VERSION ""

NS_ :

BS_:

BU_: VCU EAC EDS EPS BMS DCDC EVCC OBC

BO_ 374 BMS_HVMeas1_0x176: 8 BMS
 SG_ Checksum_0x176 : 7|8@0+ (1,0) [0|255] ""  VCU,EDS,EVCC
 SG_ Rolling_Counter_0x176 : 11|4@0+ (1,0) [0|15] ""  VCU,EDS,EVCC
 SG_ BMS_HVLinkVol_MEAS : 39|16@0+ (0.1,0) [0|800] "V"  VCU,EVCC
 SG_ BMS_HVPackVol_MEAS : 23|16@0+ (0.1,0) [0|800] "V"  VCU,EDS,EVCC

BO_ 375 BMS_HVMeas2_0x177: 8 BMS
 SG_ Checksum_0x177 : 7|8@0+ (1,0) [0|255] ""  VCU,EVCC
 SG_ Rolling_Counter_0x177 : 11|4@0+ (1,0) [0|15] ""  VCU,EVCC
 SG_ BMS_HVBusVol_MEAS : 23|16@0+ (0.1,0) [0|800] "V"  VCU,EVCC
 SG_ BMS_HVFuseVol_MEAS : 39|16@0+ (0.1,0) [0|800] "V"  VCU,EVCC

BO_ 372 BMS_CurMeas_0x174: 8 BMS
 SG_ Checksum_0x174 : 7|8@0+ (1,0) [0|255] ""  VCU,EVCC
 SG_ Rolling_Counter_0x174 : 11|4@0+ (1,0) [0|15] ""  VCU,EVCC
 SG_ BMS_PackCur_MEAS : 23|16@0+ (0.1,-3276.8) [-3276.8|3276.7] "A"  VCU,EVCC
 SG_ BMS_AllowDischgCurr : 39|16@0+ (0.1,0) [0|1500] "A"  VCU,EVCC
 SG_ BMS_AllowDischgCurrPeak : 55|16@0+ (0.1,0) [0|1500] "A"  VCU,EVCC

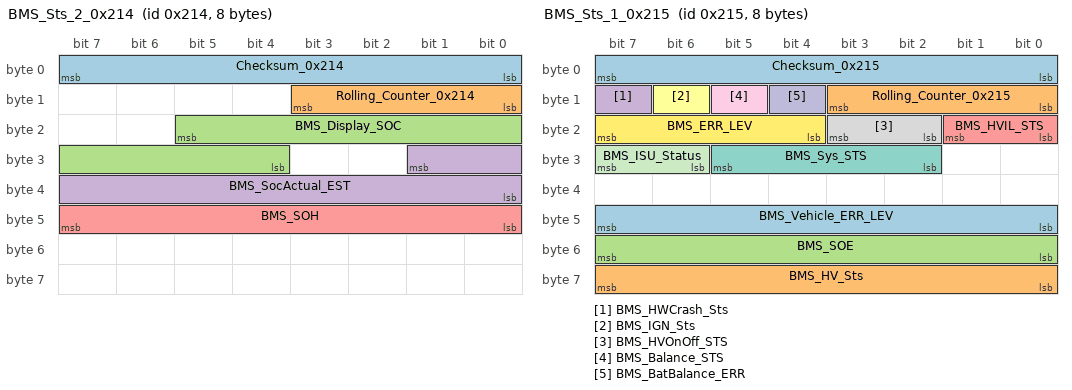
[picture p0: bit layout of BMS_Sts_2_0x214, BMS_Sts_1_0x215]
BO_ 532 BMS_Sts_2_0x214: 8 BMS
 SG_ Checksum_0x214 : 7|8@0+ (1,0) [0|255] ""  VCU,EVCC
 SG_ Rolling_Counter_0x214 : 11|4@0+ (1,0) [0|15] ""  VCU,EVCC
 SG_ BMS_Display_SOC : 21|10@0+ (0.1,0) [0|100] "%"  VCU,EVCC
 SG_ BMS_SocActual_EST : 25|10@0+ (0.1,0) [0|100] "percent"  VCU,EDS,EVCC
 SG_ BMS_SOH : 47|8@0+ (0.5,0) [0|100] "%"  VCU,EDS,EVCC

BO_ 533 BMS_Sts_1_0x215: 8 BMS
 SG_ Checksum_0x215 : 7|8@0+ (1,0) [0|255] ""  VCU,EDS,DCDC,EVCC
 SG_ Rolling_Counter_0x215 : 11|4@0+ (1,0) [0|15] ""  VCU,EDS,DCDC,EVCC
 SG_ BMS_SOE : 55|8@0+ (0.5,0) [0|100] "%"  VCU,EVCC
 SG_ BMS_HWCrash_Sts : 15|1@0+ (1,0) [0|1] ""  VCU,DCDC,EVCC
 SG_ BMS_HVIL_STS : 17|2@0+ (1,0) [0|3] ""  VCU,EDS,DCDC,EVCC
 SG_ BMS_IGN_Sts : 14|1@0+ (1,0) [0|1] ""  VCU,EDS,EVCC
 SG_ BMS_Sys_STS : 29|4@0+ (1,0) [0|15] ""  VCU,EDS,EVCC
 SG_ BMS_HVOnOff_STS : 19|2@0+ (1,0) [0|3] ""  VCU,EDS,DCDC,EVCC
 SG_ BMS_Balance_STS : 13|1@0+ (1,0) [0|1] ""  VCU,EDS,EVCC
 SG_ BMS_BatBalance_ERR : 12|1@0+ (1,0) [0|1] ""  VCU,EDS,EVCC
 SG_ BMS_ISU_Status : 31|2@0+ (1,0) [0|3] ""  VCU,EDS,EVCC
 SG_ BMS_ERR_LEV : 23|4@0+ (1,0) [0|15] ""  VCU,EDS,EVCC
 SG_ BMS_Vehicle_ERR_LEV : 47|8@0+ (1,0) [0|15] ""  VCU,EDS,EVCC
 SG_ BMS_HV_Sts : 63|8@0+ (1,0) [0|255] ""  VCU,EVCC

BO_ 549 BMS_FaultMgr_0x225: 8 BMS
 SG_ Checksum_0x225 : 7|8@0+ (1,0) [0|255] ""  VCU,EVCC
 SG_ Rolling_Counter_0x225 : 11|4@0+ (1,0) [0|15] ""  VCU,EVCC
 SG_ CDM_bAcvCanComStblMon : 12|1@0+ (1,0) [0|1] ""  VCU,EVCC
 SG_ FRMo_bErrHvbatStReqExtMon : 13|1@0+ (1,0) [0|1] ""  VCU,EVCC
 SG_ FRMo_bErrChrgnAllwdExtMon : 14|1@0+ (1,0) [0|1] ""  VCU,EVCC
 SG_ FRMo_bErrVehCrashStExtMon : 15|1@0+ (1,0) [0|1] ""  VCU,EVCC
 SG_ CDM_bErrComctnLossCanMon : 16|1@0+ (1,0) [0|1] ""  VCU,EVCC
 SG_ CTCMon_bErrCtctrSopcMon : 17|1@0+ (1,0) [0|1] ""  VCU,EVCC
 SG_ CTCMon_bInvldCtctrHisdIFbMon : 18|1@0+ (1,0) [0|1] ""  VCU,EVCC
 SG_ CTCMon_bInvldCtctrLosdUFbMon : 19|1@0+ (1,0) [0|1] ""  VCU,EVCC
 SG_ CTM_bErrCellTDifMaxMon : 20|1@0+ (1,0) [0|1] ""  VCU,EVCC
 SG_ CTM_bErrCellTMaxMon : 21|1@0+ (1,0) [0|1] ""  VCU,EVCC
 SG_ CTM_bErrCellTMinMon : 22|1@0+ (1,0) [0|1] ""  VCU,EVCC
 SG_ CTM_bErrThrwyPredMon : 23|1@0+ (1,0) [0|1] ""  VCU,EVCC
 SG_ CUM_bErrCellUDifMaxMon : 24|1@0+ (1,0) [0|1] ""  VCU,EVCC
 SG_ CUM_bErrCellUMaxMon : 25|1@0+ (1,0) [0|1] ""  VCU,EVCC
 SG_ CUM_bErrCellUMinMon : 26|1@0+ (1,0) [0|1] ""  VCU,EVCC
 SG_ CUM_bErrCellUProtnMaxNvMon : 27|1@0+ (1,0) [0|1] ""  VCU,EVCC
 SG_ CUM_bErrCellUProtnMinNvMon : 28|1@0+ (1,0) [0|1] ""  VCU,EVCC
 SG_ CUM_bErrPackUImplyMon : 29|1@0+ (1,0) [0|1] ""  VCU,EVCC
 SG_ EHPMon_bRdyHvilMon : 30|1@0+ (1,0) [0|1] ""  VCU,EVCC
 SG_ EHPMon_bErrWlddNegNvMon : 31|1@0+ (1,0) [0|1] ""  VCU,EVCC
 SG_ EHPMon_bErrWlddPosNvMon : 32|1@0+ (1,0) [0|1] ""  VCU,EVCC
 SG_ EHPMon_bErrWlddPrechNvMon : 33|1@0+ (1,0) [0|1] ""  VCU,EVCC
 SG_ EHPMon_bErrHvilMon : 34|1@0+ (1,0) [0|1] ""  VCU,EVCC
 SG_ EHPMon_bErrHvilShoMon : 35|1@0+ (1,0) [0|1] ""  VCU,EVCC
 SG_ EHPMon_bErrPackIslnRNvMon : 36|1@0+ (1,0) [0|1] ""  VCU,EVCC
 SG_ EHPMon_bErrVehCrashNvMon : 37|1@0+ (1,0) [0|1] ""  VCU,EVCC
 SG_ EHPMon_bErrVehIslnRNvMon : 38|1@0+ (1,0) [0|1] ""  VCU,EVCC
 SG_ FRMo_bErrMemStorgNvMon : 39|1@0+ (1,0) [0|1] ""  VCU,EVCC
 SG_ L1IM_bErrClmp30MaxMonInp : 40|1@0+ (1,0) [0|1] ""  VCU,EVCC
 SG_ L1IM_bErrClmp30MinMonInp : 41|1@0+ (1,0) [0|1] ""  VCU,EVCC
 SG_ L1IM_bErrCtctrDtrtMonInp : 42|1@0+ (1,0) [0|1] ""  VCU,EVCC
 SG_ L1IM_bErrUActImplyMonInp : 43|1@0+ (1,0) [0|1] ""  VCU,EVCC
 SG_ MCCM_bAcvMdulCtlrStsMon : 44|1@0+ (1,0) [0|1] ""  VCU,EVCC
 SG_ MCCM_bErrLntecSngFltMon : 45|1@0+ (1,0) [0|1] ""  VCU,EVCC
 SG_ MCCM_bErrLntecLtntFltMon : 46|1@0+ (1,0) [0|1] ""  VCU,EVCC
 SG_ MCCM_bErrMdulCellSnsrCfgMon : 47|1@0+ (1,0) [0|1] ""  VCU,EVCC
 SG_ MCCM_bErrMdulCtlrComMon : 48|1@0+ (1,0) [0|1] ""  VCU,EVCC
 SG_ MCCM_bErrSnsrTEltlMon : 49|1@0+ (1,0) [0|1] ""  VCU,EVCC
 SG_ MCCM_bWarnSnsrTEltlMon : 50|1@0+ (1,0) [0|1] ""  VCU,EVCC
 SG_ PCM_bRdySnsrIMon : 51|1@0+ (1,0) [0|1] ""  VCU,EVCC
 SG_ PCM_bErrPackEFlowMaxLimMon : 52|1@0+ (1,0) [0|1] ""  VCU,EVCC
 SG_ PCM_bErrPackIChDchaMaxLimMon : 53|1@0+ (1,0) [0|1] ""  VCU,EVCC
 SG_ PCM_bErrSnsrIImplyMon : 54|1@0+ (1,0) [0|1] ""  VCU,EVCC
 SG_ FRMo_bErrSnsrI1ExtMon : 55|1@0+ (1,0) [0|1] ""  VCU,EVCC
 SG_ PCM_bInvldSnsrI1Mon : 56|1@0+ (1,0) [0|1] ""  VCU,EVCC
 SG_ PCM_bInvldSnsrI2Mon : 57|1@0+ (1,0) [0|1] ""  VCU,EVCC
 SG_ FRMo_bErrSopcLvl3Mon : 58|1@0+ (1,0) [0|1] ""  VCU,EVCC
 SG_ BMS_FRMo_Reserved_1 : 59|1@0+ (1,0) [0|1] ""  VCU,EVCC
 SG_ BMS_FRMo_Reserved_2 : 60|1@0+ (1,0) [0|1] ""  VCU,EVCC
 SG_ BMS_FRMo_Reserved_3 : 61|1@0+ (1,0) [0|1] ""  VCU,EVCC
 SG_ BMS_FRMo_Reserved_4 : 62|1@0+ (1,0) [0|1] ""  VCU,EVCC
 SG_ BMS_FRMo_Reserved_5 : 63|1@0+ (1,0) [0|1] ""  VCU,EVCC

BO_ 293 BMS_Power_0x125: 8 BMS
 SG_ Checksum_0x125 : 7|8@0+ (1,0) [0|255] ""  VCU,EVCC
 SG_ Rolling_Counter_0x125 : 11|4@0+ (1,0) [0|15] ""  VCU,EVCC
 SG_ BMS_Actual_ChgPower : 38|15@0+ (0.01,0) [0|100] "Kw"  VCU,EVCC
 SG_ BMS_Actual_DisChgPower : 54|15@0+ (0.01,0) [0|100] "Kw"  VCU,EVCC

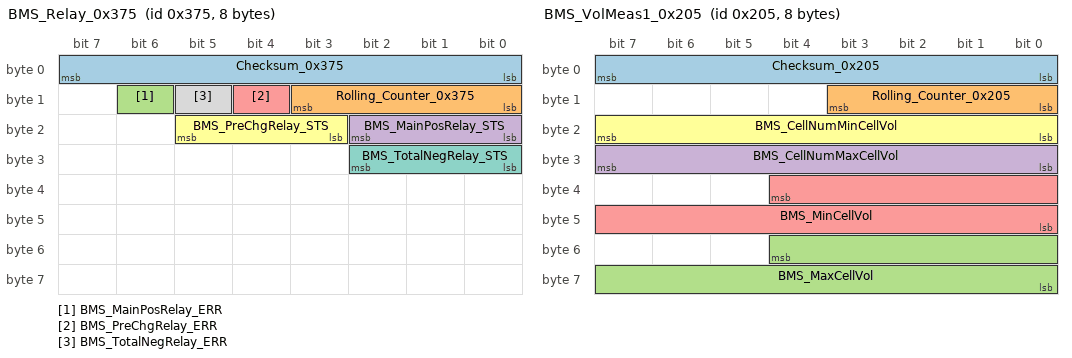
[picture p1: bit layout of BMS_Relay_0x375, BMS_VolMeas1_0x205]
BO_ 885 BMS_Relay_0x375: 8 BMS
 SG_ Checksum_0x375 : 7|8@0+ (1,0) [0|255] ""  VCU,EDS,EVCC
 SG_ Rolling_Counter_0x375 : 11|4@0+ (1,0) [0|15] ""  VCU,EDS,EVCC
 SG_ BMS_MainPosRelay_ERR : 14|1@0+ (1,0) [0|1] ""  VCU,EDS,EVCC
 SG_ BMS_MainPosRelay_STS : 18|3@0+ (1,0) [0|7] ""  VCU,EDS,EVCC
 SG_ BMS_PreChgRelay_ERR : 12|1@0+ (1,0) [0|1] ""  VCU,EVCC
 SG_ BMS_PreChgRelay_STS : 21|3@0+ (1,0) [0|7] ""  VCU,EVCC
 SG_ BMS_TotalNegRelay_STS : 26|3@0+ (1,0) [0|7] ""  VCU,EVCC
 SG_ BMS_TotalNegRelay_ERR : 13|1@0+ (1,0) [0|1] ""  VCU,EVCC

BO_ 517 BMS_VolMeas1_0x205: 8 BMS
 SG_ Checksum_0x205 : 7|8@0+ (1,0) [0|255] ""  VCU
 SG_ Rolling_Counter_0x205 : 11|4@0+ (1,0) [0|15] ""  VCU
 SG_ BMS_MaxCellVol : 52|13@0+ (0.001,0) [0|6] "V"  VCU
 SG_ BMS_CellNumMaxCellVol : 31|8@0+ (1,0) [0|255] ""  VCU
 SG_ BMS_MinCellVol : 36|13@0+ (0.001,0) [0|6] "V"  VCU
 SG_ BMS_CellNumMinCellVol : 23|8@0+ (1,0) [0|255] ""  VCU

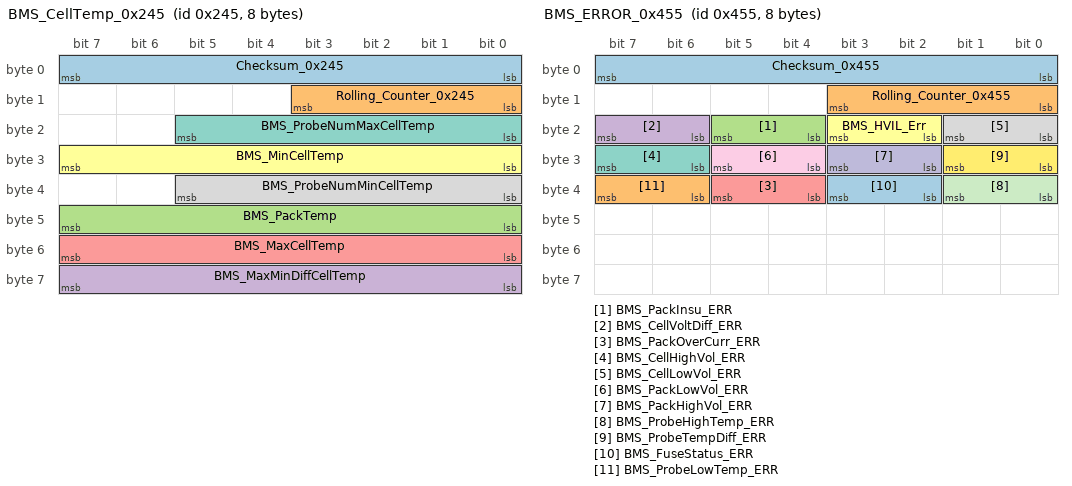
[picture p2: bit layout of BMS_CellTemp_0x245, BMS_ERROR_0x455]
BO_ 581 BMS_CellTemp_0x245: 8 BMS
 SG_ Checksum_0x245 : 7|8@0+ (1,0) [0|255] ""  VCU
 SG_ Rolling_Counter_0x245 : 11|4@0+ (1,0) [0|15] ""  VCU
 SG_ BMS_PackTemp : 47|8@0+ (1,-40) [-40|215] "degree" Vector__XXX
 SG_ BMS_MaxMinDiffCellTemp : 63|8@0+ (1,-40) [-40|215] "degree" Vector__XXX
 SG_ BMS_MaxCellTemp : 55|8@0+ (1,-40) [-40|215] "degree" Vector__XXX
 SG_ BMS_MinCellTemp : 31|8@0+ (1,-40) [-40|215] "degree" Vector__XXX
 SG_ BMS_ProbeNumMaxCellTemp : 21|6@0+ (1,0) [0|63] ""  VCU
 SG_ BMS_ProbeNumMinCellTemp : 37|6@0+ (1,0) [0|63] ""  VCU

BO_ 773 BMS_Insulation_0x305: 8 BMS
 SG_ Checksum_0x305 : 7|8@0+ (1,0) [0|255] ""  VCU,EVCC
 SG_ Rolling_Counter_0x305 : 11|4@0+ (1,0) [0|15] ""  VCU,EVCC
 SG_ BMS_VCU_Insulation_Mon_Sts : 15|1@0+ (1,0) [0|1] ""  VCU,EVCC
 SG_ BMS_PackInsuRes : 23|16@0+ (1,0) [0|60000] "kOhm"  VCU,EVCC

BO_ 1171 BMS_WarnMsg_0x493: 8 BMS
 SG_ BMS_Warning_Flag_Reserved_08 : 16|1@0+ (1,0) [0|1] ""  VCU,EVCC
 SG_ BMS_Warning_Flag_Reserved_07 : 17|1@0+ (1,0) [0|1] ""  VCU,EVCC
 SG_ BMS_Warning_Flag_Reserved_11 : 47|8@0+ (1,0) [0|255] ""  VCU,EVCC
 SG_ BMS_Warning_Flag_Reserved_10 : 39|8@0+ (1,0) [0|255] ""  VCU,EVCC
 SG_ BMS_Warning_Flag_Reserved_09 : 31|8@0+ (1,0) [0|255] ""  VCU,EVCC
 SG_ BMS_Warning_Flag_Reserved_13 : 63|8@0+ (1,0) [0|255] ""  VCU,EVCC
 SG_ BMS_Warning_Flag_Reserved_12 : 55|8@0+ (1,0) [0|255] ""  VCU,EVCC
 SG_ BMS_Warning_Flag_Reserved_06 : 18|1@0+ (1,0) [0|1] ""  VCU,EVCC
 SG_ BMS_Warning_Flag_Reserved_05 : 19|1@0+ (1,0) [0|1] ""  VCU,EVCC
 SG_ BMS_Warning_Flag_Reserved_04 : 20|1@0+ (1,0) [0|1] ""  VCU,EVCC
 SG_ BMS_MalfunctionSts : 21|1@0+ (1,0) [0|1] ""  VCU,EVCC
 SG_ BMS_LowBattery : 23|2@0+ (1,0) [0|3] ""  VCU,EVCC
 SG_ BMS_BatteryReplacement : 15|1@0+ (1,0) [0|1] ""  VCU,EVCC
 SG_ BMS_PackTempSts : 13|2@0+ (1,0) [0|3] ""  VCU,EVCC
 SG_ BMS_ThermalRunaway : 14|1@0+ (1,0) [0|1] ""  VCU,EVCC
 SG_ Rolling_Counter_0x493 : 11|4@0+ (1,0) [0|15] ""  VCU,EVCC
 SG_ Checksum_0x493 : 7|8@0+ (1,0) [0|255] ""  VCU,EVCC

BO_ 1109 BMS_ERROR_0x455: 8 BMS
 SG_ Checksum_0x455 : 7|8@0+ (1,0) [0|255] ""  VCU,EVCC
 SG_ Rolling_Counter_0x455 : 11|4@0+ (1,0) [0|15] ""  VCU,EVCC
 SG_ BMS_PackInsu_ERR : 21|2@0+ (1,0) [0|3] ""  VCU,EVCC
 SG_ BMS_CellVoltDiff_ERR : 23|2@0+ (1,0) [0|3] ""  VCU,EVCC
 SG_ BMS_PackOverCurr_ERR : 37|2@0+ (1,0) [0|3] ""  VCU,EVCC
 SG_ BMS_HVIL_Err : 19|2@0+ (1,0) [0|3] ""  VCU,EVCC
 SG_ BMS_CellHighVol_ERR : 31|2@0+ (1,0) [0|3] ""  VCU,EVCC
 SG_ BMS_CellLowVol_ERR : 17|2@0+ (1,0) [0|3] ""  VCU,EVCC
 SG_ BMS_PackLowVol_ERR : 29|2@0+ (1,0) [0|3] ""  VCU,EVCC
 SG_ BMS_PackHighVol_ERR : 27|2@0+ (1,0) [0|3] ""  VCU,EVCC
 SG_ BMS_ProbeHighTemp_ERR : 33|2@0+ (1,0) [0|3] ""  VCU,EVCC
 SG_ BMS_ProbeTempDiff_ERR : 25|2@0+ (1,0) [0|3] ""  VCU,EVCC
 SG_ BMS_FuseStatus_ERR : 35|2@0+ (1,0) [0|1] ""  VCU,EVCC
 SG_ BMS_ProbeLowTemp_ERR : 39|2@0+ (1,0) [0|3] ""  VCU,EVCC

BO_ 1504 Test1_BMS_CellVoltage_0x5E0: 8 BMS
 SG_ BMS_Voltage_FrameNumber : 7|8@0+ (1,0) [0|255] "" Vector__XXX
 SG_ BMS_Voltage_Value1 : 15|16@0+ (1,0) [0|5000] "" Vector__XXX
 SG_ BMS_Voltage_Value2 : 31|16@0+ (1,0) [0|5000] "" Vector__XXX
 SG_ BMS_Voltage_Value3 : 47|16@0+ (1,0) [0|5000] "" Vector__XXX
 SG_ softwore_version : 63|8@0+ (1,0) [0|255] "" Vector__XXX

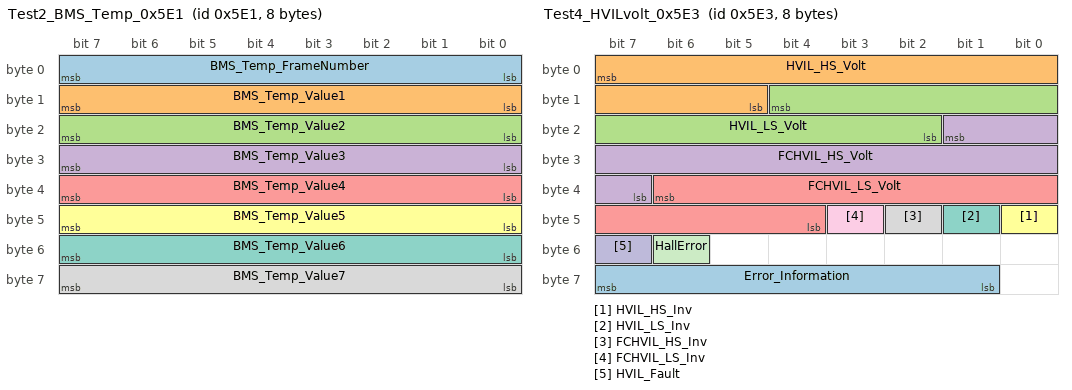
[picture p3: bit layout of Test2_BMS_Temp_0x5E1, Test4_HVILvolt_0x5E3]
BO_ 1505 Test2_BMS_Temp_0x5E1: 8 BMS
 SG_ BMS_Temp_FrameNumber : 7|8@0+ (1,0) [1|255] "" Vector__XXX
 SG_ BMS_Temp_Value1 : 15|8@0+ (1,-40) [-40|215] "" Vector__XXX
 SG_ BMS_Temp_Value2 : 23|8@0+ (1,-40) [-40|215] "" Vector__XXX
 SG_ BMS_Temp_Value3 : 31|8@0+ (1,-40) [-40|215] "" Vector__XXX
 SG_ BMS_Temp_Value4 : 39|8@0+ (1,-40) [-40|215] "" Vector__XXX
 SG_ BMS_Temp_Value5 : 47|8@0+ (1,-40) [-40|215] "" Vector__XXX
 SG_ BMS_Temp_Value6 : 55|8@0+ (1,-40) [-40|215] "" Vector__XXX
 SG_ BMS_Temp_Value7 : 63|8@0+ (1,-40) [-40|215] "" Vector__XXX

BO_ 1506 Test3_BMS_DTC_0x5E2: 8 BMS
 SG_ BMS_Test_Runaway : 7|16@0+ (1,0) [0|255] "" Vector__XXX
 SG_ BMS_Test_shunt_Temp : 23|16@0+ (1,-40) [-40|65535] "" Vector__XXX
 SG_ BMS_Test_V4_Volt : 39|16@0+ (1,0) [0|65535] "V" Vector__XXX
 SG_ BMS_Test_L2ErrNum : 55|16@0+ (1,0) [0|65535] "" Vector__XXX

BO_ 1507 Test4_HVILvolt_0x5E3: 8 BMS
 SG_ Error_Information : 63|7@0+ (1,0) [0|127] "" Vector__XXX
 SG_ HVIL_HS_Volt : 7|11@0+ (0.01,0) [0|20] "V" Vector__XXX
 SG_ HVIL_LS_Volt : 12|11@0+ (0.01,0) [0|20] "V" Vector__XXX
 SG_ FCHVIL_HS_Volt : 17|11@0+ (0.01,0) [0|20] "V" Vector__XXX
 SG_ FCHVIL_LS_Volt : 38|11@0+ (0.01,0) [0|20] "V" Vector__XXX
 SG_ HVIL_HS_Inv : 40|1@0+ (1,0) [0|0] "" Vector__XXX
 SG_ HVIL_LS_Inv : 41|1@0+ (1,0) [0|0] "" Vector__XXX
 SG_ FCHVIL_HS_Inv : 42|1@0+ (1,0) [0|0] "" Vector__XXX
 SG_ FCHVIL_LS_Inv : 43|1@0+ (1,0) [0|0] "" Vector__XXX
 SG_ HVIL_Fault : 55|1@0+ (1,0) [0|0] "" Vector__XXX
 SG_ HallError : 54|1@0+ (1,0) [0|0] "" Vector__XXX

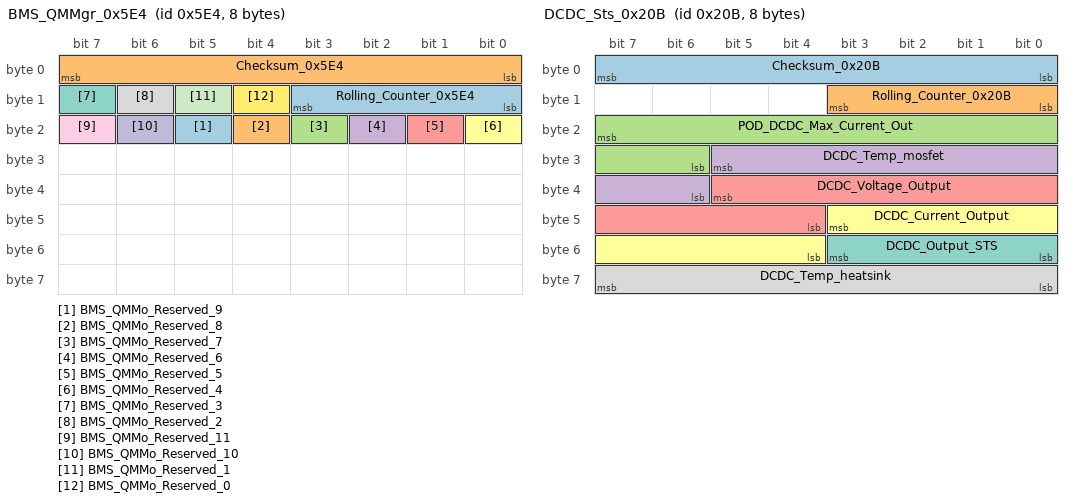
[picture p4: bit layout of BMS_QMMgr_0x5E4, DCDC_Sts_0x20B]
BO_ 1508 BMS_QMMgr_0x5E4: 8 BMS
 SG_ BMS_QMMo_Reserved_9 : 21|1@0+ (1,0) [0|1] "" Vector__XXX
 SG_ BMS_QMMo_Reserved_8 : 20|1@0+ (1,0) [0|1] "" Vector__XXX
 SG_ BMS_QMMo_Reserved_7 : 19|1@0+ (1,0) [0|1] "" Vector__XXX
 SG_ BMS_QMMo_Reserved_6 : 18|1@0+ (1,0) [0|1] "" Vector__XXX
 SG_ BMS_QMMo_Reserved_5 : 17|1@0+ (1,0) [0|1] "" Vector__XXX
 SG_ BMS_QMMo_Reserved_4 : 16|1@0+ (1,0) [0|1] "" Vector__XXX
 SG_ BMS_QMMo_Reserved_3 : 15|1@0+ (1,0) [0|1] "" Vector__XXX
 SG_ BMS_QMMo_Reserved_2 : 14|1@0+ (1,0) [0|1] "" Vector__XXX
 SG_ BMS_QMMo_Reserved_11 : 23|1@0+ (1,0) [0|1] "" Vector__XXX
 SG_ BMS_QMMo_Reserved_10 : 22|1@0+ (1,0) [0|1] "" Vector__XXX
 SG_ BMS_QMMo_Reserved_1 : 13|1@0+ (1,0) [0|1] "" Vector__XXX
 SG_ BMS_QMMo_Reserved_0 : 12|1@0+ (1,0) [0|1] "" Vector__XXX
 SG_ Rolling_Counter_0x5E4 : 11|4@0+ (1,0) [0|15] "" Vector__XXX
 SG_ Checksum_0x5E4 : 7|8@0+ (1,0) [0|255] "" Vector__XXX

BO_ 523 DCDC_Sts_0x20B: 8 DCDC
 SG_ Checksum_0x20B : 7|8@0+ (1,0) [0|255] ""  VCU,BMS,EVCC
 SG_ Rolling_Counter_0x20B : 11|4@0+ (1,0) [0|15] ""  VCU,BMS,EVCC
 SG_ POD_DCDC_Max_Current_Out : 23|10@0+ (1,0) [0|1000] "A"  VCU,BMS,EVCC
 SG_ DCDC_Temp_mosfet : 29|8@0+ (1,-40) [-40|215] ""  EVCC
 SG_ DCDC_Voltage_Output : 37|10@0+ (0.1,0) [0|40] "V"  VCU,BMS,EVCC
 SG_ DCDC_Current_Output : 43|8@0+ (1,0) [0|255] "A"  VCU,BMS,EVCC
 SG_ DCDC_Output_STS : 51|4@0+ (1,0) [0|15] ""  VCU,BMS,EVCC
 SG_ DCDC_Temp_heatsink : 63|8@0+ (1,-40) [-40|215] ""  EVCC

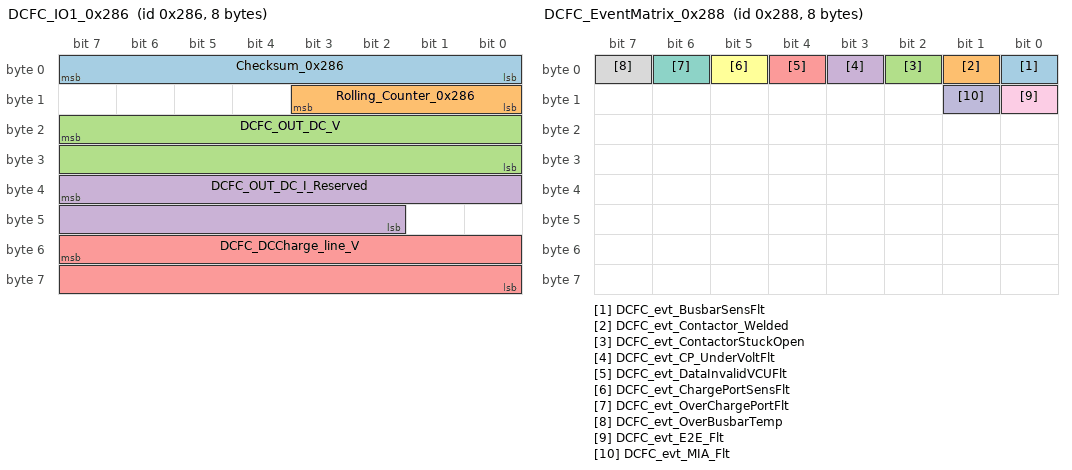
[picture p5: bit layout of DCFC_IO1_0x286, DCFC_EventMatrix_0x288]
BO_ 646 DCFC_IO1_0x286: 8 DCDC
 SG_ Checksum_0x286 : 7|8@0+ (1,0) [0|255] ""  VCU,BMS,EVCC,OBC
 SG_ Rolling_Counter_0x286 : 11|4@0+ (1,0) [0|15] ""  VCU,BMS,EVCC,OBC
 SG_ DCFC_OUT_DC_V : 23|16@0+ (0.1,0) [0|6553.5] "V"  VCU,BMS,EVCC,OBC
 SG_ DCFC_OUT_DC_I_Reserved : 39|14@0+ (0.1,0) [0|1000] "A"  VCU,BMS,EVCC,OBC
 SG_ DCFC_DCCharge_line_V : 55|16@0+ (0.1,0) [0|6553.5] "V"  VCU,BMS,EVCC,OBC

BO_ 647 DCDC_EventMatrix_0x287: 8 DCDC
 SG_ DCDC_evt_BUS_OFF : 0|1@0+ (1,0) [0|1] ""  VCU
 SG_ DCDC_evt_MIA : 1|1@0+ (1,0) [0|1] ""  VCU
 SG_ DCDC_evt_E2E : 2|1@0+ (1,0) [0|1] ""  VCU
 SG_ DCDC_evt_Calibration_Flt : 3|1@0+ (1,0) [0|1] ""  VCU
 SG_ DCDC_evt_flash_Failure : 4|1@0+ (1,0) [0|1] ""  VCU
 SG_ DCDC_evt_FaultLatchCircuit : 5|1@0+ (1,0) [0|1] ""  VCU
 SG_ DCDC_evt_HV_VoltSensFlt : 6|1@0+ (1,0) [0|1] ""  VCU
 SG_ DCDC_evt_HV_OverVoltFlt : 7|1@0+ (1,0) [0|1] ""  VCU
 SG_ DCDC_evt_HV_UnderVoltFlt : 8|1@0+ (1,0) [0|1] ""  VCU
 SG_ DCDC_evt_LV_VoltSensFlt : 9|1@0+ (1,0) [0|1] ""  VCU
 SG_ DCDC_evt_LVBatt_OverVoltFlt : 10|1@0+ (1,0) [0|1] ""  VCU
 SG_ DCDC_evt_LVBatt_UnderVoltFlt : 11|1@0+ (1,0) [0|1] ""  VCU
 SG_ DCDC_evt_LVBatt_SensorFlt : 12|1@0+ (1,0) [0|1] ""  VCU
 SG_ DCDC_evt_LV_RedundancyFlt : 13|1@0+ (1,0) [0|1] ""  VCU
 SG_ DCDC_evt_LV_CurrSensFlt : 14|1@0+ (1,0) [0|1] ""  VCU
 SG_ DCDC_evt_LV_OverCurr : 15|1@0+ (1,0) [0|1] ""  VCU
 SG_ DCDC_evt_ReverseCurrFlt : 16|1@0+ (1,0) [0|1] ""  VCU
 SG_ DCDC_evt_Heater_TempSensorFlt : 17|1@0+ (1,0) [0|1] ""  VCU
 SG_ DCDC_evt_Mosfet_TempSensorFlt : 18|1@0+ (1,0) [0|1] ""  VCU
 SG_ DCDC_evt_Mosfet_OverTemp : 19|1@0+ (1,0) [0|1] ""  VCU
 SG_ DCDC_evt_HeatSink_TempSensorFlt : 20|1@0+ (1,0) [0|1] ""  VCU
 SG_ DCDC_evt_HeatSink_OverTemp : 21|1@0+ (1,0) [0|1] ""  VCU
 SG_ DCDC_evt_Heater_OverTempFlt : 22|1@0+ (1,0) [0|1] ""  VCU
 SG_ DCDC_evt_Heater_ShortIGBTFlt : 23|1@0+ (1,0) [0|1] ""  VCU
 SG_ DCDC_evt_LV_ShortOutputFlt : 24|1@0+ (1,0) [0|1] ""  VCU
 SG_ DCDC_evt_sw_BMS_CrashFlt : 25|1@0+ (1,0) [0|1] ""  VCU
 SG_ DCDC_evt_BMS_HVILFlt : 26|1@0+ (1,0) [0|1] ""  VCU

BO_ 648 DCFC_EventMatrix_0x288: 8 DCDC
 SG_ DCFC_evt_BusbarSensFlt : 0|1@0+ (1,0) [0|1] ""  VCU,EVCC
 SG_ DCFC_evt_Contactor_Welded : 1|1@0+ (1,0) [0|1] ""  VCU,EVCC
 SG_ DCFC_evt_ContactorStuckOpen : 2|1@0+ (1,0) [0|1] ""  VCU,EVCC
 SG_ DCFC_evt_CP_UnderVoltFlt : 3|1@0+ (1,0) [0|1] ""  VCU,EVCC
 SG_ DCFC_evt_DataInvalidVCUFlt : 4|1@0+ (1,0) [0|1] ""  VCU,EVCC
 SG_ DCFC_evt_ChargePortSensFlt : 5|1@0+ (1,0) [0|1] ""  VCU,EVCC
 SG_ DCFC_evt_OverChargePortFlt : 6|1@0+ (1,0) [0|1] ""  VCU,EVCC
 SG_ DCFC_evt_OverBusbarTemp : 7|1@0+ (1,0) [0|1] ""  VCU,EVCC
 SG_ DCFC_evt_E2E_Flt : 8|1@0+ (1,0) [0|1] ""  VCU,EVCC
 SG_ DCFC_evt_MIA_Flt : 9|1@0+ (1,0) [0|1] ""  VCU,EVCC

BO_ 1030 Error_Level_DCDC_0x406: 8 DCDC
 SG_ Checksum_0x406 : 7|8@0+ (1,0) [0|255] ""  VCU,EVCC
 SG_ Rolling_Counter_0x406 : 11|4@0+ (1,0) [0|15] ""  VCU,EVCC
 SG_ DCDC_FaultLevel : 19|4@0+ (1,0) [0|15] ""  VCU,EVCC
 SG_ DCFC_FaultLevel : 23|4@0+ (1,0) [0|15] ""  VCU,EVCC

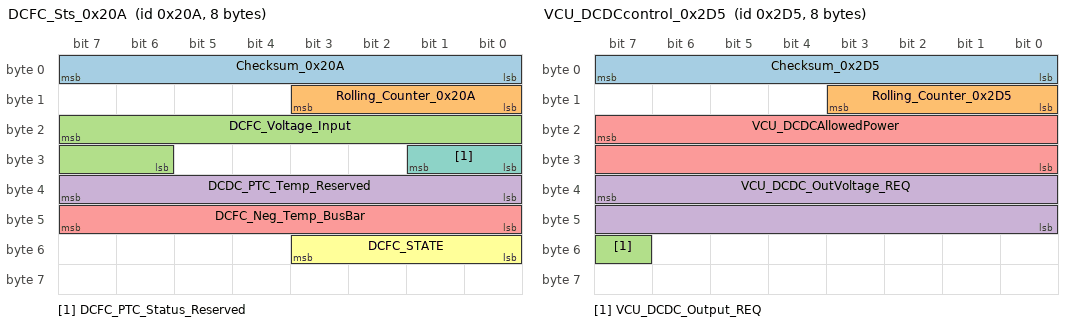
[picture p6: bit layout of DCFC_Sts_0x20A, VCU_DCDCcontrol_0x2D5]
BO_ 522 DCFC_Sts_0x20A: 8 DCDC
 SG_ Checksum_0x20A : 7|8@0+ (1,0) [0|255] ""  VCU,EVCC
 SG_ Rolling_Counter_0x20A : 11|4@0+ (1,0) [0|15] ""  VCU,EVCC
 SG_ DCFC_Voltage_Input : 23|10@0+ (1,0) [0|1000] "V"  VCU,EVCC
 SG_ DCDC_PTC_Temp_Reserved : 39|8@0+ (1,-40) [-40|215] "" Vector__XXX
 SG_ DCFC_Neg_Temp_BusBar : 47|8@0+ (1,-40) [-40|215] "" Vector__XXX
 SG_ DCFC_STATE : 51|4@0+ (1,0) [0|15] ""  VCU,EVCC
 SG_ DCFC_PTC_Status_Reserved : 25|2@0+ (1,0) [0|3] ""  VCU,EVCC

BO_ 992 EVCC_HMI_charging_0x3E0: 8 EVCC
 SG_ Checksum_0x3E0 : 7|8@0+ (1,0) [0|255] ""  VCU,BMS
 SG_ Rolling_Counter_0x3E0 : 11|4@0+ (1,0) [0|15] ""  VCU,BMS
 SG_ EVCC_IPC_Ack_ChgSche_stt : 27|2@0+ (1,0) [0|3] ""  VCU,BMS
 SG_ EVCC_IPC_Ack_TargetSOC : 39|8@0+ (1,0) [0|100] "%"  VCU,BMS

BO_ 725 VCU_DCDCcontrol_0x2D5: 8 VCU
 SG_ Checksum_0x2D5 : 7|8@0+ (1,0) [0|255] ""  DCDC
 SG_ Rolling_Counter_0x2D5 : 11|4@0+ (1,0) [0|15] ""  DCDC
 SG_ VCU_DCDC_Output_REQ : 55|1@0+ (1,0) [0|1] ""  DCDC
 SG_ VCU_DCDC_OutVoltage_REQ : 39|16@0+ (0.1,0) [0|16] "V"  DCDC
 SG_ VCU_DCDCAllowedPower : 23|16@0+ (0.1,0) [0|2000] "W"  DCDC

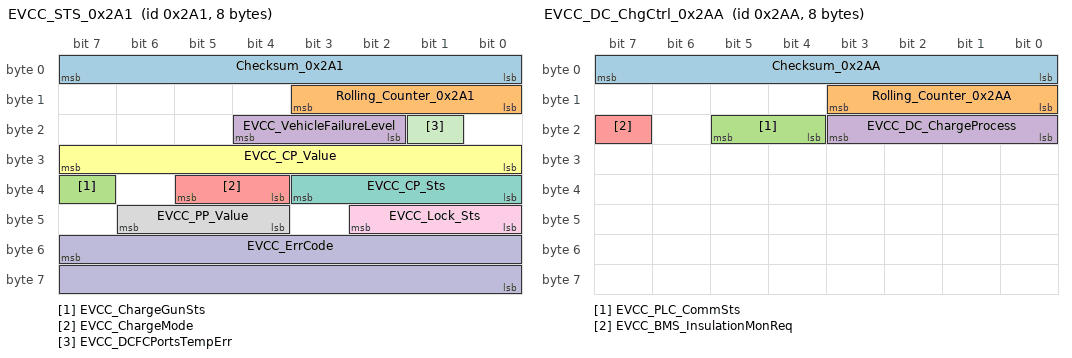
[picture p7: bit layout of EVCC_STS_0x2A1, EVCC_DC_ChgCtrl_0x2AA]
BO_ 673 EVCC_STS_0x2A1: 8 EVCC
 SG_ Checksum_0x2A1 : 7|8@0+ (1,0) [0|255] ""  VCU,BMS
 SG_ Rolling_Counter_0x2A1 : 11|4@0+ (1,0) [0|15] ""  VCU,BMS
 SG_ EVCC_ChargeGunSts : 39|1@0+ (1,0) [0|1] ""  VCU,BMS,OBC
 SG_ EVCC_VehicleFailureLevel : 20|3@0+ (1,0) [0|7] ""  VCU
 SG_ EVCC_ChargeMode : 37|2@0+ (1,0) [0|3] ""  VCU,BMS,OBC
 SG_ EVCC_CP_Value : 31|8@0+ (1,0) [0|100] "%"  VCU,BMS
 SG_ EVCC_CP_Sts : 35|4@0+ (1,0) [0|15] ""  VCU,BMS
 SG_ EVCC_PP_Value : 46|3@0+ (1,0) [0|7] ""  VCU,BMS
 SG_ EVCC_Lock_Sts : 42|3@0+ (1,0) [0|7] ""  VCU,BMS
 SG_ EVCC_ErrCode : 55|16@0+ (1,0) [0|65535] ""  VCU,BMS
 SG_ EVCC_DCFCPortsTempErr : 17|1@0+ (1,0) [0|1] ""  VCU

BO_ 682 EVCC_DC_ChgCtrl_0x2AA: 8 EVCC
 SG_ Checksum_0x2AA : 7|8@0+ (1,0) [0|255] ""  VCU,BMS
 SG_ Rolling_Counter_0x2AA : 11|4@0+ (1,0) [0|15] ""  VCU,BMS
 SG_ EVCC_PLC_CommSts : 21|2@0+ (1,0) [0|3] ""  VCU,BMS
 SG_ EVCC_DC_ChargeProcess : 19|4@0+ (1,0) [0|15] ""  VCU,BMS
 SG_ EVCC_BMS_InsulationMonReq : 23|1@0+ (1,0) [0|1] ""  VCU,BMS

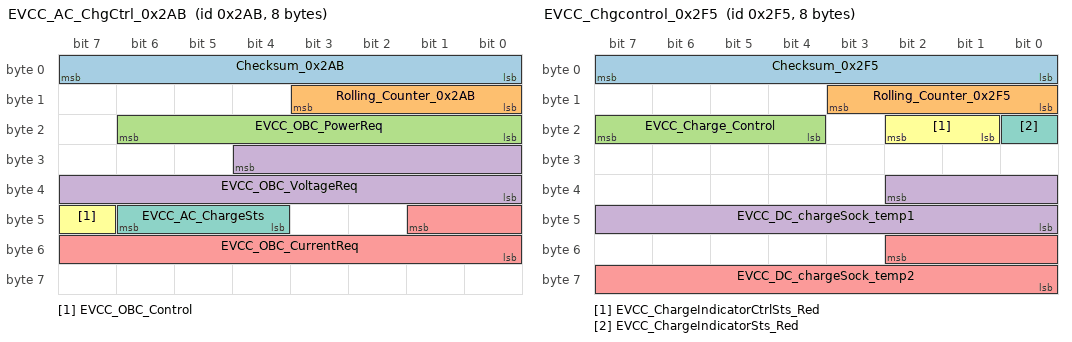
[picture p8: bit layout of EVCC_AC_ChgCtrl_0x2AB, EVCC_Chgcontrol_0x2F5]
BO_ 683 EVCC_AC_ChgCtrl_0x2AB: 8 EVCC
 SG_ Checksum_0x2AB : 7|8@0+ (1,0) [0|255] ""  VCU,BMS,OBC
 SG_ Rolling_Counter_0x2AB : 11|4@0+ (1,0) [0|15] ""  VCU,BMS,OBC
 SG_ EVCC_OBC_PowerReq : 22|7@0+ (0.1,0) [0|10] "kW"  VCU,BMS,OBC
 SG_ EVCC_OBC_VoltageReq : 28|13@0+ (0.1,0) [0|500] "V"  VCU,BMS,OBC
 SG_ EVCC_OBC_CurrentReq : 41|10@0+ (0.1,0) [0|100] "A"  VCU,BMS,OBC
 SG_ EVCC_OBC_Control : 47|1@0+ (1,0) [0|1] ""  VCU,BMS,OBC
 SG_ EVCC_AC_ChargeSts : 46|3@0+ (1,0) [0|7] ""  VCU,BMS,OBC

BO_ 537 EVCC_PT_Control_0x219: 8 EVCC
 SG_ Checksum_0x219 : 7|8@0+ (1,0) [0|255] ""  VCU,BMS
 SG_ Rolling_Counter_0x219 : 11|4@0+ (1,0) [0|15] ""  VCU,BMS
 SG_ EVCC_ChargeAllow : 54|1@0+ (1,0) [0|1] ""  VCU,BMS
 SG_ EVCC_ChrSOCLitFb : 49|10@0+ (0.1,0) [0|1000] "%"  VCU,BMS

BO_ 757 EVCC_Chgcontrol_0x2F5: 8 EVCC
 SG_ Checksum_0x2F5 : 7|8@0+ (1,0) [0|255] ""  VCU,BMS,DCDC
 SG_ Rolling_Counter_0x2F5 : 11|4@0+ (1,0) [0|15] ""  VCU,BMS,DCDC
 SG_ EVCC_Charge_Control : 23|4@0+ (1,0) [0|3] ""  VCU,BMS,DCDC
 SG_ EVCC_DC_chargeSock_temp1 : 34|11@0+ (1,0) [0|2047] "degree"  VCU,BMS,DCDC
 SG_ EVCC_DC_chargeSock_temp2 : 50|11@0+ (1,0) [0|2047] "degree"  VCU,BMS,DCDC
 SG_ EVCC_ChargeIndicatorCtrlSts_Red : 18|2@0+ (1,0) [0|3] ""  VCU
 SG_ EVCC_ChargeIndicatorSts_Red : 16|1@0+ (1,0) [0|1] ""  VCU

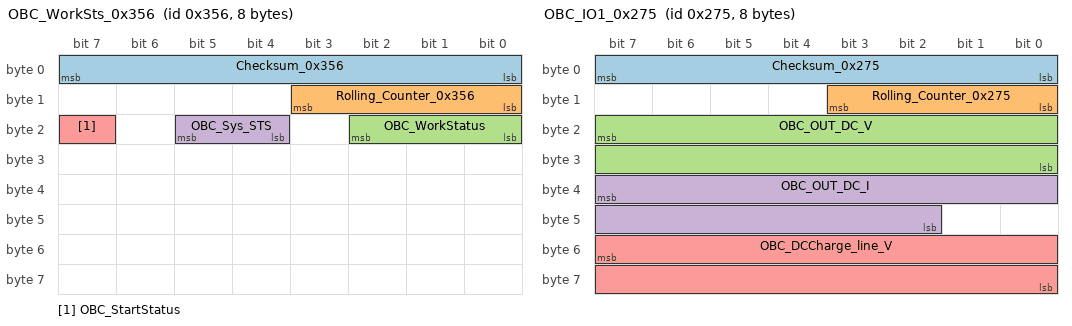
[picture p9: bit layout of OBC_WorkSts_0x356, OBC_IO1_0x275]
BO_ 854 OBC_WorkSts_0x356: 8 OBC
 SG_ Checksum_0x356 : 7|8@0+ (1,0) [0|255] ""  VCU,BMS,EVCC
 SG_ Rolling_Counter_0x356 : 11|4@0+ (1,0) [0|15] ""  VCU,BMS,EVCC
 SG_ OBC_WorkStatus : 18|3@0+ (1,0) [0|7] ""  VCU,BMS,EVCC
 SG_ OBC_Sys_STS : 21|2@0+ (1,0) [0|3] ""  VCU,BMS,EVCC
 SG_ OBC_StartStatus : 23|1@0+ (1,0) [0|1] ""  VCU,BMS,EVCC

BO_ 870 OBC_SystemSts_0x366: 8 OBC
 SG_ Checksum_0x366 : 7|8@0+ (1,0) [0|255] ""  VCU,BMS,EVCC
 SG_ Rolling_Counter_0x366 : 11|4@0+ (1,0) [0|15] ""  VCU,BMS,EVCC
 SG_ OBC_Charge_air_temp : 55|8@0+ (1,-40) [-40|215] "degree"  VCU,BMS,EVCC
 SG_ OBC_Temp : 63|8@0+ (1,-40) [-40|215] "degree"  VCU,BMS,EVCC

BO_ 629 OBC_IO1_0x275: 8 OBC
 SG_ Checksum_0x275 : 7|8@0+ (1,0) [0|255] ""  VCU,BMS,EVCC
 SG_ Rolling_Counter_0x275 : 11|4@0+ (1,0) [0|15] ""  VCU,BMS,EVCC
 SG_ OBC_OUT_DC_V : 23|16@0+ (0.1,0) [0|6553.5] "V"  VCU,BMS,EVCC
 SG_ OBC_OUT_DC_I : 39|14@0+ (0.1,0) [0|1000] "A"  VCU,BMS,EVCC
 SG_ OBC_DCCharge_line_V : 55|16@0+ (0.1,0) [0|6553.5] "V"  VCU,BMS,EVCC

BO_ 630 OBC_IO2_0x276: 8 OBC
 SG_ Checksum_0x276 : 7|8@0+ (1,0) [0|255] ""  VCU,BMS,EVCC
 SG_ Rolling_Counter_0x276 : 11|4@0+ (1,0) [0|15] ""  VCU,BMS,EVCC
 SG_ OBC_Input_U : 39|16@0+ (0.1,0) [0|6553.5] "V"  VCU,BMS,EVCC
 SG_ OBC_IN_Main_V : 23|16@0+ (0.1,0) [0|6553.5] "V"  VCU,BMS,EVCC
 SG_ OBC_IN_Main_I : 55|10@0+ (0.1,0) [0|100] "A"  VCU,BMS,EVCC

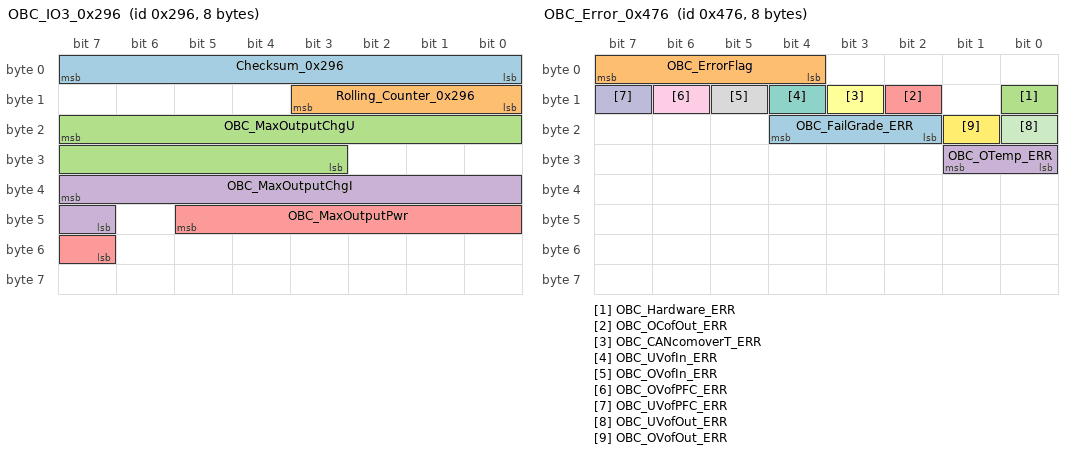
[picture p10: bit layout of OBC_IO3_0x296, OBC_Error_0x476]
BO_ 662 OBC_IO3_0x296: 8 OBC
 SG_ Checksum_0x296 : 7|8@0+ (1,0) [0|255] ""  VCU,BMS,EVCC
 SG_ Rolling_Counter_0x296 : 11|4@0+ (1,0) [0|15] ""  VCU,BMS,EVCC
 SG_ OBC_MaxOutputChgU : 23|13@0+ (0.1,0) [0|500] "V"  VCU,BMS,EVCC
 SG_ OBC_MaxOutputChgI : 39|9@0+ (0.1,0) [0|40] "A"  VCU,BMS,EVCC
 SG_ OBC_MaxOutputPwr : 45|7@0+ (0.1,0) [0|10] "kW"  VCU,BMS,EVCC

BO_ 1142 OBC_Error_0x476: 8 OBC
 SG_ OBC_FailGrade_ERR : 20|3@0+ (1,0) [0|5] ""  VCU,BMS,EVCC
 SG_ OBC_ErrorFlag : 7|4@0+ (1,0) [0|16] ""  VCU,BMS,EVCC
 SG_ OBC_Hardware_ERR : 8|1@0+ (1,0) [0|1] ""  VCU,BMS,EVCC
 SG_ OBC_OTemp_ERR : 25|2@0+ (1,0) [0|3] ""  VCU,BMS,EVCC
 SG_ OBC_OCofOut_ERR : 10|1@0+ (1,0) [0|1] ""  VCU,BMS,EVCC
 SG_ OBC_CANcomoverT_ERR : 11|1@0+ (1,0) [0|1] ""  VCU,BMS,EVCC
 SG_ OBC_UVofIn_ERR : 12|1@0+ (1,0) [0|1] ""  VCU,BMS,EVCC
 SG_ OBC_OVofIn_ERR : 13|1@0+ (1,0) [0|1] ""  VCU,BMS,EVCC
 SG_ OBC_OVofPFC_ERR : 14|1@0+ (1,0) [0|1] ""  VCU,BMS,EVCC
 SG_ OBC_UVofPFC_ERR : 15|1@0+ (1,0) [0|1] ""  VCU,BMS,EVCC
 SG_ OBC_UVofOut_ERR : 16|1@0+ (1,0) [0|1] ""  VCU,BMS,EVCC
 SG_ OBC_OVofOut_ERR : 17|1@0+ (1,0) [0|1] ""  VCU,BMS,EVCC

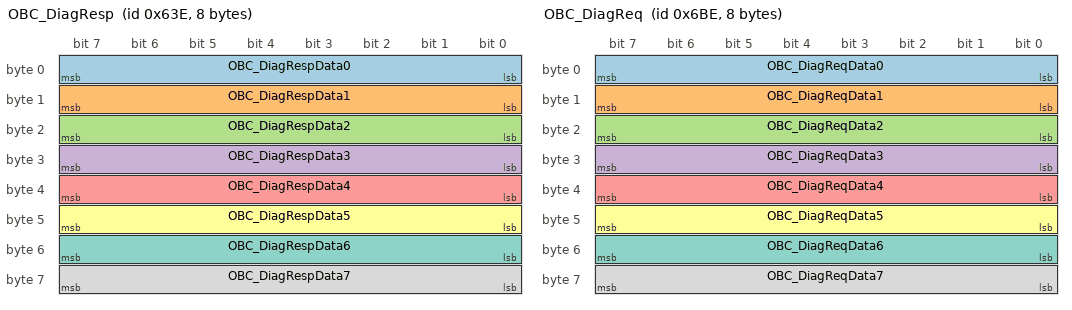
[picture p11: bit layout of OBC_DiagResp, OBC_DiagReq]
BO_ 1598 OBC_DiagResp: 8 OBC
 SG_ OBC_DiagRespData0 : 7|8@0+ (1,0) [0|255] ""  VCU
 SG_ OBC_DiagRespData1 : 15|8@0+ (1,0) [0|255] ""  VCU
 SG_ OBC_DiagRespData2 : 23|8@0+ (1,0) [0|255] ""  VCU
 SG_ OBC_DiagRespData3 : 31|8@0+ (1,0) [0|255] ""  VCU
 SG_ OBC_DiagRespData4 : 39|8@0+ (1,0) [0|255] ""  VCU
 SG_ OBC_DiagRespData5 : 47|8@0+ (1,0) [0|255] ""  VCU
 SG_ OBC_DiagRespData6 : 55|8@0+ (1,0) [0|255] ""  VCU
 SG_ OBC_DiagRespData7 : 63|8@0+ (1,0) [0|255] ""  VCU

BO_ 1726 OBC_DiagReq: 8 VCU
 SG_ OBC_DiagReqData0 : 7|8@0+ (1,0) [0|255] ""  OBC
 SG_ OBC_DiagReqData1 : 15|8@0+ (1,0) [0|255] ""  OBC
 SG_ OBC_DiagReqData2 : 23|8@0+ (1,0) [0|255] ""  OBC
 SG_ OBC_DiagReqData3 : 31|8@0+ (1,0) [0|255] ""  OBC
 SG_ OBC_DiagReqData4 : 39|8@0+ (1,0) [0|255] ""  OBC
 SG_ OBC_DiagReqData5 : 47|8@0+ (1,0) [0|255] ""  OBC
 SG_ OBC_DiagReqData6 : 55|8@0+ (1,0) [0|255] ""  OBC
 SG_ OBC_DiagReqData7 : 63|8@0+ (1,0) [0|255] ""  OBC

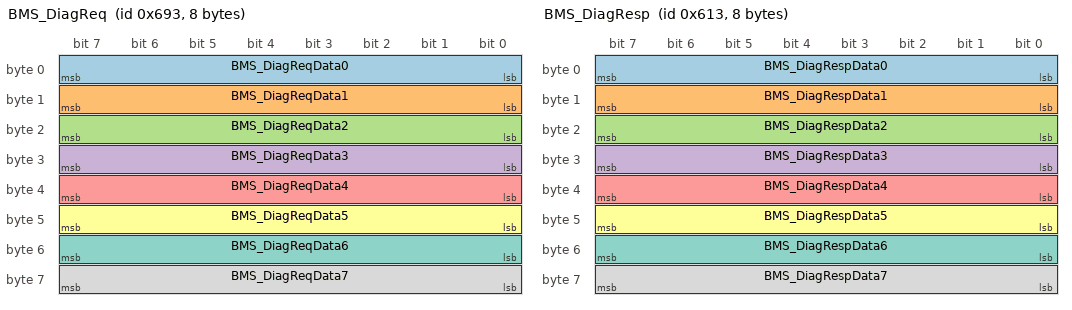
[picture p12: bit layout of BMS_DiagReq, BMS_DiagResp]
BO_ 1683 BMS_DiagReq: 8 VCU
 SG_ BMS_DiagReqData0 : 7|8@0+ (1,0) [0|255] ""  BMS
 SG_ BMS_DiagReqData1 : 15|8@0+ (1,0) [0|255] ""  BMS
 SG_ BMS_DiagReqData2 : 23|8@0+ (1,0) [0|255] ""  BMS
 SG_ BMS_DiagReqData3 : 31|8@0+ (1,0) [0|255] ""  BMS
 SG_ BMS_DiagReqData4 : 39|8@0+ (1,0) [0|255] ""  BMS
 SG_ BMS_DiagReqData5 : 47|8@0+ (1,0) [0|255] ""  BMS
 SG_ BMS_DiagReqData6 : 55|8@0+ (1,0) [0|255] ""  BMS
 SG_ BMS_DiagReqData7 : 63|8@0+ (1,0) [0|255] ""  BMS

BO_ 1555 BMS_DiagResp: 8 BMS
 SG_ BMS_DiagRespData0 : 7|8@0+ (1,0) [0|255] ""  VCU
 SG_ BMS_DiagRespData1 : 15|8@0+ (1,0) [0|255] ""  VCU
 SG_ BMS_DiagRespData2 : 23|8@0+ (1,0) [0|255] ""  VCU
 SG_ BMS_DiagRespData3 : 31|8@0+ (1,0) [0|255] ""  VCU
 SG_ BMS_DiagRespData4 : 39|8@0+ (1,0) [0|255] ""  VCU
 SG_ BMS_DiagRespData5 : 47|8@0+ (1,0) [0|255] ""  VCU
 SG_ BMS_DiagRespData6 : 55|8@0+ (1,0) [0|255] ""  VCU
 SG_ BMS_DiagRespData7 : 63|8@0+ (1,0) [0|255] ""  VCU

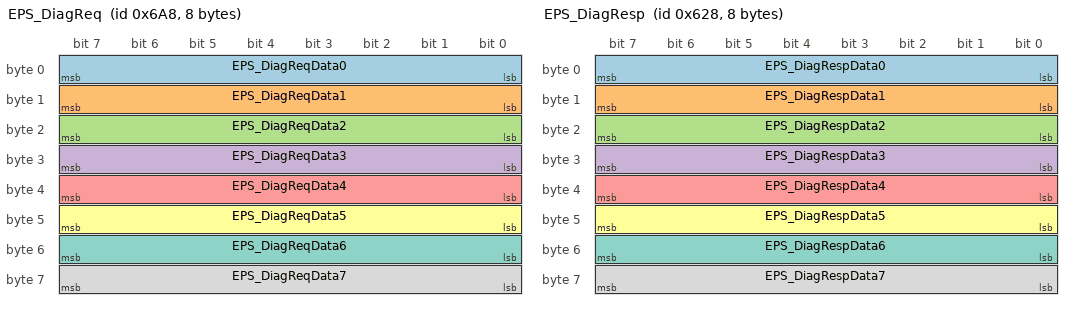
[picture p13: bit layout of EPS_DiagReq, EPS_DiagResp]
BO_ 1704 EPS_DiagReq: 8 VCU
 SG_ EPS_DiagReqData0 : 7|8@0+ (1,0) [0|255] ""  EPS
 SG_ EPS_DiagReqData1 : 15|8@0+ (1,0) [0|255] ""  EPS
 SG_ EPS_DiagReqData2 : 23|8@0+ (1,0) [0|255] ""  EPS
 SG_ EPS_DiagReqData3 : 31|8@0+ (1,0) [0|255] ""  EPS
 SG_ EPS_DiagReqData4 : 39|8@0+ (1,0) [0|255] ""  EPS
 SG_ EPS_DiagReqData5 : 47|8@0+ (1,0) [0|255] ""  EPS
 SG_ EPS_DiagReqData6 : 55|8@0+ (1,0) [0|255] ""  EPS
 SG_ EPS_DiagReqData7 : 63|8@0+ (1,0) [0|255] ""  EPS

BO_ 1576 EPS_DiagResp: 8 EPS
 SG_ EPS_DiagRespData0 : 7|8@0+ (1,0) [0|255] ""  VCU
 SG_ EPS_DiagRespData1 : 15|8@0+ (1,0) [0|255] ""  VCU
 SG_ EPS_DiagRespData2 : 23|8@0+ (1,0) [0|255] ""  VCU
 SG_ EPS_DiagRespData3 : 31|8@0+ (1,0) [0|255] ""  VCU
 SG_ EPS_DiagRespData4 : 39|8@0+ (1,0) [0|255] ""  VCU
 SG_ EPS_DiagRespData5 : 47|8@0+ (1,0) [0|255] ""  VCU
 SG_ EPS_DiagRespData6 : 55|8@0+ (1,0) [0|255] ""  VCU
 SG_ EPS_DiagRespData7 : 63|8@0+ (1,0) [0|255] ""  VCU

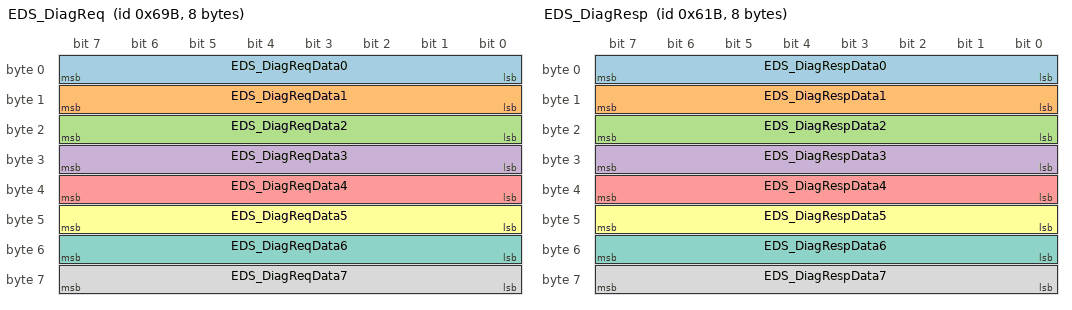
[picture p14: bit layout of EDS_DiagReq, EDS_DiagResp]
BO_ 1691 EDS_DiagReq: 8 VCU
 SG_ EDS_DiagReqData0 : 7|8@0+ (1,0) [0|255] ""  EDS
 SG_ EDS_DiagReqData1 : 15|8@0+ (1,0) [0|255] ""  EDS
 SG_ EDS_DiagReqData2 : 23|8@0+ (1,0) [0|255] ""  EDS
 SG_ EDS_DiagReqData3 : 31|8@0+ (1,0) [0|255] ""  EDS
 SG_ EDS_DiagReqData4 : 39|8@0+ (1,0) [0|255] ""  EDS
 SG_ EDS_DiagReqData5 : 47|8@0+ (1,0) [0|255] ""  EDS
 SG_ EDS_DiagReqData6 : 55|8@0+ (1,0) [0|255] ""  EDS
 SG_ EDS_DiagReqData7 : 63|8@0+ (1,0) [0|255] ""  EDS

BO_ 1563 EDS_DiagResp: 8 EDS
 SG_ EDS_DiagRespData0 : 7|8@0+ (1,0) [0|255] ""  VCU
 SG_ EDS_DiagRespData1 : 15|8@0+ (1,0) [0|255] ""  VCU
 SG_ EDS_DiagRespData2 : 23|8@0+ (1,0) [0|255] ""  VCU
 SG_ EDS_DiagRespData3 : 31|8@0+ (1,0) [0|255] ""  VCU
 SG_ EDS_DiagRespData4 : 39|8@0+ (1,0) [0|255] ""  VCU
 SG_ EDS_DiagRespData5 : 47|8@0+ (1,0) [0|255] ""  VCU
 SG_ EDS_DiagRespData6 : 55|8@0+ (1,0) [0|255] ""  VCU
 SG_ EDS_DiagRespData7 : 63|8@0+ (1,0) [0|255] ""  VCU

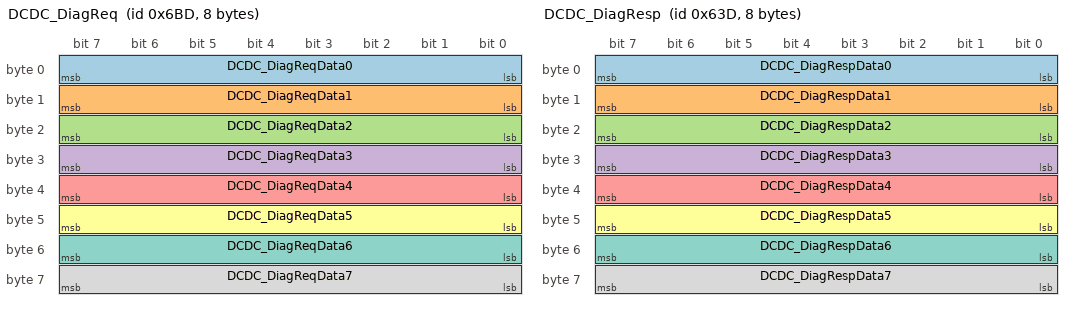
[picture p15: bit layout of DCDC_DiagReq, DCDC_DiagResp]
BO_ 1725 DCDC_DiagReq: 8 VCU
 SG_ DCDC_DiagReqData0 : 7|8@0+ (1,0) [0|255] ""  DCDC
 SG_ DCDC_DiagReqData1 : 15|8@0+ (1,0) [0|255] ""  DCDC
 SG_ DCDC_DiagReqData2 : 23|8@0+ (1,0) [0|255] ""  DCDC
 SG_ DCDC_DiagReqData3 : 31|8@0+ (1,0) [0|255] ""  DCDC
 SG_ DCDC_DiagReqData4 : 39|8@0+ (1,0) [0|255] ""  DCDC
 SG_ DCDC_DiagReqData5 : 47|8@0+ (1,0) [0|255] ""  DCDC
 SG_ DCDC_DiagReqData6 : 55|8@0+ (1,0) [0|255] ""  DCDC
 SG_ DCDC_DiagReqData7 : 63|8@0+ (1,0) [0|255] ""  DCDC

BO_ 1597 DCDC_DiagResp: 8 DCDC
 SG_ DCDC_DiagRespData0 : 7|8@0+ (1,0) [0|255] ""  VCU
 SG_ DCDC_DiagRespData1 : 15|8@0+ (1,0) [0|255] ""  VCU
 SG_ DCDC_DiagRespData2 : 23|8@0+ (1,0) [0|255] ""  VCU
 SG_ DCDC_DiagRespData3 : 31|8@0+ (1,0) [0|255] ""  VCU
 SG_ DCDC_DiagRespData4 : 39|8@0+ (1,0) [0|255] ""  VCU
 SG_ DCDC_DiagRespData5 : 47|8@0+ (1,0) [0|255] ""  VCU
 SG_ DCDC_DiagRespData6 : 55|8@0+ (1,0) [0|255] ""  VCU
 SG_ DCDC_DiagRespData7 : 63|8@0+ (1,0) [0|255] ""  VCU

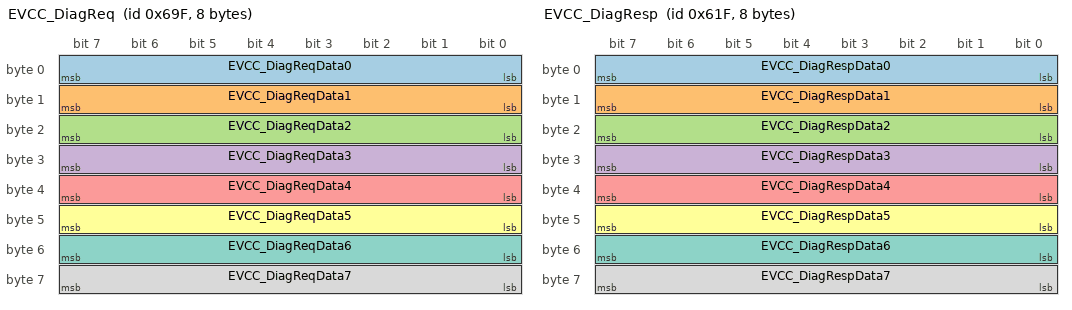
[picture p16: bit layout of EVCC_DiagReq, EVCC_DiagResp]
BO_ 1695 EVCC_DiagReq: 8 VCU
 SG_ EVCC_DiagReqData0 : 7|8@0+ (1,0) [0|255] ""  EVCC
 SG_ EVCC_DiagReqData1 : 15|8@0+ (1,0) [0|255] ""  EVCC
 SG_ EVCC_DiagReqData2 : 23|8@0+ (1,0) [0|255] ""  EVCC
 SG_ EVCC_DiagReqData3 : 31|8@0+ (1,0) [0|255] ""  EVCC
 SG_ EVCC_DiagReqData4 : 39|8@0+ (1,0) [0|255] ""  EVCC
 SG_ EVCC_DiagReqData5 : 47|8@0+ (1,0) [0|255] ""  EVCC
 SG_ EVCC_DiagReqData6 : 55|8@0+ (1,0) [0|255] ""  EVCC
 SG_ EVCC_DiagReqData7 : 63|8@0+ (1,0) [0|255] ""  EVCC

BO_ 1567 EVCC_DiagResp: 8 EVCC
 SG_ EVCC_DiagRespData0 : 7|8@0+ (1,0) [0|255] ""  VCU
 SG_ EVCC_DiagRespData1 : 15|8@0+ (1,0) [0|255] ""  VCU
 SG_ EVCC_DiagRespData2 : 23|8@0+ (1,0) [0|255] ""  VCU
 SG_ EVCC_DiagRespData3 : 31|8@0+ (1,0) [0|255] ""  VCU
 SG_ EVCC_DiagRespData4 : 39|8@0+ (1,0) [0|255] ""  VCU
 SG_ EVCC_DiagRespData5 : 47|8@0+ (1,0) [0|255] ""  VCU
 SG_ EVCC_DiagRespData6 : 55|8@0+ (1,0) [0|255] ""  VCU
 SG_ EVCC_DiagRespData7 : 63|8@0+ (1,0) [0|255] ""  VCU

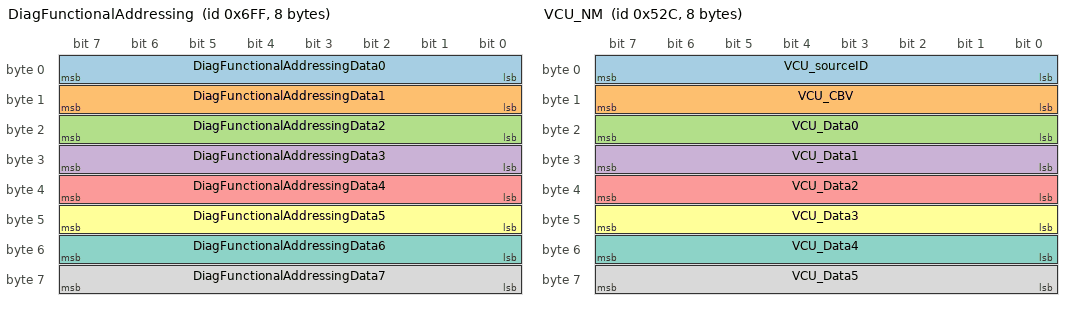
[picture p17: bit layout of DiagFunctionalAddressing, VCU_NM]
BO_ 1791 DiagFunctionalAddressing: 8 VCU
 SG_ DiagFunctionalAddressingData0 : 7|8@0+ (1,0) [0|255] ""  EAC,EDS,EPS,BMS,DCDC,EVCC,OBC
 SG_ DiagFunctionalAddressingData1 : 15|8@0+ (1,0) [0|255] ""  EAC,EDS,EPS,BMS,DCDC,EVCC,OBC
 SG_ DiagFunctionalAddressingData2 : 23|8@0+ (1,0) [0|255] ""  EAC,EDS,EPS,BMS,DCDC,EVCC,OBC
 SG_ DiagFunctionalAddressingData3 : 31|8@0+ (1,0) [0|255] ""  EAC,EDS,EPS,BMS,DCDC,EVCC,OBC
 SG_ DiagFunctionalAddressingData4 : 39|8@0+ (1,0) [0|255] ""  EAC,EDS,EPS,BMS,DCDC,EVCC,OBC
 SG_ DiagFunctionalAddressingData5 : 47|8@0+ (1,0) [0|255] ""  EAC,EDS,EPS,BMS,DCDC,EVCC,OBC
 SG_ DiagFunctionalAddressingData6 : 55|8@0+ (1,0) [0|255] ""  EAC,EDS,EPS,BMS,DCDC,EVCC,OBC
 SG_ DiagFunctionalAddressingData7 : 63|8@0+ (1,0) [0|255] ""  EAC,EDS,EPS,BMS,DCDC,EVCC,OBC

BO_ 1324 VCU_NM: 8 VCU
 SG_ VCU_sourceID : 7|8@0+ (1,0) [0|255] ""  BMS,DCDC,EVCC,OBC
 SG_ VCU_CBV : 15|8@0+ (1,0) [0|255] ""  BMS,DCDC,EVCC,OBC
 SG_ VCU_Data0 : 23|8@0+ (1,0) [0|255] ""  BMS,DCDC,EVCC,OBC
 SG_ VCU_Data1 : 31|8@0+ (1,0) [0|255] ""  BMS,DCDC,EVCC,OBC
 SG_ VCU_Data2 : 39|8@0+ (1,0) [0|255] ""  BMS,DCDC,EVCC,OBC
 SG_ VCU_Data3 : 47|8@0+ (1,0) [0|255] ""  BMS,DCDC,EVCC,OBC
 SG_ VCU_Data4 : 55|8@0+ (1,0) [0|255] ""  BMS,DCDC,EVCC,OBC
 SG_ VCU_Data5 : 63|8@0+ (1,0) [0|255] ""  BMS,DCDC,EVCC,OBC

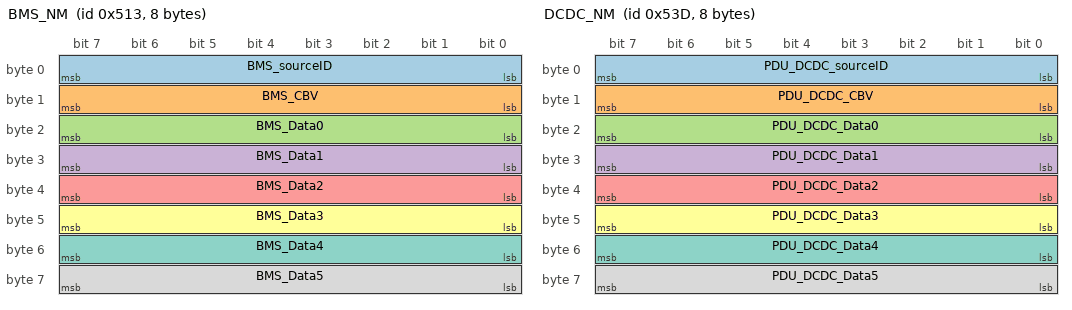
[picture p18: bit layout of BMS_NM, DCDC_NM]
BO_ 1299 BMS_NM: 8 BMS
 SG_ BMS_sourceID : 7|8@0+ (1,0) [0|255] ""  VCU,DCDC,EVCC,OBC
 SG_ BMS_CBV : 15|8@0+ (1,0) [0|255] ""  VCU,DCDC,EVCC,OBC
 SG_ BMS_Data0 : 23|8@0+ (1,0) [0|255] ""  VCU,DCDC,EVCC,OBC
 SG_ BMS_Data1 : 31|8@0+ (1,0) [0|255] ""  VCU,DCDC,EVCC,OBC
 SG_ BMS_Data2 : 39|8@0+ (1,0) [0|255] ""  VCU,DCDC,EVCC,OBC
 SG_ BMS_Data3 : 47|8@0+ (1,0) [0|255] ""  VCU,DCDC,EVCC,OBC
 SG_ BMS_Data4 : 55|8@0+ (1,0) [0|255] ""  VCU,DCDC,EVCC,OBC
 SG_ BMS_Data5 : 63|8@0+ (1,0) [0|255] ""  VCU,DCDC,EVCC,OBC

BO_ 1341 DCDC_NM: 8 DCDC
 SG_ PDU_DCDC_sourceID : 7|8@0+ (1,0) [0|255] ""  VCU,BMS,EVCC,OBC
 SG_ PDU_DCDC_CBV : 15|8@0+ (1,0) [0|255] ""  VCU,BMS,EVCC,OBC
 SG_ PDU_DCDC_Data0 : 23|8@0+ (1,0) [0|255] ""  VCU,BMS,EVCC,OBC
 SG_ PDU_DCDC_Data1 : 31|8@0+ (1,0) [0|255] ""  VCU,BMS,EVCC,OBC
 SG_ PDU_DCDC_Data2 : 39|8@0+ (1,0) [0|255] ""  VCU,BMS,EVCC,OBC
 SG_ PDU_DCDC_Data3 : 47|8@0+ (1,0) [0|255] ""  VCU,BMS,EVCC,OBC
 SG_ PDU_DCDC_Data4 : 55|8@0+ (1,0) [0|255] ""  VCU,BMS,EVCC,OBC
 SG_ PDU_DCDC_Data5 : 63|8@0+ (1,0) [0|255] ""  VCU,BMS,EVCC,OBC

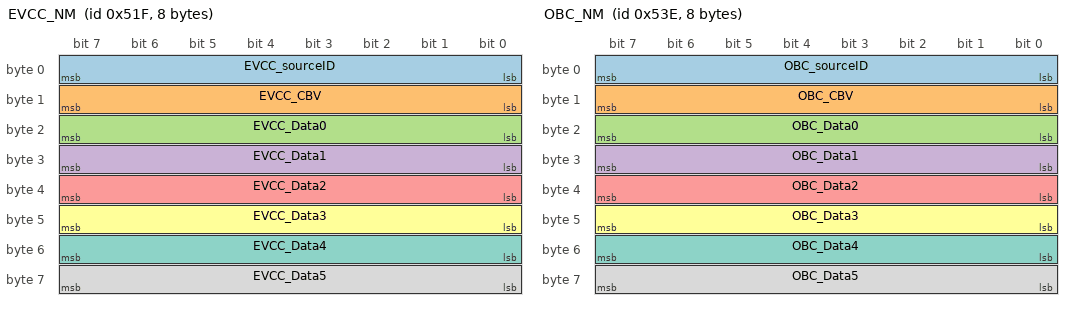
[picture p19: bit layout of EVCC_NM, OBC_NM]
BO_ 1311 EVCC_NM: 8 EVCC
 SG_ EVCC_sourceID : 7|8@0+ (1,0) [0|255] ""  VCU,BMS,DCDC,OBC
 SG_ EVCC_CBV : 15|8@0+ (1,0) [0|255] ""  VCU,BMS,DCDC,OBC
 SG_ EVCC_Data0 : 23|8@0+ (1,0) [0|255] ""  VCU,BMS,DCDC,OBC
 SG_ EVCC_Data1 : 31|8@0+ (1,0) [0|255] ""  VCU,BMS,DCDC,OBC
 SG_ EVCC_Data2 : 39|8@0+ (1,0) [0|255] ""  VCU,BMS,DCDC,OBC
 SG_ EVCC_Data3 : 47|8@0+ (1,0) [0|255] ""  VCU,BMS,DCDC,OBC
 SG_ EVCC_Data4 : 55|8@0+ (1,0) [0|255] ""  VCU,BMS,DCDC,OBC
 SG_ EVCC_Data5 : 63|8@0+ (1,0) [0|255] ""  VCU,BMS,DCDC,OBC

BO_ 1342 OBC_NM: 8 OBC
 SG_ OBC_sourceID : 7|8@0+ (1,0) [0|255] ""  VCU,BMS,DCDC,EVCC
 SG_ OBC_CBV : 15|8@0+ (1,0) [0|255] ""  VCU,BMS,DCDC,EVCC
 SG_ OBC_Data0 : 23|8@0+ (1,0) [0|255] ""  VCU,BMS,DCDC,EVCC
 SG_ OBC_Data1 : 31|8@0+ (1,0) [0|255] ""  VCU,BMS,DCDC,EVCC
 SG_ OBC_Data2 : 39|8@0+ (1,0) [0|255] ""  VCU,BMS,DCDC,EVCC
 SG_ OBC_Data3 : 47|8@0+ (1,0) [0|255] ""  VCU,BMS,DCDC,EVCC
 SG_ OBC_Data4 : 55|8@0+ (1,0) [0|255] ""  VCU,BMS,DCDC,EVCC
 SG_ OBC_Data5 : 63|8@0+ (1,0) [0|255] ""  VCU,BMS,DCDC,EVCC

CM_ SG_ 374 Checksum_0x176 "Checksum";
CM_ SG_ 374 Rolling_Counter_0x176 "Rolling Counter";
CM_ SG_ 374 BMS_HVLinkVol_MEAS "Link Voltage";
CM_ SG_ 374 BMS_HVPackVol_MEAS "Pack Voltage";
CM_ SG_ 375 Checksum_0x177 "Checksum";
CM_ SG_ 375 Rolling_Counter_0x177 "Rolling Counter";
CM_ SG_ 375 BMS_HVBusVol_MEAS "BUS Voltage, it is informative";
CM_ SG_ 375 BMS_HVFuseVol_MEAS "Measure voltage after fuse to identify the fuse is blown or not";
CM_ SG_ 372 Checksum_0x174 "Checksum";
CM_ SG_ 372 Rolling_Counter_0x174 "Rolling_Counter";
CM_ SG_ 372 BMS_PackCur_MEAS "Pack Current";
CM_ SG_ 372 BMS_AllowDischgCurr "continuous maximum allowable discharge current of battery";
CM_ SG_ 372 BMS_AllowDischgCurrPeak "Peak maximum allowable discharge current of battery";
CM_ SG_ 532 Checksum_0x214 "Checksum";
CM_ SG_ 532 Rolling_Counter_0x214 "Rolling Counter";
CM_ SG_ 532 BMS_Display_SOC "Display SOC";
CM_ SG_ 532 BMS_SocActual_EST "Actual SOC";
CM_ SG_ 532 BMS_SOH "BMS State Of Health";
CM_ SG_ 533 Checksum_0x215 "Checksum";
CM_ SG_ 533 Rolling_Counter_0x215 "Rolling Counter";
CM_ SG_ 533 BMS_SOE "BMS State Of Enegy";
CM_ SG_ 533 BMS_HWCrash_Sts "Battery Pack Hardware Crash signal Status";
CM_ SG_ 533 BMS_HVIL_STS "The HVIL state of BMS";
CM_ SG_ 533 BMS_IGN_Sts "the ignition signal status (on/off)";
CM_ SG_ 533 BMS_Sys_STS "BMS_Status(Self-test after BMS wake-up)";
CM_ SG_ 533 BMS_HVOnOff_STS "BMS High Voltage Status(BMS_HVOnOff_STS to be received by all modules,Used as a flash programming pre-condition (replacement for engine running)";
CM_ SG_ 533 BMS_Balance_STS "BMS Balance Status";
CM_ SG_ 533 BMS_BatBalance_ERR "Battery Balance Error indicates Balancing switch is short or open";
CM_ SG_ 533 BMS_ISU_Status "Insulation status";
CM_ SG_ 533 BMS_ERR_LEV "BMSFailure Level";
CM_ SG_ 533 BMS_Vehicle_ERR_LEV "BMS Vehicle Failure Level";
CM_ SG_ 533 BMS_HV_Sts "BMS High Voltage Status";
CM_ SG_ 549 Checksum_0x225 "Checksum";
CM_ SG_ 549 Rolling_Counter_0x225 "Rolling Counter";
CM_ SG_ 549 CDM_bAcvCanComStblMon "Monitored flag indicating active stable CAN communication.";
CM_ SG_ 549 FRMo_bErrHvbatStReqExtMon "Collective error flag indicating HV battery state request E2E fault.";
CM_ SG_ 549 FRMo_bErrChrgnAllwdExtMon "Collective error flag indicating charging allowed E2E fault.";
CM_ SG_ 549 FRMo_bErrVehCrashStExtMon "Collective error flag indicating vehicle crash state E2E fault.";
CM_ SG_ 549 CDM_bErrComctnLossCanMon "Error flag indicating total loss of CAN communication fault.";
CM_ SG_ 549 CTCMon_bErrCtctrSopcMon "Error flag indicating contactor switch-off path test fault.";
CM_ SG_ 549 CTCMon_bInvldCtctrHisdIFbMon "Error flag indicating high-side feedback current invalidity.";
CM_ SG_ 549 CTCMon_bInvldCtctrLosdUFbMon "Error flag indicating low-side feedback voltage invalidity.";
CM_ SG_ 549 CTM_bErrCellTDifMaxMon "Error flag indicating maximum cell temperature difference fault.";
CM_ SG_ 549 CTM_bErrCellTMaxMon "Error flag indicating maximum cell temperature limit fault.";
CM_ SG_ 549 CTM_bErrCellTMinMon "Error flag indicating minimum cell temperature limit fault.";
CM_ SG_ 549 CTM_bErrThrwyPredMon "Error flag indicating thermal runaway fault.";
CM_ SG_ 549 CUM_bErrCellUDifMaxMon "Error flag indicating maximum cell voltage difference fault.";
CM_ SG_ 549 CUM_bErrCellUMaxMon "Error flag indicating cell overvoltage fault.";
CM_ SG_ 549 CUM_bErrCellUMinMon "Error flag indicating cell undervoltage fault.";
CM_ SG_ 549 CUM_bErrCellUProtnMaxNvMon "Non-volatile error flag indicating cell overvoltage protection limit fault.";
CM_ SG_ 549 CUM_bErrCellUProtnMinNvMon "Non-volatile error flag indicating cell overvoltage protection limit fault.";
CM_ SG_ 549 CUM_bErrPackUImplyMon "Error flag indicating pack voltage implausibility.";
CM_ SG_ 549 EHPMon_bRdyHvilMon "Ready flag indicating operational HVIL circuit.";
CM_ SG_ 549 EHPMon_bErrWlddNegNvMon "Non-volatile error flag indicating welded negative contactor fault.";
CM_ SG_ 549 EHPMon_bErrWlddPosNvMon "Non-volatile error flag indicating welded positive contactor fault.";
CM_ SG_ 549 EHPMon_bErrWlddPrechNvMon "Non-volatile error flag indicating welded precharge contactor fault.";
CM_ SG_ 549 EHPMon_bErrHvilMon "Error flag indicating HVIL open line fault.";
CM_ SG_ 549 EHPMon_bErrHvilShoMon "Error flag indicating HVIL invalidity (ScG/ScB) fault.";
CM_ SG_ 549 EHPMon_bErrPackIslnRNvMon "Non-volatile error flag indicating pack level isolation resistance fault.";
CM_ SG_ 549 EHPMon_bErrVehCrashNvMon "Non-volatile error flag indicating vehicle crash fault .";
CM_ SG_ 549 EHPMon_bErrVehIslnRNvMon "Non-volatile error flag indicating vehicle level isolation resistance fault.";
CM_ SG_ 549 FRMo_bErrMemStorgNvMon "Error flag indicating storage fault in the non-volatile memory.";
CM_ SG_ 549 L1IM_bErrClmp30MaxMonInp "Error flag indicating Level 1 KL30 overvoltage fault.";
CM_ SG_ 549 L1IM_bErrClmp30MinMonInp "Error flag indicating Level 1 KL30 undervoltage fault.";
CM_ SG_ 549 L1IM_bErrCtctrDtrtMonInp "Error flag indicating Level 1 contactor deterioration fault.";
CM_ SG_ 549 L1IM_bErrUActImplyMonInp "Error flag indicating Level 1 high voltage implausibility.";
CM_ SG_ 549 MCCM_bAcvMdulCtlrStsMon "Active flag indicating operational module controller status.";
CM_ SG_ 549 MCCM_bErrLntecSngFltMon "Error flag indicating single-point safety mechanism fault of the Multi-Stack Battery Monitor.";
CM_ SG_ 549 MCCM_bErrLntecLtntFltMon "Error flag indicating latent safety mechanism fault of the Multi-Stack Battery Monitor.";
CM_ SG_ 549 MCCM_bErrMdulCellSnsrCfgMon "Error flag indicating module/cell/temperature sensor configuration fault.";
CM_ SG_ 549 MCCM_bErrMdulCtlrComMon "Error flag indicating module controller communication status fault.";
CM_ SG_ 549 MCCM_bErrSnsrTEltlMon "Error flag indicating multiple temperature sensor in a module fault.";
CM_ SG_ 549 MCCM_bWarnSnsrTEltlMon "Error flag indicating single temperature sensor in a module fault.";
CM_ SG_ 549 PCM_bRdySnsrIMon "Ready flag indicating operational current sensors.";
CM_ SG_ 549 PCM_bErrPackEFlowMaxLimMon "Error flag indicating energy flow limit fault.";
CM_ SG_ 549 PCM_bErrPackIChDchaMaxLimMon "Error flag indicating pack current charging/discharging limit fault.";
CM_ SG_ 549 PCM_bErrSnsrIImplyMon "Error flag indicating current sensor implausibility fault.";
CM_ SG_ 549 FRMo_bErrSnsrI1ExtMon "Collective error flag indicating current sensor 1 (CAN-based shunt sensor) E2E fault.";
CM_ SG_ 549 PCM_bInvldSnsrI1Mon "Error flag indicating current sensor 1 invalidity fault.";
CM_ SG_ 549 PCM_bInvldSnsrI2Mon "Error flag indicating current sensor 2 invalidity fault.";
CM_ SG_ 549 FRMo_bErrSopcLvl3Mon "Error flag indicating Level 3 switch-off path test fault.";
CM_ SG_ 549 BMS_FRMo_Reserved_1 "Fault monitor signal";
CM_ SG_ 549 BMS_FRMo_Reserved_2 "Fault monitor signal";
CM_ SG_ 549 BMS_FRMo_Reserved_3 "Fault monitor signal";
CM_ SG_ 549 BMS_FRMo_Reserved_4 "Fault monitor signal";
CM_ SG_ 549 BMS_FRMo_Reserved_5 "Fault monitor signal";
CM_ SG_ 293 Checksum_0x125 "Checksum";
CM_ SG_ 293 Rolling_Counter_0x125 "Rolling Counter";
CM_ SG_ 293 BMS_Actual_ChgPower "Actual charging power实际充电功率";
CM_ SG_ 293 BMS_Actual_DisChgPower "BMS Allowed output power实际放电功率";
CM_ SG_ 885 Checksum_0x375 "Checksum";
CM_ SG_ 885 Rolling_Counter_0x375 "Rolling Counter";
CM_ SG_ 885 BMS_MainPosRelay_ERR "Main Position Relay Error";
CM_ SG_ 885 BMS_MainPosRelay_STS "Main Positive Relay Status";
CM_ SG_ 885 BMS_PreChgRelay_ERR "Precahrge relay is not working properly";
CM_ SG_ 885 BMS_PreChgRelay_STS "PreCharge Relay Status";
CM_ SG_ 885 BMS_TotalNegRelay_STS "Main Negative Relay Status";
CM_ SG_ 885 BMS_TotalNegRelay_ERR "Main Negative Relay Error";
CM_ SG_ 517 Checksum_0x205 "Checksum";
CM_ SG_ 517 Rolling_Counter_0x205 "Rolling Counter";
CM_ SG_ 517 BMS_MaxCellVol "Max Cell Voltage";
CM_ SG_ 517 BMS_CellNumMaxCellVol "Cell Number of Max Cell Voltage";
CM_ SG_ 517 BMS_MinCellVol "Min Cell Voltage";
CM_ SG_ 517 BMS_CellNumMinCellVol "Cell Number of Min Cell Voltage";
CM_ SG_ 581 Checksum_0x245 "Checksum";
CM_ SG_ 581 Rolling_Counter_0x245 "Rolling Counter";
CM_ SG_ 581 BMS_PackTemp "Pack Temperature";
CM_ SG_ 581 BMS_MaxMinDiffCellTemp "max and min cell temperature differences";
CM_ SG_ 581 BMS_MaxCellTemp "Max Cell Temperature";
CM_ SG_ 581 BMS_MinCellTemp "Min Cell Temperature";
CM_ SG_ 581 BMS_ProbeNumMaxCellTemp "Probe Number of Max Cell Temperature";
CM_ SG_ 581 BMS_ProbeNumMinCellTemp "Probe Number of Min Cell Temperature";
CM_ SG_ 773 Checksum_0x305 "Checksum";
CM_ SG_ 773 Rolling_Counter_0x305 "Rolling Counter";
CM_ SG_ 773 BMS_VCU_Insulation_Mon_Sts "Feedback for the Insulation Monitoring signal";
CM_ SG_ 773 BMS_PackInsuRes "Minimum value of BCU_PosInsuRes and BCU_NegInsuRes";
CM_ SG_ 1171 BMS_Warning_Flag_Reserved_08 "Warning signal";
CM_ SG_ 1171 BMS_Warning_Flag_Reserved_07 "Warning signal";
CM_ SG_ 1171 BMS_Warning_Flag_Reserved_11 "Warning signal";
CM_ SG_ 1171 BMS_Warning_Flag_Reserved_10 "Warning signal";
CM_ SG_ 1171 BMS_Warning_Flag_Reserved_09 "Warning signal";
CM_ SG_ 1171 BMS_Warning_Flag_Reserved_13 "Warning signal";
CM_ SG_ 1171 BMS_Warning_Flag_Reserved_12 "Warning signal";
CM_ SG_ 1171 BMS_Warning_Flag_Reserved_06 "Warning signal";
CM_ SG_ 1171 BMS_Warning_Flag_Reserved_05 "Warning signal";
CM_ SG_ 1171 BMS_Warning_Flag_Reserved_04 "Warning signal";
CM_ SG_ 1171 BMS_MalfunctionSts "Malfunction status of battery for IPC display";
CM_ SG_ 1171 BMS_LowBattery "Low Battery Warning";
CM_ SG_ 1171 BMS_BatteryReplacement "Separate signal to indicate the battery replacement information(Battery replacement IPC)";
CM_ SG_ 1171 BMS_PackTempSts "Pack temperature warning";
CM_ SG_ 1171 BMS_ThermalRunaway "Thermalrunaway";
CM_ SG_ 1171 Rolling_Counter_0x493 "Rolling Counter";
CM_ SG_ 1171 Checksum_0x493 "Checksum";
CM_ SG_ 1109 Checksum_0x455 "Checksum";
CM_ SG_ 1109 Rolling_Counter_0x455 "Rolling Counter";
CM_ SG_ 1109 BMS_PackInsu_ERR "Insulation check lines have problems, short to ground or short to bat";
CM_ SG_ 1109 BMS_CellVoltDiff_ERR "max and min cell voltage difference is too large";
CM_ SG_ 1109 BMS_PackOverCurr_ERR "When the over current is detected during charging and discharging for the given period of time, then the BMS_Packovercurr_err will set";
CM_ SG_ 1109 BMS_HVIL_Err "High Voltage Interlock loop circuit error";
CM_ SG_ 1109 BMS_CellHighVol_ERR "Over voltage of the cell is detected";
CM_ SG_ 1109 BMS_CellLowVol_ERR "under voltage of the cell is detected";
CM_ SG_ 1109 BMS_PackLowVol_ERR "Pack voltage is lower than the permittable values";
CM_ SG_ 1109 BMS_PackHighVol_ERR "Pack voltage is higher than the permittable values";
CM_ SG_ 1109 BMS_ProbeHighTemp_ERR "Over temperature of the cell is detected";
CM_ SG_ 1109 BMS_ProbeTempDiff_ERR "The difference in temperture between max and min is beyound the permissable limit";
CM_ SG_ 1109 BMS_FuseStatus_ERR "Fuse and Pyro fuse blowup status";
CM_ SG_ 1109 BMS_ProbeLowTemp_ERR "Under Temperature of the cell is detected";
CM_ SG_ 1504 BMS_Voltage_FrameNumber "BMS Voltage FrameNumber";
CM_ SG_ 1504 BMS_Voltage_Value1 "BMS Voltage Value1";
CM_ SG_ 1504 BMS_Voltage_Value2 "BMS Voltage Value2";
CM_ SG_ 1504 BMS_Voltage_Value3 "BMS Voltage Value3";
CM_ SG_ 1504 softwore_version "Current Raw wheel speed information valid flag of rear left wheel.";
CM_ SG_ 1505 BMS_Temp_FrameNumber "BMS Temperature FrameNumber";
CM_ SG_ 1505 BMS_Temp_Value1 "BMS Temperature Value1";
CM_ SG_ 1505 BMS_Temp_Value2 "BMS Temperature Value2";
CM_ SG_ 1505 BMS_Temp_Value3 "BMS Temperature Value3";
CM_ SG_ 1505 BMS_Temp_Value4 "BMS Temperature Value4";
CM_ SG_ 1505 BMS_Temp_Value5 "BMS Temperature Value5";
CM_ SG_ 1505 BMS_Temp_Value6 "BMS Temperature Value6";
CM_ SG_ 1505 BMS_Temp_Value7 "BMS Temperature Value7";
CM_ SG_ 1506 BMS_Test_Runaway "BMS Test Runaway";
CM_ SG_ 1506 BMS_Test_shunt_Temp "BMS Test shunt Temperature";
CM_ SG_ 1506 BMS_Test_V4_Volt "BMS Test V4 Volt";
CM_ SG_ 1506 BMS_Test_L2ErrNum "BMS Test L2ErrNum";
CM_ SG_ 1507 Error_Information "Error Information";
CM_ SG_ 1507 HVIL_HS_Volt "HVIL HS Volt";
CM_ SG_ 1507 HVIL_LS_Volt "HVIL LS Volt";
CM_ SG_ 1507 FCHVIL_HS_Volt "FCHVIL HS Volt";
CM_ SG_ 1507 FCHVIL_LS_Volt "FCHVIL LS Volt";
CM_ SG_ 1507 HVIL_HS_Inv "HVIL HS Inv";
CM_ SG_ 1507 HVIL_LS_Inv "HVIL LS Inv";
CM_ SG_ 1507 FCHVIL_HS_Inv "FCHVIL HS Inv";
CM_ SG_ 1507 FCHVIL_LS_Inv "FCHVIL LS Inv";
CM_ SG_ 1507 HVIL_Fault "HVIL Fault";
CM_ SG_ 1507 HallError "Hall Error";
CM_ SG_ 1508 BMS_QMMo_Reserved_9 "QM fault monitoring signals";
CM_ SG_ 1508 BMS_QMMo_Reserved_8 "QM fault monitoring signals";
CM_ SG_ 1508 BMS_QMMo_Reserved_7 "QM fault monitoring signals";
CM_ SG_ 1508 BMS_QMMo_Reserved_6 "QM fault monitoring signals";
CM_ SG_ 1508 BMS_QMMo_Reserved_5 "QM fault monitoring signals";
CM_ SG_ 1508 BMS_QMMo_Reserved_4 "QM fault monitoring signals";
CM_ SG_ 1508 BMS_QMMo_Reserved_3 "QM fault monitoring signals";
CM_ SG_ 1508 BMS_QMMo_Reserved_2 "QM fault monitoring signals";
CM_ SG_ 1508 BMS_QMMo_Reserved_11 "QM fault monitoring signals";
CM_ SG_ 1508 BMS_QMMo_Reserved_10 "QM fault monitoring signals";
CM_ SG_ 1508 BMS_QMMo_Reserved_1 "QM fault monitoring signals";
CM_ SG_ 1508 BMS_QMMo_Reserved_0 "QM fault monitoring signals";
CM_ SG_ 1508 Rolling_Counter_0x5E4 "Rolling Counter";
CM_ SG_ 1508 Checksum_0x5E4 "Checksum";
CM_ SG_ 523 Checksum_0x20B "Checksum";
CM_ SG_ 523 Rolling_Counter_0x20B "Rolling Counter";
CM_ SG_ 523 POD_DCDC_Max_Current_Out "DCDC Current OutputDCDC Current Output";
CM_ SG_ 523 DCDC_Temp_mosfet "DCDC Mosfet tempDCDC Mosfet temp";
CM_ SG_ 523 DCDC_Voltage_Output "DCDC Output VoltageDCDC Output Voltage";
CM_ SG_ 523 DCDC_Current_Output "DCDC Output CurrentDCDC Output Current";
CM_ SG_ 523 DCDC_Output_STS "Status of DCDCStatus of DCDC";
CM_ SG_ 523 DCDC_Temp_heatsink "heatsink Temperatureheatsink Temperature";
CM_ SG_ 646 Checksum_0x286 "Checksum";
CM_ SG_ 646 Rolling_Counter_0x286 "Rolling Counter";
CM_ SG_ 646 DCFC_OUT_DC_V "voltage HV battery (this point connected to the HV battery)";
CM_ SG_ 646 DCFC_OUT_DC_I_Reserved "not used(Reserved)";
CM_ SG_ 646 DCFC_DCCharge_line_V "voltage fast charge (EVSE)";
CM_ SG_ 647 DCDC_evt_BUS_OFF "bus off";
CM_ SG_ 647 DCDC_evt_MIA "Not receive Message";
CM_ SG_ 647 DCDC_evt_E2E "wrong check sum or rolling counter";
CM_ SG_ 647 DCDC_evt_Calibration_Flt "chek value calib in flash out of range";
CM_ SG_ 647 DCDC_evt_flash_Failure "not comunication with extern flash";
CM_ SG_ 647 DCDC_evt_FaultLatchCircuit "one of hw error then raise";
CM_ SG_ 647 DCDC_evt_HV_VoltSensFlt "measure value input HV out of range";
CM_ SG_ 647 DCDC_evt_HV_OverVoltFlt "over HV voltage";
CM_ SG_ 647 DCDC_evt_HV_UnderVoltFlt "input hv low or high";
CM_ SG_ 647 DCDC_evt_LV_VoltSensFlt "sensor measure value out lv out of range";
CM_ SG_ 647 DCDC_evt_LVBatt_OverVoltFlt "lv out voltage low or high";
CM_ SG_ 647 DCDC_evt_LVBatt_UnderVoltFlt "LV Bat Under Voltage";
CM_ SG_ 647 DCDC_evt_LVBatt_SensorFlt "sensor measure value battery lv out of range";
CM_ SG_ 647 DCDC_evt_LV_RedundancyFlt "Differential voltage of LV";
CM_ SG_ 647 DCDC_evt_LV_CurrSensFlt "Sensor measure lv current out of range";
CM_ SG_ 647 DCDC_evt_LV_OverCurr "lv current over";
CM_ SG_ 647 DCDC_evt_ReverseCurrFlt "reverse current fault";
CM_ SG_ 647 DCDC_evt_Heater_TempSensorFlt "over temperature heat";
CM_ SG_ 647 DCDC_evt_Mosfet_TempSensorFlt "over temperature fet";
CM_ SG_ 647 DCDC_evt_Mosfet_OverTemp "over temperature fet";
CM_ SG_ 647 DCDC_evt_HeatSink_TempSensorFlt "over temperature heat sink";
CM_ SG_ 647 DCDC_evt_HeatSink_OverTemp "over temperature heat sink";
CM_ SG_ 647 DCDC_evt_Heater_OverTempFlt "ADC fault";
CM_ SG_ 647 DCDC_evt_Heater_ShortIGBTFlt "Clock fault";
CM_ SG_ 647 DCDC_evt_LV_ShortOutputFlt "Mem fault";
CM_ SG_ 647 DCDC_evt_sw_BMS_CrashFlt "BMS crash";
CM_ SG_ 647 DCDC_evt_BMS_HVILFlt "BMS HV fault";
CM_ SG_ 648 DCFC_evt_BusbarSensFlt "busbar temp out of rangr";
CM_ SG_ 648 DCFC_evt_Contactor_Welded "Contactor weld";
CM_ SG_ 648 DCFC_evt_ContactorStuckOpen "contactor stuck open";
CM_ SG_ 648 DCFC_evt_CP_UnderVoltFlt "Charge port over voltage";
CM_ SG_ 648 DCFC_evt_DataInvalidVCUFlt "Data Invalid VCU fault";
CM_ SG_ 648 DCFC_evt_ChargePortSensFlt "Charge port voltage out of range";
CM_ SG_ 648 DCFC_evt_OverChargePortFlt "Charge port over voltage";
CM_ SG_ 648 DCFC_evt_OverBusbarTemp "busbar over temp";
CM_ SG_ 648 DCFC_evt_E2E_Flt "wrong check sum or rolling counter";
CM_ SG_ 648 DCFC_evt_MIA_Flt "Not receive Message";
CM_ SG_ 1030 Checksum_0x406 "Checksum";
CM_ SG_ 1030 Rolling_Counter_0x406 "Rolling counter";
CM_ SG_ 1030 DCDC_FaultLevel "DCDC error level";
CM_ SG_ 1030 DCFC_FaultLevel "DCFC error level";
CM_ SG_ 522 Checksum_0x20A "Checksum";
CM_ SG_ 522 Rolling_Counter_0x20A "Rolling counter";
CM_ SG_ 522 DCFC_Voltage_Input "voltage fast charge (EVSE)";
CM_ SG_ 522 DCDC_PTC_Temp_Reserved "feedback the temperature of DCDC.(Reserved)";
CM_ SG_ 522 DCFC_Neg_Temp_BusBar "feedback the busbar temperature";
CM_ SG_ 522 DCFC_STATE "status of contactor. (Open, close, stuck..)";
CM_ SG_ 522 DCFC_PTC_Status_Reserved "status of liGBT which control On/Off the PTc.Minino green don't have Heater. This one can ignore.(Reserved)";
CM_ SG_ 992 Checksum_0x3E0 "Checksum";
CM_ SG_ 992 Rolling_Counter_0x3E0 "Rolling counter";
CM_ SG_ 992 EVCC_IPC_Ack_ChgSche_stt "Status Enabled/ Disabled of Schedule Charging acknowledged by EVCC base on request from IPC IPC_ChargeScheduleSet.When this signal value = Enabled, EVCC to follow IPC,IPC_ChargingRequest = Start / Stop to start/ stop charging or stop charging when reach target SOC / battery full / chag.error.";
CM_ SG_ 992 EVCC_IPC_Ack_TargetSOC "Target SOC acknowledged by EVCC base on request from IPC";
CM_ SG_ 725 Checksum_0x2D5 "Check sum";
CM_ SG_ 725 Rolling_Counter_0x2D5 "Rolling counter";
CM_ SG_ 725 VCU_DCDC_Output_REQ "Request DCDC On/Off";
CM_ SG_ 725 VCU_DCDC_OutVoltage_REQ "DCC ouput voltage request";
CM_ SG_ 725 VCU_DCDCAllowedPower "DCDC power request";
CM_ SG_ 673 Checksum_0x2A1 "Checksum";
CM_ SG_ 673 Rolling_Counter_0x2A1 "Rolling_Counter";
CM_ SG_ 673 EVCC_ChargeGunSts "charge gun statue";
CM_ SG_ 673 EVCC_VehicleFailureLevel "EVCC error level";
CM_ SG_ 673 EVCC_ChargeMode "charge mode DC";
CM_ SG_ 673 EVCC_CP_Value "CP dutyvalue";
CM_ SG_ 673 EVCC_CP_Sts "CP State";
CM_ SG_ 673 EVCC_PP_Value "PP resistance value or state";
CM_ SG_ 673 EVCC_Lock_Sts "lock state";
CM_ SG_ 673 EVCC_ErrCode "EVCC_Error code";
CM_ SG_ 673 EVCC_DCFCPortsTempErr "Fast charge ports over temperature error";
CM_ SG_ 682 Checksum_0x2AA "Checksum";
CM_ SG_ 682 Rolling_Counter_0x2AA "Rolling_Counter";
CM_ SG_ 682 EVCC_PLC_CommSts "PLC communication states";
CM_ SG_ 682 EVCC_DC_ChargeProcess "DC charge process";
CM_ SG_ 682 EVCC_BMS_InsulationMonReq "When DC charging, close the BMS insulation detection command";
CM_ SG_ 683 Checksum_0x2AB "Checksum";
CM_ SG_ 683 Rolling_Counter_0x2AB "Rolling_Counter";
CM_ SG_ 683 EVCC_OBC_PowerReq "require power for OBC";
CM_ SG_ 683 EVCC_OBC_VoltageReq "require voltage for OBC";
CM_ SG_ 683 EVCC_OBC_CurrentReq "require current for OBC";
CM_ SG_ 683 EVCC_OBC_Control "Enable/Disable OBC command";
CM_ SG_ 683 EVCC_AC_ChargeSts "AC Charge state";
CM_ SG_ 537 Checksum_0x219 "Checksum";
CM_ SG_ 537 Rolling_Counter_0x219 "Rolling Counter";
CM_ SG_ 537 EVCC_ChargeAllow "The flag of VCU allows BMS charging";
CM_ SG_ 537 EVCC_ChrSOCLitFb "SOC charging limit FeedbackSOC充电限制反馈";
CM_ SG_ 757 Checksum_0x2F5 "Check sum";
CM_ SG_ 757 Rolling_Counter_0x2F5 "Rolling counter";
CM_ SG_ 757 EVCC_Charge_Control "DCFC Charge contactor request";
CM_ SG_ 757 EVCC_DC_chargeSock_temp1 "DC charge SOCK temp1";
CM_ SG_ 757 EVCC_DC_chargeSock_temp2 "DC charge SOCK temp2";
CM_ SG_ 757 EVCC_ChargeIndicatorCtrlSts_Red "VCU_Charge indicator control status_Reserved";
CM_ SG_ 757 EVCC_ChargeIndicatorSts_Red "VCU_Charge indicator error status_Reserved";
CM_ SG_ 854 Checksum_0x356 "Checksum";
CM_ SG_ 854 Rolling_Counter_0x356 "Rolling counter";
CM_ SG_ 854 OBC_WorkStatus "OBC working status";
CM_ SG_ 854 OBC_Sys_STS "OBC System Status";
CM_ SG_ 854 OBC_StartStatus "Output state of the charging machine";
CM_ SG_ 870 Checksum_0x366 "Checksum";
CM_ SG_ 870 Rolling_Counter_0x366 "Rolling counter";
CM_ SG_ 870 OBC_Charge_air_temp "Air temperature of OBC";
CM_ SG_ 870 OBC_Temp "Control board Temperature";
CM_ SG_ 629 Checksum_0x275 "Checksum";
CM_ SG_ 629 Rolling_Counter_0x275 "Rolling counter";
CM_ SG_ 629 OBC_OUT_DC_V "Output Voltage Value of DC High Voltage";
CM_ SG_ 629 OBC_OUT_DC_I "Output Current Value of DC Hight Voltage";
CM_ SG_ 629 OBC_DCCharge_line_V "The voltage between positive and negative DC fast charging high voltage lines";
CM_ SG_ 630 Checksum_0x276 "Checksum";
CM_ SG_ 630 Rolling_Counter_0x276 "Rolling counter";
CM_ SG_ 630 OBC_Input_U "OBC input voltage";
CM_ SG_ 630 OBC_IN_Main_V "The Input Voltage value of OBC (Reserved)";
CM_ SG_ 630 OBC_IN_Main_I "The Input Current value of OBC";
CM_ SG_ 662 Checksum_0x296 "Checksum";
CM_ SG_ 662 Rolling_Counter_0x296 "Rolling counter";
CM_ SG_ 662 OBC_MaxOutputChgU "Maximum output voltage of OBC";
CM_ SG_ 662 OBC_MaxOutputChgI "Maximum output current of OBC";
CM_ SG_ 662 OBC_MaxOutputPwr "Maximum output power of OBC";
CM_ SG_ 1142 OBC_FailGrade_ERR "OBC Fault Status";
CM_ SG_ 1142 OBC_ErrorFlag "Error Flag (Reserved)";
CM_ SG_ 1142 OBC_Hardware_ERR "Hardware Fault";
CM_ SG_ 1142 OBC_OTemp_ERR "Charger Over Temperature Fault";
CM_ SG_ 1142 OBC_OCofOut_ERR "Output Over Current Fault";
CM_ SG_ 1142 OBC_CANcomoverT_ERR "CAN Communication Over Time Fault(LossEVCCNode)";
CM_ SG_ 1142 OBC_UVofIn_ERR "Input Under Voltage Fault";
CM_ SG_ 1142 OBC_OVofIn_ERR "Input Over Voltage Fault";
CM_ SG_ 1142 OBC_OVofPFC_ERR "PFC Over Voltage Fault";
CM_ SG_ 1142 OBC_UVofPFC_ERR "PFC Under Voltage Fault";
CM_ SG_ 1142 OBC_UVofOut_ERR "Output Under Voltage Fault";
CM_ SG_ 1142 OBC_OVofOut_ERR "Output Over Voltage Fault";
CM_ SG_ 1598 OBC_DiagRespData0 "Data0";
CM_ SG_ 1598 OBC_DiagRespData1 "Data1";
CM_ SG_ 1598 OBC_DiagRespData2 "Data2";
CM_ SG_ 1598 OBC_DiagRespData3 "Data3";
CM_ SG_ 1598 OBC_DiagRespData4 "Data4";
CM_ SG_ 1598 OBC_DiagRespData5 "Data5";
CM_ SG_ 1598 OBC_DiagRespData6 "Data6";
CM_ SG_ 1598 OBC_DiagRespData7 "Data7";
CM_ SG_ 1726 OBC_DiagReqData0 "Data0";
CM_ SG_ 1726 OBC_DiagReqData1 "Data1";
CM_ SG_ 1726 OBC_DiagReqData2 "Data2";
CM_ SG_ 1726 OBC_DiagReqData3 "Data3";
CM_ SG_ 1726 OBC_DiagReqData4 "Data4";
CM_ SG_ 1726 OBC_DiagReqData5 "Data5";
CM_ SG_ 1726 OBC_DiagReqData6 "Data6";
CM_ SG_ 1726 OBC_DiagReqData7 "Data7";
CM_ SG_ 1683 BMS_DiagReqData0 "Data0";
CM_ SG_ 1683 BMS_DiagReqData1 "Data1";
CM_ SG_ 1683 BMS_DiagReqData2 "Data2";
CM_ SG_ 1683 BMS_DiagReqData3 "Data3";
CM_ SG_ 1683 BMS_DiagReqData4 "Data4";
CM_ SG_ 1683 BMS_DiagReqData5 "Data5";
CM_ SG_ 1683 BMS_DiagReqData6 "Data6";
CM_ SG_ 1683 BMS_DiagReqData7 "Data7";
CM_ SG_ 1555 BMS_DiagRespData0 "Data0";
CM_ SG_ 1555 BMS_DiagRespData1 "Data1";
CM_ SG_ 1555 BMS_DiagRespData2 "Data2";
CM_ SG_ 1555 BMS_DiagRespData3 "Data3";
CM_ SG_ 1555 BMS_DiagRespData4 "Data4";
CM_ SG_ 1555 BMS_DiagRespData5 "Data5";
CM_ SG_ 1555 BMS_DiagRespData6 "Data6";
CM_ SG_ 1555 BMS_DiagRespData7 "Data7";
CM_ SG_ 1704 EPS_DiagReqData0 "Data0";
CM_ SG_ 1704 EPS_DiagReqData1 "Data1";
CM_ SG_ 1704 EPS_DiagReqData2 "Data2";
CM_ SG_ 1704 EPS_DiagReqData3 "Data3";
CM_ SG_ 1704 EPS_DiagReqData4 "Data4";
CM_ SG_ 1704 EPS_DiagReqData5 "Data5";
CM_ SG_ 1704 EPS_DiagReqData6 "Data6";
CM_ SG_ 1704 EPS_DiagReqData7 "Data7";
CM_ SG_ 1576 EPS_DiagRespData0 "Data0";
CM_ SG_ 1576 EPS_DiagRespData1 "Data1";
CM_ SG_ 1576 EPS_DiagRespData2 "Data2";
CM_ SG_ 1576 EPS_DiagRespData3 "Data3";
CM_ SG_ 1576 EPS_DiagRespData4 "Data4";
CM_ SG_ 1576 EPS_DiagRespData5 "Data5";
CM_ SG_ 1576 EPS_DiagRespData6 "Data6";
CM_ SG_ 1576 EPS_DiagRespData7 "Data7";
CM_ SG_ 1691 EDS_DiagReqData0 "Data0";
CM_ SG_ 1691 EDS_DiagReqData1 "Data1";
CM_ SG_ 1691 EDS_DiagReqData2 "Data2";
CM_ SG_ 1691 EDS_DiagReqData3 "Data3";
CM_ SG_ 1691 EDS_DiagReqData4 "Data4";
CM_ SG_ 1691 EDS_DiagReqData5 "Data5";
CM_ SG_ 1691 EDS_DiagReqData6 "Data6";
CM_ SG_ 1691 EDS_DiagReqData7 "Data7";
CM_ SG_ 1563 EDS_DiagRespData0 "Data0";
CM_ SG_ 1563 EDS_DiagRespData1 "Data1";
CM_ SG_ 1563 EDS_DiagRespData2 "Data2";
CM_ SG_ 1563 EDS_DiagRespData3 "Data3";
CM_ SG_ 1563 EDS_DiagRespData4 "Data4";
CM_ SG_ 1563 EDS_DiagRespData5 "Data5";
CM_ SG_ 1563 EDS_DiagRespData6 "Data6";
CM_ SG_ 1563 EDS_DiagRespData7 "Data7";
CM_ SG_ 1725 DCDC_DiagReqData0 "Data0";
CM_ SG_ 1725 DCDC_DiagReqData1 "Data1";
CM_ SG_ 1725 DCDC_DiagReqData2 "Data2";
CM_ SG_ 1725 DCDC_DiagReqData3 "Data3";
CM_ SG_ 1725 DCDC_DiagReqData4 "Data4";
CM_ SG_ 1725 DCDC_DiagReqData5 "Data5";
CM_ SG_ 1725 DCDC_DiagReqData6 "Data6";
CM_ SG_ 1725 DCDC_DiagReqData7 "Data7";
CM_ SG_ 1597 DCDC_DiagRespData0 "Data0";
CM_ SG_ 1597 DCDC_DiagRespData1 "Data1";
CM_ SG_ 1597 DCDC_DiagRespData2 "Data2";
CM_ SG_ 1597 DCDC_DiagRespData3 "Data3";
CM_ SG_ 1597 DCDC_DiagRespData4 "Data4";
CM_ SG_ 1597 DCDC_DiagRespData5 "Data5";
CM_ SG_ 1597 DCDC_DiagRespData6 "Data6";
CM_ SG_ 1597 DCDC_DiagRespData7 "Data7";
CM_ SG_ 1695 EVCC_DiagReqData0 "Data0";
CM_ SG_ 1695 EVCC_DiagReqData1 "Data1";
CM_ SG_ 1695 EVCC_DiagReqData2 "Data2";
CM_ SG_ 1695 EVCC_DiagReqData3 "Data3";
CM_ SG_ 1695 EVCC_DiagReqData4 "Data4";
CM_ SG_ 1695 EVCC_DiagReqData5 "Data5";
CM_ SG_ 1695 EVCC_DiagReqData6 "Data6";
CM_ SG_ 1695 EVCC_DiagReqData7 "Data7";
CM_ SG_ 1567 EVCC_DiagRespData0 "Data0";
CM_ SG_ 1567 EVCC_DiagRespData1 "Data1";
CM_ SG_ 1567 EVCC_DiagRespData2 "Data2";
CM_ SG_ 1567 EVCC_DiagRespData3 "Data3";
CM_ SG_ 1567 EVCC_DiagRespData4 "Data4";
CM_ SG_ 1567 EVCC_DiagRespData5 "Data5";
CM_ SG_ 1567 EVCC_DiagRespData6 "Data6";
CM_ SG_ 1567 EVCC_DiagRespData7 "Data7";
CM_ SG_ 1791 DiagFunctionalAddressingData0 "Data0";
CM_ SG_ 1791 DiagFunctionalAddressingData1 "Data1";
CM_ SG_ 1791 DiagFunctionalAddressingData2 "Data2";
CM_ SG_ 1791 DiagFunctionalAddressingData3 "Data3";
CM_ SG_ 1791 DiagFunctionalAddressingData4 "Data4";
CM_ SG_ 1791 DiagFunctionalAddressingData5 "Data5";
CM_ SG_ 1791 DiagFunctionalAddressingData6 "Data6";
CM_ SG_ 1791 DiagFunctionalAddressingData7 "Data7";
CM_ SG_ 1324 VCU_sourceID "source ID";
CM_ SG_ 1324 VCU_CBV "CBV";
CM_ SG_ 1324 VCU_Data0 "Data0";
CM_ SG_ 1324 VCU_Data1 "Data1";
CM_ SG_ 1324 VCU_Data2 "Data2";
CM_ SG_ 1324 VCU_Data3 "Data3";
CM_ SG_ 1324 VCU_Data4 "Data4";
CM_ SG_ 1324 VCU_Data5 "Data5";
CM_ SG_ 1299 BMS_sourceID "source ID";
CM_ SG_ 1299 BMS_CBV "CBV";
CM_ SG_ 1299 BMS_Data0 "Data0";
CM_ SG_ 1299 BMS_Data1 "Data1";
CM_ SG_ 1299 BMS_Data2 "Data2";
CM_ SG_ 1299 BMS_Data3 "Data3";
CM_ SG_ 1299 BMS_Data4 "Data4";
CM_ SG_ 1299 BMS_Data5 "Data5";
CM_ SG_ 1341 PDU_DCDC_sourceID "source IDsource ID";
CM_ SG_ 1341 PDU_DCDC_CBV "CBV";
CM_ SG_ 1341 PDU_DCDC_Data0 "Data0Data0";
CM_ SG_ 1341 PDU_DCDC_Data1 "Data1Data1";
CM_ SG_ 1341 PDU_DCDC_Data2 "Data2Data2";
CM_ SG_ 1341 PDU_DCDC_Data3 "Data3Data3";
CM_ SG_ 1341 PDU_DCDC_Data4 "Data4Data4";
CM_ SG_ 1341 PDU_DCDC_Data5 "Data5Data5";
CM_ SG_ 1311 EVCC_sourceID "source IDsource ID";
CM_ SG_ 1311 EVCC_CBV "CBV";
CM_ SG_ 1311 EVCC_Data0 "Data0Data0";
CM_ SG_ 1311 EVCC_Data1 "Data1Data1";
CM_ SG_ 1311 EVCC_Data2 "Data2Data2";
CM_ SG_ 1311 EVCC_Data3 "Data3Data3";
CM_ SG_ 1311 EVCC_Data4 "Data4Data4";
CM_ SG_ 1311 EVCC_Data5 "Data5Data5";
CM_ SG_ 1342 OBC_sourceID "source IDsource ID";
CM_ SG_ 1342 OBC_CBV "CBV";
CM_ SG_ 1342 OBC_Data0 "Data0Data0";
CM_ SG_ 1342 OBC_Data1 "Data1Data1";
CM_ SG_ 1342 OBC_Data2 "Data2Data2";
CM_ SG_ 1342 OBC_Data3 "Data3Data3";
CM_ SG_ 1342 OBC_Data4 "Data4Data4";
CM_ SG_ 1342 OBC_Data5 "Data5Data5";
BA_DEF_ BO_  "DiagRequest" ENUM  "No","Yes";
BA_DEF_ BO_  "DiagResponse" ENUM  "No","Yes";
BA_DEF_ BO_  "GenMsgCycleTime" INT 0 65535;
BA_DEF_ BO_  "GenMsgCycleTimeFast" INT 0 65535;
BA_DEF_ BO_  "GenMsgDelayTime" INT 0 65535;
BA_DEF_ BO_  "GenMsgILSupport" ENUM  "No","Yes";
BA_DEF_ BO_  "GenMsgNrOfRepetition" INT 0 65535;
BA_DEF_ BO_  "GenMsgSendType" ENUM  "Cycle","Event","IfActive","CE","CA";
BA_DEF_ BO_  "NmAsrMessage" ENUM  "No","Yes";
BA_DEF_ BO_  "NmMessage" ENUM  "No","Yes";
BA_DEF_ SG_  "GenSigSendType" ENUM  "Cycle","OnWrite","OnWriteWithRepetition","OnChange","OnChangeWithRepetition","IfActive","IfActiveWithRepetition";
BA_DEF_ SG_  "GenSigStartValue" INT 0 2147483647;
BA_DEF_ SG_  "GenSigInvalidValue" INT 0 2147483647;
BA_DEF_ SG_  "GenSigInactiveValue" INT 0 2147483647;
BA_DEF_DEF_  "DiagRequest" "No";
BA_DEF_DEF_  "DiagResponse" "No";
BA_DEF_DEF_  "GenMsgCycleTime" 0;
BA_DEF_DEF_  "GenMsgCycleTimeFast" 0;
BA_DEF_DEF_  "GenMsgDelayTime" 0;
BA_DEF_DEF_  "GenMsgILSupport" "Yes";
BA_DEF_DEF_  "GenMsgNrOfRepetition" 0;
BA_DEF_DEF_  "GenMsgSendType" "";
BA_DEF_DEF_  "NmAsrMessage" "No";
BA_DEF_DEF_  "NmMessage" "No";
BA_DEF_DEF_  "GenSigSendType" "";
BA_DEF_DEF_  "GenSigStartValue" 0;
BA_DEF_DEF_  "GenSigInvalidValue" 0;
BA_DEF_DEF_  "GenSigInactiveValue" 0;
BA_ "GenMsgCycleTime" BO_ 374 50;
BA_ "GenMsgSendType" BO_ 374 0;
BA_ "GenMsgCycleTime" BO_ 375 50;
BA_ "GenMsgSendType" BO_ 375 0;
BA_ "GenMsgCycleTime" BO_ 372 20;
BA_ "GenMsgSendType" BO_ 372 0;
BA_ "GenMsgCycleTime" BO_ 532 50;
BA_ "GenMsgSendType" BO_ 532 0;
BA_ "GenMsgCycleTime" BO_ 533 50;
BA_ "GenMsgSendType" BO_ 533 0;
BA_ "GenMsgCycleTime" BO_ 549 100;
BA_ "GenMsgSendType" BO_ 549 0;
BA_ "GenMsgCycleTime" BO_ 293 20;
BA_ "GenMsgSendType" BO_ 293 0;
BA_ "GenMsgCycleTime" BO_ 885 50;
BA_ "GenMsgSendType" BO_ 885 0;
BA_ "GenMsgCycleTime" BO_ 517 20;
BA_ "GenMsgSendType" BO_ 517 0;
BA_ "GenMsgCycleTime" BO_ 581 20;
BA_ "GenMsgSendType" BO_ 581 0;
BA_ "GenMsgCycleTime" BO_ 773 100;
BA_ "GenMsgSendType" BO_ 773 0;
BA_ "GenMsgCycleTime" BO_ 1171 1000;
BA_ "GenMsgSendType" BO_ 1171 0;
BA_ "GenMsgCycleTime" BO_ 1109 100;
BA_ "GenMsgSendType" BO_ 1109 0;
BA_ "GenMsgCycleTime" BO_ 1504 50;
BA_ "GenMsgSendType" BO_ 1504 0;
BA_ "GenMsgCycleTime" BO_ 1505 100;
BA_ "GenMsgSendType" BO_ 1505 0;
BA_ "GenMsgCycleTime" BO_ 1506 100;
BA_ "GenMsgSendType" BO_ 1506 0;
BA_ "GenMsgCycleTime" BO_ 1507 100;
BA_ "GenMsgSendType" BO_ 1507 0;
BA_ "GenMsgCycleTime" BO_ 1508 100;
BA_ "GenMsgSendType" BO_ 1508 0;
BA_ "GenMsgCycleTime" BO_ 523 100;
BA_ "GenMsgSendType" BO_ 523 0;
BA_ "GenMsgCycleTime" BO_ 646 20;
BA_ "GenMsgSendType" BO_ 646 0;
BA_ "GenMsgCycleTime" BO_ 647 100;
BA_ "GenMsgSendType" BO_ 647 0;
BA_ "GenMsgCycleTime" BO_ 648 100;
BA_ "GenMsgSendType" BO_ 648 0;
BA_ "GenMsgCycleTime" BO_ 1030 1000;
BA_ "GenMsgSendType" BO_ 1030 0;
BA_ "GenMsgCycleTime" BO_ 522 100;
BA_ "GenMsgSendType" BO_ 522 0;
BA_ "GenMsgCycleTime" BO_ 992 100;
BA_ "GenMsgSendType" BO_ 992 0;
BA_ "GenMsgCycleTime" BO_ 725 50;
BA_ "GenMsgSendType" BO_ 725 0;
BA_ "GenMsgCycleTime" BO_ 673 100;
BA_ "GenMsgSendType" BO_ 673 0;
BA_ "GenMsgCycleTime" BO_ 682 100;
BA_ "GenMsgSendType" BO_ 682 0;
BA_ "GenMsgCycleTime" BO_ 683 100;
BA_ "GenMsgSendType" BO_ 683 0;
BA_ "GenMsgCycleTime" BO_ 537 20;
BA_ "GenMsgSendType" BO_ 537 0;
BA_ "GenMsgCycleTime" BO_ 757 100;
BA_ "GenMsgSendType" BO_ 757 0;
BA_ "GenMsgCycleTime" BO_ 854 50;
BA_ "GenMsgSendType" BO_ 854 0;
BA_ "GenMsgCycleTime" BO_ 870 20;
BA_ "GenMsgSendType" BO_ 870 0;
BA_ "GenMsgCycleTime" BO_ 629 20;
BA_ "GenMsgSendType" BO_ 629 0;
BA_ "GenMsgCycleTime" BO_ 630 20;
BA_ "GenMsgSendType" BO_ 630 0;
BA_ "GenMsgCycleTime" BO_ 662 20;
BA_ "GenMsgSendType" BO_ 662 0;
BA_ "GenMsgCycleTime" BO_ 1142 100;
BA_ "GenMsgSendType" BO_ 1142 0;
BA_ "DiagResponse" BO_ 1598 1;
BA_ "GenMsgSendType" BO_ 1598 1;
BA_ "DiagRequest" BO_ 1726 1;
BA_ "GenMsgSendType" BO_ 1726 1;
BA_ "DiagRequest" BO_ 1683 1;
BA_ "GenMsgSendType" BO_ 1683 1;
BA_ "DiagResponse" BO_ 1555 1;
BA_ "GenMsgSendType" BO_ 1555 1;
BA_ "DiagRequest" BO_ 1704 1;
BA_ "GenMsgSendType" BO_ 1704 1;
BA_ "DiagResponse" BO_ 1576 1;
BA_ "GenMsgSendType" BO_ 1576 1;
BA_ "DiagRequest" BO_ 1691 1;
BA_ "GenMsgSendType" BO_ 1691 1;
BA_ "DiagResponse" BO_ 1563 1;
BA_ "GenMsgSendType" BO_ 1563 1;
BA_ "DiagRequest" BO_ 1725 1;
BA_ "GenMsgSendType" BO_ 1725 1;
BA_ "DiagResponse" BO_ 1597 1;
BA_ "GenMsgSendType" BO_ 1597 1;
BA_ "DiagRequest" BO_ 1695 1;
BA_ "GenMsgSendType" BO_ 1695 1;
BA_ "DiagResponse" BO_ 1567 1;
BA_ "GenMsgSendType" BO_ 1567 1;
BA_ "DiagRequest" BO_ 1791 1;
BA_ "GenMsgSendType" BO_ 1791 1;
BA_ "NmMessage" BO_ 1324 1;
BA_ "NmAsrMessage" BO_ 1324 1;
BA_ "GenMsgCycleTime" BO_ 1324 640;
BA_ "GenMsgSendType" BO_ 1324 0;
BA_ "NmMessage" BO_ 1299 1;
BA_ "NmAsrMessage" BO_ 1299 1;
BA_ "GenMsgCycleTime" BO_ 1299 640;
BA_ "GenMsgSendType" BO_ 1299 0;
BA_ "NmMessage" BO_ 1341 1;
BA_ "NmAsrMessage" BO_ 1341 1;
BA_ "GenMsgCycleTime" BO_ 1341 640;
BA_ "GenMsgSendType" BO_ 1341 0;
BA_ "NmMessage" BO_ 1311 1;
BA_ "NmAsrMessage" BO_ 1311 1;
BA_ "GenMsgCycleTime" BO_ 1311 640;
BA_ "GenMsgSendType" BO_ 1311 0;
BA_ "NmMessage" BO_ 1342 1;
BA_ "NmAsrMessage" BO_ 1342 1;
BA_ "GenMsgCycleTime" BO_ 1342 640;
BA_ "GenMsgSendType" BO_ 1342 0;
BA_ "GenSigStartValue" SG_ 374 Checksum_0x176 255;
BA_ "GenSigSendType" SG_ 374 Checksum_0x176 0;
BA_ "GenSigInvalidValue" SG_ 374 Rolling_Counter_0x176 15;
BA_ "GenSigSendType" SG_ 374 Rolling_Counter_0x176 0;
BA_ "GenSigInvalidValue" SG_ 374 BMS_HVLinkVol_MEAS 65535;
BA_ "GenSigSendType" SG_ 374 BMS_HVLinkVol_MEAS 0;
BA_ "GenSigInvalidValue" SG_ 374 BMS_HVPackVol_MEAS 65535;
BA_ "GenSigSendType" SG_ 374 BMS_HVPackVol_MEAS 0;
BA_ "GenSigStartValue" SG_ 375 Checksum_0x177 255;
BA_ "GenSigSendType" SG_ 375 Checksum_0x177 0;
BA_ "GenSigInvalidValue" SG_ 375 Rolling_Counter_0x177 15;
BA_ "GenSigSendType" SG_ 375 Rolling_Counter_0x177 0;
BA_ "GenSigInvalidValue" SG_ 375 BMS_HVBusVol_MEAS 65535;
BA_ "GenSigSendType" SG_ 375 BMS_HVBusVol_MEAS 0;
BA_ "GenSigInvalidValue" SG_ 375 BMS_HVFuseVol_MEAS 65535;
BA_ "GenSigSendType" SG_ 375 BMS_HVFuseVol_MEAS 0;
BA_ "GenSigStartValue" SG_ 372 Checksum_0x174 255;
BA_ "GenSigSendType" SG_ 372 Checksum_0x174 0;
BA_ "GenSigInvalidValue" SG_ 372 Rolling_Counter_0x174 15;
BA_ "GenSigSendType" SG_ 372 Rolling_Counter_0x174 0;
BA_ "GenSigStartValue" SG_ 372 BMS_PackCur_MEAS 32768;
BA_ "GenSigInvalidValue" SG_ 372 BMS_PackCur_MEAS 65535;
BA_ "GenSigSendType" SG_ 372 BMS_PackCur_MEAS 0;
BA_ "GenSigInvalidValue" SG_ 372 BMS_AllowDischgCurr 65535;
BA_ "GenSigSendType" SG_ 372 BMS_AllowDischgCurr 0;
BA_ "GenSigInvalidValue" SG_ 372 BMS_AllowDischgCurrPeak 65535;
BA_ "GenSigSendType" SG_ 372 BMS_AllowDischgCurrPeak 0;
BA_ "GenSigStartValue" SG_ 532 Checksum_0x214 255;
BA_ "GenSigSendType" SG_ 532 Checksum_0x214 0;
BA_ "GenSigInvalidValue" SG_ 532 Rolling_Counter_0x214 15;
BA_ "GenSigSendType" SG_ 532 Rolling_Counter_0x214 0;
BA_ "GenSigStartValue" SG_ 532 BMS_Display_SOC 100;
BA_ "GenSigInvalidValue" SG_ 532 BMS_Display_SOC 1023;
BA_ "GenSigSendType" SG_ 532 BMS_Display_SOC 0;
BA_ "GenSigSendType" SG_ 532 BMS_SocActual_EST 0;
BA_ "GenSigStartValue" SG_ 532 BMS_SOH 54;
BA_ "GenSigSendType" SG_ 532 BMS_SOH 0;
BA_ "GenSigStartValue" SG_ 533 Checksum_0x215 255;
BA_ "GenSigSendType" SG_ 533 Checksum_0x215 0;
BA_ "GenSigInvalidValue" SG_ 533 Rolling_Counter_0x215 15;
BA_ "GenSigSendType" SG_ 533 Rolling_Counter_0x215 0;
BA_ "GenSigStartValue" SG_ 533 BMS_SOE 54;
BA_ "GenSigSendType" SG_ 533 BMS_SOE 0;
BA_ "GenSigSendType" SG_ 533 BMS_HWCrash_Sts 0;
BA_ "GenSigSendType" SG_ 533 BMS_HVIL_STS 0;
BA_ "GenSigSendType" SG_ 533 BMS_IGN_Sts 0;
BA_ "GenSigSendType" SG_ 533 BMS_Sys_STS 0;
BA_ "GenSigSendType" SG_ 533 BMS_HVOnOff_STS 0;
BA_ "GenSigSendType" SG_ 533 BMS_Balance_STS 0;
BA_ "GenSigSendType" SG_ 533 BMS_BatBalance_ERR 0;
BA_ "GenSigSendType" SG_ 533 BMS_ISU_Status 0;
BA_ "GenSigSendType" SG_ 533 BMS_ERR_LEV 0;
BA_ "GenSigSendType" SG_ 533 BMS_Vehicle_ERR_LEV 0;
BA_ "GenSigSendType" SG_ 533 BMS_HV_Sts 0;
BA_ "GenSigStartValue" SG_ 549 Checksum_0x225 255;
BA_ "GenSigSendType" SG_ 549 Checksum_0x225 0;
BA_ "GenSigInvalidValue" SG_ 549 Rolling_Counter_0x225 15;
BA_ "GenSigSendType" SG_ 549 Rolling_Counter_0x225 0;
BA_ "GenSigSendType" SG_ 549 CDM_bAcvCanComStblMon 0;
BA_ "GenSigSendType" SG_ 549 FRMo_bErrHvbatStReqExtMon 0;
BA_ "GenSigSendType" SG_ 549 FRMo_bErrChrgnAllwdExtMon 0;
BA_ "GenSigSendType" SG_ 549 FRMo_bErrVehCrashStExtMon 0;
BA_ "GenSigSendType" SG_ 549 CDM_bErrComctnLossCanMon 0;
BA_ "GenSigSendType" SG_ 549 CTCMon_bErrCtctrSopcMon 0;
BA_ "GenSigSendType" SG_ 549 CTCMon_bInvldCtctrHisdIFbMon 0;
BA_ "GenSigSendType" SG_ 549 CTCMon_bInvldCtctrLosdUFbMon 0;
BA_ "GenSigSendType" SG_ 549 CTM_bErrCellTDifMaxMon 0;
BA_ "GenSigSendType" SG_ 549 CTM_bErrCellTMaxMon 0;
BA_ "GenSigSendType" SG_ 549 CTM_bErrCellTMinMon 0;
BA_ "GenSigSendType" SG_ 549 CTM_bErrThrwyPredMon 0;
BA_ "GenSigSendType" SG_ 549 CUM_bErrCellUDifMaxMon 0;
BA_ "GenSigSendType" SG_ 549 CUM_bErrCellUMaxMon 0;
BA_ "GenSigSendType" SG_ 549 CUM_bErrCellUMinMon 0;
BA_ "GenSigSendType" SG_ 549 CUM_bErrCellUProtnMaxNvMon 0;
BA_ "GenSigSendType" SG_ 549 CUM_bErrCellUProtnMinNvMon 0;
BA_ "GenSigSendType" SG_ 549 CUM_bErrPackUImplyMon 0;
BA_ "GenSigSendType" SG_ 549 EHPMon_bRdyHvilMon 0;
BA_ "GenSigSendType" SG_ 549 EHPMon_bErrWlddNegNvMon 0;
BA_ "GenSigSendType" SG_ 549 EHPMon_bErrWlddPosNvMon 0;
BA_ "GenSigSendType" SG_ 549 EHPMon_bErrWlddPrechNvMon 0;
BA_ "GenSigSendType" SG_ 549 EHPMon_bErrHvilMon 0;
BA_ "GenSigSendType" SG_ 549 EHPMon_bErrHvilShoMon 0;
BA_ "GenSigSendType" SG_ 549 EHPMon_bErrPackIslnRNvMon 0;
BA_ "GenSigSendType" SG_ 549 EHPMon_bErrVehCrashNvMon 0;
BA_ "GenSigSendType" SG_ 549 EHPMon_bErrVehIslnRNvMon 0;
BA_ "GenSigSendType" SG_ 549 FRMo_bErrMemStorgNvMon 0;
BA_ "GenSigSendType" SG_ 549 L1IM_bErrClmp30MaxMonInp 0;
BA_ "GenSigSendType" SG_ 549 L1IM_bErrClmp30MinMonInp 0;
BA_ "GenSigSendType" SG_ 549 L1IM_bErrCtctrDtrtMonInp 0;
BA_ "GenSigSendType" SG_ 549 L1IM_bErrUActImplyMonInp 0;
BA_ "GenSigSendType" SG_ 549 MCCM_bAcvMdulCtlrStsMon 0;
BA_ "GenSigSendType" SG_ 549 MCCM_bErrLntecSngFltMon 0;
BA_ "GenSigSendType" SG_ 549 MCCM_bErrLntecLtntFltMon 0;
BA_ "GenSigSendType" SG_ 549 MCCM_bErrMdulCellSnsrCfgMon 0;
BA_ "GenSigSendType" SG_ 549 MCCM_bErrMdulCtlrComMon 0;
BA_ "GenSigSendType" SG_ 549 MCCM_bErrSnsrTEltlMon 0;
BA_ "GenSigSendType" SG_ 549 MCCM_bWarnSnsrTEltlMon 0;
BA_ "GenSigSendType" SG_ 549 PCM_bRdySnsrIMon 0;
BA_ "GenSigSendType" SG_ 549 PCM_bErrPackEFlowMaxLimMon 0;
BA_ "GenSigSendType" SG_ 549 PCM_bErrPackIChDchaMaxLimMon 0;
BA_ "GenSigSendType" SG_ 549 PCM_bErrSnsrIImplyMon 0;
BA_ "GenSigSendType" SG_ 549 FRMo_bErrSnsrI1ExtMon 0;
BA_ "GenSigSendType" SG_ 549 PCM_bInvldSnsrI1Mon 0;
BA_ "GenSigSendType" SG_ 549 PCM_bInvldSnsrI2Mon 0;
BA_ "GenSigSendType" SG_ 549 FRMo_bErrSopcLvl3Mon 0;
BA_ "GenSigSendType" SG_ 549 BMS_FRMo_Reserved_1 0;
BA_ "GenSigSendType" SG_ 549 BMS_FRMo_Reserved_2 0;
BA_ "GenSigSendType" SG_ 549 BMS_FRMo_Reserved_3 0;
BA_ "GenSigSendType" SG_ 549 BMS_FRMo_Reserved_4 0;
BA_ "GenSigSendType" SG_ 549 BMS_FRMo_Reserved_5 0;
BA_ "GenSigStartValue" SG_ 293 Checksum_0x125 255;
BA_ "GenSigSendType" SG_ 293 Checksum_0x125 0;
BA_ "GenSigInvalidValue" SG_ 293 Rolling_Counter_0x125 15;
BA_ "GenSigSendType" SG_ 293 Rolling_Counter_0x125 0;
BA_ "GenSigInvalidValue" SG_ 293 BMS_Actual_ChgPower 32767;
BA_ "GenSigSendType" SG_ 293 BMS_Actual_ChgPower 0;
BA_ "GenSigInvalidValue" SG_ 293 BMS_Actual_DisChgPower 32767;
BA_ "GenSigSendType" SG_ 293 BMS_Actual_DisChgPower 0;
BA_ "GenSigStartValue" SG_ 885 Checksum_0x375 255;
BA_ "GenSigSendType" SG_ 885 Checksum_0x375 0;
BA_ "GenSigInvalidValue" SG_ 885 Rolling_Counter_0x375 15;
BA_ "GenSigSendType" SG_ 885 Rolling_Counter_0x375 0;
BA_ "GenSigSendType" SG_ 885 BMS_MainPosRelay_ERR 0;
BA_ "GenSigInvalidValue" SG_ 885 BMS_MainPosRelay_STS 7;
BA_ "GenSigSendType" SG_ 885 BMS_MainPosRelay_STS 0;
BA_ "GenSigSendType" SG_ 885 BMS_PreChgRelay_ERR 0;
BA_ "GenSigInvalidValue" SG_ 885 BMS_PreChgRelay_STS 7;
BA_ "GenSigSendType" SG_ 885 BMS_PreChgRelay_STS 0;
BA_ "GenSigInvalidValue" SG_ 885 BMS_TotalNegRelay_STS 7;
BA_ "GenSigSendType" SG_ 885 BMS_TotalNegRelay_STS 0;
BA_ "GenSigSendType" SG_ 885 BMS_TotalNegRelay_ERR 0;
BA_ "GenSigStartValue" SG_ 517 Checksum_0x205 255;
BA_ "GenSigSendType" SG_ 517 Checksum_0x205 0;
BA_ "GenSigInvalidValue" SG_ 517 Rolling_Counter_0x205 15;
BA_ "GenSigSendType" SG_ 517 Rolling_Counter_0x205 0;
BA_ "GenSigInvalidValue" SG_ 517 BMS_MaxCellVol 8191;
BA_ "GenSigSendType" SG_ 517 BMS_MaxCellVol 0;
BA_ "GenSigSendType" SG_ 517 BMS_CellNumMaxCellVol 0;
BA_ "GenSigInvalidValue" SG_ 517 BMS_MinCellVol 8191;
BA_ "GenSigSendType" SG_ 517 BMS_MinCellVol 0;
BA_ "GenSigSendType" SG_ 517 BMS_CellNumMinCellVol 0;
BA_ "GenSigStartValue" SG_ 581 Checksum_0x245 255;
BA_ "GenSigSendType" SG_ 581 Checksum_0x245 0;
BA_ "GenSigInvalidValue" SG_ 581 Rolling_Counter_0x245 15;
BA_ "GenSigSendType" SG_ 581 Rolling_Counter_0x245 0;
BA_ "GenSigStartValue" SG_ 581 BMS_PackTemp 80;
BA_ "GenSigInvalidValue" SG_ 581 BMS_PackTemp 255;
BA_ "GenSigSendType" SG_ 581 BMS_PackTemp 0;
BA_ "GenSigStartValue" SG_ 581 BMS_MaxMinDiffCellTemp 80;
BA_ "GenSigInvalidValue" SG_ 581 BMS_MaxMinDiffCellTemp 255;
BA_ "GenSigSendType" SG_ 581 BMS_MaxMinDiffCellTemp 0;
BA_ "GenSigStartValue" SG_ 581 BMS_MaxCellTemp 80;
BA_ "GenSigInvalidValue" SG_ 581 BMS_MaxCellTemp 255;
BA_ "GenSigSendType" SG_ 581 BMS_MaxCellTemp 0;
BA_ "GenSigStartValue" SG_ 581 BMS_MinCellTemp 80;
BA_ "GenSigInvalidValue" SG_ 581 BMS_MinCellTemp 255;
BA_ "GenSigSendType" SG_ 581 BMS_MinCellTemp 0;
BA_ "GenSigStartValue" SG_ 581 BMS_ProbeNumMaxCellTemp 1;
BA_ "GenSigSendType" SG_ 581 BMS_ProbeNumMaxCellTemp 0;
BA_ "GenSigSendType" SG_ 581 BMS_ProbeNumMinCellTemp 0;
BA_ "GenSigStartValue" SG_ 773 Checksum_0x305 255;
BA_ "GenSigSendType" SG_ 773 Checksum_0x305 0;
BA_ "GenSigInvalidValue" SG_ 773 Rolling_Counter_0x305 15;
BA_ "GenSigSendType" SG_ 773 Rolling_Counter_0x305 0;
BA_ "GenSigSendType" SG_ 773 BMS_VCU_Insulation_Mon_Sts 0;
BA_ "GenSigStartValue" SG_ 773 BMS_PackInsuRes 5535;
BA_ "GenSigSendType" SG_ 773 BMS_PackInsuRes 0;
BA_ "GenSigSendType" SG_ 1171 BMS_Warning_Flag_Reserved_08 0;
BA_ "GenSigSendType" SG_ 1171 BMS_Warning_Flag_Reserved_07 0;
BA_ "GenSigSendType" SG_ 1171 BMS_Warning_Flag_Reserved_11 0;
BA_ "GenSigSendType" SG_ 1171 BMS_Warning_Flag_Reserved_10 0;
BA_ "GenSigSendType" SG_ 1171 BMS_Warning_Flag_Reserved_09 0;
BA_ "GenSigSendType" SG_ 1171 BMS_Warning_Flag_Reserved_13 0;
BA_ "GenSigSendType" SG_ 1171 BMS_Warning_Flag_Reserved_12 0;
BA_ "GenSigSendType" SG_ 1171 BMS_Warning_Flag_Reserved_06 0;
BA_ "GenSigSendType" SG_ 1171 BMS_Warning_Flag_Reserved_05 0;
BA_ "GenSigSendType" SG_ 1171 BMS_Warning_Flag_Reserved_04 0;
BA_ "GenSigSendType" SG_ 1171 BMS_MalfunctionSts 0;
BA_ "GenSigInvalidValue" SG_ 1171 BMS_LowBattery 3;
BA_ "GenSigSendType" SG_ 1171 BMS_LowBattery 0;
BA_ "GenSigSendType" SG_ 1171 BMS_BatteryReplacement 0;
BA_ "GenSigSendType" SG_ 1171 BMS_PackTempSts 0;
BA_ "GenSigSendType" SG_ 1171 BMS_ThermalRunaway 0;
BA_ "GenSigInvalidValue" SG_ 1171 Rolling_Counter_0x493 15;
BA_ "GenSigSendType" SG_ 1171 Rolling_Counter_0x493 0;
BA_ "GenSigStartValue" SG_ 1171 Checksum_0x493 255;
BA_ "GenSigSendType" SG_ 1171 Checksum_0x493 0;
BA_ "GenSigStartValue" SG_ 1109 Checksum_0x455 255;
BA_ "GenSigSendType" SG_ 1109 Checksum_0x455 0;
BA_ "GenSigInvalidValue" SG_ 1109 Rolling_Counter_0x455 15;
BA_ "GenSigSendType" SG_ 1109 Rolling_Counter_0x455 0;
BA_ "GenSigSendType" SG_ 1109 BMS_PackInsu_ERR 0;
BA_ "GenSigSendType" SG_ 1109 BMS_CellVoltDiff_ERR 0;
BA_ "GenSigSendType" SG_ 1109 BMS_PackOverCurr_ERR 0;
BA_ "GenSigSendType" SG_ 1109 BMS_HVIL_Err 0;
BA_ "GenSigSendType" SG_ 1109 BMS_CellHighVol_ERR 0;
BA_ "GenSigSendType" SG_ 1109 BMS_CellLowVol_ERR 0;
BA_ "GenSigSendType" SG_ 1109 BMS_PackLowVol_ERR 0;
BA_ "GenSigSendType" SG_ 1109 BMS_PackHighVol_ERR 0;
BA_ "GenSigSendType" SG_ 1109 BMS_ProbeHighTemp_ERR 0;
BA_ "GenSigSendType" SG_ 1109 BMS_ProbeTempDiff_ERR 0;
BA_ "GenSigSendType" SG_ 1109 BMS_FuseStatus_ERR 0;
BA_ "GenSigSendType" SG_ 1109 BMS_ProbeLowTemp_ERR 0;
BA_ "GenSigSendType" SG_ 1504 BMS_Voltage_FrameNumber 0;
BA_ "GenSigSendType" SG_ 1504 BMS_Voltage_Value1 0;
BA_ "GenSigSendType" SG_ 1504 BMS_Voltage_Value2 0;
BA_ "GenSigSendType" SG_ 1504 BMS_Voltage_Value3 0;
BA_ "GenSigSendType" SG_ 1504 softwore_version 0;
BA_ "GenSigSendType" SG_ 1505 BMS_Temp_FrameNumber 0;
BA_ "GenSigSendType" SG_ 1505 BMS_Temp_Value1 0;
BA_ "GenSigSendType" SG_ 1505 BMS_Temp_Value2 0;
BA_ "GenSigSendType" SG_ 1505 BMS_Temp_Value3 0;
BA_ "GenSigSendType" SG_ 1505 BMS_Temp_Value4 0;
BA_ "GenSigSendType" SG_ 1505 BMS_Temp_Value5 0;
BA_ "GenSigSendType" SG_ 1505 BMS_Temp_Value6 0;
BA_ "GenSigSendType" SG_ 1505 BMS_Temp_Value7 0;
BA_ "GenSigSendType" SG_ 1506 BMS_Test_Runaway 0;
BA_ "GenSigSendType" SG_ 1506 BMS_Test_shunt_Temp 0;
BA_ "GenSigSendType" SG_ 1506 BMS_Test_V4_Volt 0;
BA_ "GenSigSendType" SG_ 1506 BMS_Test_L2ErrNum 0;
BA_ "GenSigSendType" SG_ 1507 Error_Information 0;
BA_ "GenSigSendType" SG_ 1507 HVIL_HS_Volt 0;
BA_ "GenSigSendType" SG_ 1507 HVIL_LS_Volt 0;
BA_ "GenSigSendType" SG_ 1507 FCHVIL_HS_Volt 0;
BA_ "GenSigSendType" SG_ 1507 FCHVIL_LS_Volt 0;
BA_ "GenSigSendType" SG_ 1507 HVIL_HS_Inv 0;
BA_ "GenSigSendType" SG_ 1507 HVIL_LS_Inv 0;
BA_ "GenSigSendType" SG_ 1507 FCHVIL_HS_Inv 0;
BA_ "GenSigSendType" SG_ 1507 FCHVIL_LS_Inv 0;
BA_ "GenSigSendType" SG_ 1507 HVIL_Fault 0;
BA_ "GenSigSendType" SG_ 1507 HallError 0;
BA_ "GenSigSendType" SG_ 1508 BMS_QMMo_Reserved_9 0;
BA_ "GenSigSendType" SG_ 1508 BMS_QMMo_Reserved_8 0;
BA_ "GenSigSendType" SG_ 1508 BMS_QMMo_Reserved_7 0;
BA_ "GenSigSendType" SG_ 1508 BMS_QMMo_Reserved_6 0;
BA_ "GenSigSendType" SG_ 1508 BMS_QMMo_Reserved_5 0;
BA_ "GenSigSendType" SG_ 1508 BMS_QMMo_Reserved_4 0;
BA_ "GenSigSendType" SG_ 1508 BMS_QMMo_Reserved_3 0;
BA_ "GenSigSendType" SG_ 1508 BMS_QMMo_Reserved_2 0;
BA_ "GenSigSendType" SG_ 1508 BMS_QMMo_Reserved_11 0;
BA_ "GenSigSendType" SG_ 1508 BMS_QMMo_Reserved_10 0;
BA_ "GenSigSendType" SG_ 1508 BMS_QMMo_Reserved_1 0;
BA_ "GenSigSendType" SG_ 1508 BMS_QMMo_Reserved_0 0;
BA_ "GenSigInvalidValue" SG_ 1508 Rolling_Counter_0x5E4 15;
BA_ "GenSigSendType" SG_ 1508 Rolling_Counter_0x5E4 0;
BA_ "GenSigStartValue" SG_ 1508 Checksum_0x5E4 255;
BA_ "GenSigSendType" SG_ 1508 Checksum_0x5E4 0;
BA_ "GenSigStartValue" SG_ 523 Checksum_0x20B 255;
BA_ "GenSigSendType" SG_ 523 Checksum_0x20B 0;
BA_ "GenSigInvalidValue" SG_ 523 Rolling_Counter_0x20B 15;
BA_ "GenSigSendType" SG_ 523 Rolling_Counter_0x20B 0;
BA_ "GenSigInvalidValue" SG_ 523 POD_DCDC_Max_Current_Out 1023;
BA_ "GenSigSendType" SG_ 523 POD_DCDC_Max_Current_Out 0;
BA_ "GenSigInvalidValue" SG_ 523 DCDC_Temp_mosfet 255;
BA_ "GenSigSendType" SG_ 523 DCDC_Temp_mosfet 0;
BA_ "GenSigInvalidValue" SG_ 523 DCDC_Voltage_Output 1023;
BA_ "GenSigSendType" SG_ 523 DCDC_Voltage_Output 0;
BA_ "GenSigInvalidValue" SG_ 523 DCDC_Current_Output 255;
BA_ "GenSigSendType" SG_ 523 DCDC_Current_Output 0;
BA_ "GenSigSendType" SG_ 523 DCDC_Output_STS 0;
BA_ "GenSigStartValue" SG_ 523 DCDC_Temp_heatsink 40;
BA_ "GenSigInvalidValue" SG_ 523 DCDC_Temp_heatsink 255;
BA_ "GenSigSendType" SG_ 523 DCDC_Temp_heatsink 0;
BA_ "GenSigStartValue" SG_ 646 Checksum_0x286 255;
BA_ "GenSigSendType" SG_ 646 Checksum_0x286 0;
BA_ "GenSigInvalidValue" SG_ 646 Rolling_Counter_0x286 15;
BA_ "GenSigSendType" SG_ 646 Rolling_Counter_0x286 0;
BA_ "GenSigInvalidValue" SG_ 646 DCFC_OUT_DC_V 65535;
BA_ "GenSigSendType" SG_ 646 DCFC_OUT_DC_V 0;
BA_ "GenSigInvalidValue" SG_ 646 DCFC_OUT_DC_I_Reserved 16383;
BA_ "GenSigSendType" SG_ 646 DCFC_OUT_DC_I_Reserved 0;
BA_ "GenSigInvalidValue" SG_ 646 DCFC_DCCharge_line_V 65535;
BA_ "GenSigSendType" SG_ 646 DCFC_DCCharge_line_V 0;
BA_ "GenSigSendType" SG_ 647 DCDC_evt_BUS_OFF 0;
BA_ "GenSigSendType" SG_ 647 DCDC_evt_MIA 0;
BA_ "GenSigSendType" SG_ 647 DCDC_evt_E2E 0;
BA_ "GenSigSendType" SG_ 647 DCDC_evt_Calibration_Flt 0;
BA_ "GenSigSendType" SG_ 647 DCDC_evt_flash_Failure 0;
BA_ "GenSigSendType" SG_ 647 DCDC_evt_FaultLatchCircuit 0;
BA_ "GenSigSendType" SG_ 647 DCDC_evt_HV_VoltSensFlt 0;
BA_ "GenSigSendType" SG_ 647 DCDC_evt_HV_OverVoltFlt 0;
BA_ "GenSigSendType" SG_ 647 DCDC_evt_HV_UnderVoltFlt 0;
BA_ "GenSigSendType" SG_ 647 DCDC_evt_LV_VoltSensFlt 0;
BA_ "GenSigSendType" SG_ 647 DCDC_evt_LVBatt_OverVoltFlt 0;
BA_ "GenSigSendType" SG_ 647 DCDC_evt_LVBatt_UnderVoltFlt 0;
BA_ "GenSigSendType" SG_ 647 DCDC_evt_LVBatt_SensorFlt 0;
BA_ "GenSigSendType" SG_ 647 DCDC_evt_LV_RedundancyFlt 0;
BA_ "GenSigSendType" SG_ 647 DCDC_evt_LV_CurrSensFlt 0;
BA_ "GenSigSendType" SG_ 647 DCDC_evt_LV_OverCurr 0;
BA_ "GenSigSendType" SG_ 647 DCDC_evt_ReverseCurrFlt 0;
BA_ "GenSigSendType" SG_ 647 DCDC_evt_Heater_TempSensorFlt 0;
BA_ "GenSigSendType" SG_ 647 DCDC_evt_Mosfet_TempSensorFlt 0;
BA_ "GenSigSendType" SG_ 647 DCDC_evt_Mosfet_OverTemp 0;
BA_ "GenSigSendType" SG_ 647 DCDC_evt_HeatSink_TempSensorFlt 0;
BA_ "GenSigSendType" SG_ 647 DCDC_evt_HeatSink_OverTemp 0;
BA_ "GenSigSendType" SG_ 647 DCDC_evt_Heater_OverTempFlt 0;
BA_ "GenSigSendType" SG_ 647 DCDC_evt_Heater_ShortIGBTFlt 0;
BA_ "GenSigSendType" SG_ 647 DCDC_evt_LV_ShortOutputFlt 0;
BA_ "GenSigSendType" SG_ 647 DCDC_evt_sw_BMS_CrashFlt 0;
BA_ "GenSigSendType" SG_ 647 DCDC_evt_BMS_HVILFlt 0;
BA_ "GenSigSendType" SG_ 648 DCFC_evt_BusbarSensFlt 0;
BA_ "GenSigSendType" SG_ 648 DCFC_evt_Contactor_Welded 0;
BA_ "GenSigSendType" SG_ 648 DCFC_evt_ContactorStuckOpen 0;
BA_ "GenSigSendType" SG_ 648 DCFC_evt_CP_UnderVoltFlt 0;
BA_ "GenSigSendType" SG_ 648 DCFC_evt_DataInvalidVCUFlt 0;
BA_ "GenSigSendType" SG_ 648 DCFC_evt_ChargePortSensFlt 0;
BA_ "GenSigSendType" SG_ 648 DCFC_evt_OverChargePortFlt 0;
BA_ "GenSigSendType" SG_ 648 DCFC_evt_OverBusbarTemp 0;
BA_ "GenSigSendType" SG_ 648 DCFC_evt_E2E_Flt 0;
BA_ "GenSigSendType" SG_ 648 DCFC_evt_MIA_Flt 0;
BA_ "GenSigStartValue" SG_ 1030 Checksum_0x406 255;
BA_ "GenSigSendType" SG_ 1030 Checksum_0x406 0;
BA_ "GenSigInvalidValue" SG_ 1030 Rolling_Counter_0x406 15;
BA_ "GenSigSendType" SG_ 1030 Rolling_Counter_0x406 0;
BA_ "GenSigSendType" SG_ 1030 DCDC_FaultLevel 0;
BA_ "GenSigSendType" SG_ 1030 DCFC_FaultLevel 0;
BA_ "GenSigStartValue" SG_ 522 Checksum_0x20A 255;
BA_ "GenSigSendType" SG_ 522 Checksum_0x20A 0;
BA_ "GenSigInvalidValue" SG_ 522 Rolling_Counter_0x20A 15;
BA_ "GenSigSendType" SG_ 522 Rolling_Counter_0x20A 0;
BA_ "GenSigInvalidValue" SG_ 522 DCFC_Voltage_Input 1023;
BA_ "GenSigSendType" SG_ 522 DCFC_Voltage_Input 0;
BA_ "GenSigSendType" SG_ 522 DCDC_PTC_Temp_Reserved 0;
BA_ "GenSigSendType" SG_ 522 DCFC_Neg_Temp_BusBar 0;
BA_ "GenSigSendType" SG_ 522 DCFC_STATE 0;
BA_ "GenSigInvalidValue" SG_ 522 DCFC_PTC_Status_Reserved 3;
BA_ "GenSigSendType" SG_ 522 DCFC_PTC_Status_Reserved 0;
BA_ "GenSigStartValue" SG_ 992 Checksum_0x3E0 255;
BA_ "GenSigSendType" SG_ 992 Checksum_0x3E0 0;
BA_ "GenSigInvalidValue" SG_ 992 Rolling_Counter_0x3E0 15;
BA_ "GenSigSendType" SG_ 992 Rolling_Counter_0x3E0 0;
BA_ "GenSigSendType" SG_ 992 EVCC_IPC_Ack_ChgSche_stt 0;
BA_ "GenSigStartValue" SG_ 992 EVCC_IPC_Ack_TargetSOC 100;
BA_ "GenSigSendType" SG_ 992 EVCC_IPC_Ack_TargetSOC 0;
BA_ "GenSigStartValue" SG_ 725 Checksum_0x2D5 255;
BA_ "GenSigSendType" SG_ 725 Checksum_0x2D5 0;
BA_ "GenSigInvalidValue" SG_ 725 Rolling_Counter_0x2D5 15;
BA_ "GenSigSendType" SG_ 725 Rolling_Counter_0x2D5 0;
BA_ "GenSigSendType" SG_ 725 VCU_DCDC_Output_REQ 0;
BA_ "GenSigInvalidValue" SG_ 725 VCU_DCDC_OutVoltage_REQ 65535;
BA_ "GenSigSendType" SG_ 725 VCU_DCDC_OutVoltage_REQ 0;
BA_ "GenSigInvalidValue" SG_ 725 VCU_DCDCAllowedPower 65535;
BA_ "GenSigSendType" SG_ 725 VCU_DCDCAllowedPower 0;
BA_ "GenSigStartValue" SG_ 673 Checksum_0x2A1 255;
BA_ "GenSigSendType" SG_ 673 Checksum_0x2A1 0;
BA_ "GenSigInvalidValue" SG_ 673 Rolling_Counter_0x2A1 15;
BA_ "GenSigSendType" SG_ 673 Rolling_Counter_0x2A1 0;
BA_ "GenSigSendType" SG_ 673 EVCC_ChargeGunSts 0;
BA_ "GenSigInvalidValue" SG_ 673 EVCC_VehicleFailureLevel 7;
BA_ "GenSigSendType" SG_ 673 EVCC_VehicleFailureLevel 0;
BA_ "GenSigSendType" SG_ 673 EVCC_ChargeMode 0;
BA_ "GenSigInvalidValue" SG_ 673 EVCC_CP_Value 255;
BA_ "GenSigSendType" SG_ 673 EVCC_CP_Value 0;
BA_ "GenSigInvalidValue" SG_ 673 EVCC_CP_Sts 15;
BA_ "GenSigSendType" SG_ 673 EVCC_CP_Sts 0;
BA_ "GenSigSendType" SG_ 673 EVCC_PP_Value 0;
BA_ "GenSigSendType" SG_ 673 EVCC_Lock_Sts 0;
BA_ "GenSigSendType" SG_ 673 EVCC_ErrCode 0;
BA_ "GenSigInvalidValue" SG_ 673 EVCC_DCFCPortsTempErr 1;
BA_ "GenSigSendType" SG_ 673 EVCC_DCFCPortsTempErr 0;
BA_ "GenSigStartValue" SG_ 682 Checksum_0x2AA 255;
BA_ "GenSigSendType" SG_ 682 Checksum_0x2AA 0;
BA_ "GenSigInvalidValue" SG_ 682 Rolling_Counter_0x2AA 15;
BA_ "GenSigSendType" SG_ 682 Rolling_Counter_0x2AA 0;
BA_ "GenSigInvalidValue" SG_ 682 EVCC_PLC_CommSts 3;
BA_ "GenSigSendType" SG_ 682 EVCC_PLC_CommSts 0;
BA_ "GenSigInvalidValue" SG_ 682 EVCC_DC_ChargeProcess 15;
BA_ "GenSigSendType" SG_ 682 EVCC_DC_ChargeProcess 0;
BA_ "GenSigSendType" SG_ 682 EVCC_BMS_InsulationMonReq 0;
BA_ "GenSigStartValue" SG_ 683 Checksum_0x2AB 255;
BA_ "GenSigSendType" SG_ 683 Checksum_0x2AB 0;
BA_ "GenSigInvalidValue" SG_ 683 Rolling_Counter_0x2AB 15;
BA_ "GenSigSendType" SG_ 683 Rolling_Counter_0x2AB 0;
BA_ "GenSigInvalidValue" SG_ 683 EVCC_OBC_PowerReq 127;
BA_ "GenSigSendType" SG_ 683 EVCC_OBC_PowerReq 0;
BA_ "GenSigInvalidValue" SG_ 683 EVCC_OBC_VoltageReq 8191;
BA_ "GenSigSendType" SG_ 683 EVCC_OBC_VoltageReq 0;
BA_ "GenSigInvalidValue" SG_ 683 EVCC_OBC_CurrentReq 1023;
BA_ "GenSigSendType" SG_ 683 EVCC_OBC_CurrentReq 0;
BA_ "GenSigSendType" SG_ 683 EVCC_OBC_Control 0;
BA_ "GenSigInvalidValue" SG_ 683 EVCC_AC_ChargeSts 7;
BA_ "GenSigSendType" SG_ 683 EVCC_AC_ChargeSts 0;
BA_ "GenSigStartValue" SG_ 537 Checksum_0x219 255;
BA_ "GenSigSendType" SG_ 537 Checksum_0x219 0;
BA_ "GenSigInvalidValue" SG_ 537 Rolling_Counter_0x219 15;
BA_ "GenSigSendType" SG_ 537 Rolling_Counter_0x219 0;
BA_ "GenSigSendType" SG_ 537 EVCC_ChargeAllow 0;
BA_ "GenSigStartValue" SG_ 537 EVCC_ChrSOCLitFb 1000;
BA_ "GenSigSendType" SG_ 537 EVCC_ChrSOCLitFb 0;
BA_ "GenSigStartValue" SG_ 757 Checksum_0x2F5 255;
BA_ "GenSigSendType" SG_ 757 Checksum_0x2F5 0;
BA_ "GenSigInvalidValue" SG_ 757 Rolling_Counter_0x2F5 15;
BA_ "GenSigSendType" SG_ 757 Rolling_Counter_0x2F5 0;
BA_ "GenSigSendType" SG_ 757 EVCC_Charge_Control 0;
BA_ "GenSigInvalidValue" SG_ 757 EVCC_DC_chargeSock_temp1 2047;
BA_ "GenSigSendType" SG_ 757 EVCC_DC_chargeSock_temp1 0;
BA_ "GenSigInvalidValue" SG_ 757 EVCC_DC_chargeSock_temp2 2047;
BA_ "GenSigSendType" SG_ 757 EVCC_DC_chargeSock_temp2 0;
BA_ "GenSigSendType" SG_ 757 EVCC_ChargeIndicatorCtrlSts_Red 0;
BA_ "GenSigSendType" SG_ 757 EVCC_ChargeIndicatorSts_Red 0;
BA_ "GenSigStartValue" SG_ 854 Checksum_0x356 255;
BA_ "GenSigSendType" SG_ 854 Checksum_0x356 0;
BA_ "GenSigInvalidValue" SG_ 854 Rolling_Counter_0x356 15;
BA_ "GenSigSendType" SG_ 854 Rolling_Counter_0x356 0;
BA_ "GenSigSendType" SG_ 854 OBC_WorkStatus 0;
BA_ "GenSigInvalidValue" SG_ 854 OBC_Sys_STS 3;
BA_ "GenSigSendType" SG_ 854 OBC_Sys_STS 0;
BA_ "GenSigSendType" SG_ 854 OBC_StartStatus 0;
BA_ "GenSigStartValue" SG_ 870 Checksum_0x366 255;
BA_ "GenSigSendType" SG_ 870 Checksum_0x366 0;
BA_ "GenSigInvalidValue" SG_ 870 Rolling_Counter_0x366 15;
BA_ "GenSigSendType" SG_ 870 Rolling_Counter_0x366 0;
BA_ "GenSigStartValue" SG_ 870 OBC_Charge_air_temp 40;
BA_ "GenSigInvalidValue" SG_ 870 OBC_Charge_air_temp 255;
BA_ "GenSigSendType" SG_ 870 OBC_Charge_air_temp 0;
BA_ "GenSigStartValue" SG_ 870 OBC_Temp 40;
BA_ "GenSigInvalidValue" SG_ 870 OBC_Temp 255;
BA_ "GenSigSendType" SG_ 870 OBC_Temp 0;
BA_ "GenSigStartValue" SG_ 629 Checksum_0x275 255;
BA_ "GenSigSendType" SG_ 629 Checksum_0x275 0;
BA_ "GenSigInvalidValue" SG_ 629 Rolling_Counter_0x275 15;
BA_ "GenSigSendType" SG_ 629 Rolling_Counter_0x275 0;
BA_ "GenSigInvalidValue" SG_ 629 OBC_OUT_DC_V 65535;
BA_ "GenSigSendType" SG_ 629 OBC_OUT_DC_V 0;
BA_ "GenSigInvalidValue" SG_ 629 OBC_OUT_DC_I 16383;
BA_ "GenSigSendType" SG_ 629 OBC_OUT_DC_I 0;
BA_ "GenSigInvalidValue" SG_ 629 OBC_DCCharge_line_V 65535;
BA_ "GenSigSendType" SG_ 629 OBC_DCCharge_line_V 0;
BA_ "GenSigStartValue" SG_ 630 Checksum_0x276 255;
BA_ "GenSigSendType" SG_ 630 Checksum_0x276 0;
BA_ "GenSigInvalidValue" SG_ 630 Rolling_Counter_0x276 15;
BA_ "GenSigSendType" SG_ 630 Rolling_Counter_0x276 0;
BA_ "GenSigInvalidValue" SG_ 630 OBC_Input_U 65535;
BA_ "GenSigSendType" SG_ 630 OBC_Input_U 0;
BA_ "GenSigInvalidValue" SG_ 630 OBC_IN_Main_V 65535;
BA_ "GenSigSendType" SG_ 630 OBC_IN_Main_V 0;
BA_ "GenSigInvalidValue" SG_ 630 OBC_IN_Main_I 1023;
BA_ "GenSigSendType" SG_ 630 OBC_IN_Main_I 0;
BA_ "GenSigStartValue" SG_ 662 Checksum_0x296 255;
BA_ "GenSigSendType" SG_ 662 Checksum_0x296 0;
BA_ "GenSigInvalidValue" SG_ 662 Rolling_Counter_0x296 15;
BA_ "GenSigSendType" SG_ 662 Rolling_Counter_0x296 0;
BA_ "GenSigInvalidValue" SG_ 662 OBC_MaxOutputChgU 8191;
BA_ "GenSigSendType" SG_ 662 OBC_MaxOutputChgU 0;
BA_ "GenSigInvalidValue" SG_ 662 OBC_MaxOutputChgI 511;
BA_ "GenSigSendType" SG_ 662 OBC_MaxOutputChgI 0;
BA_ "GenSigInvalidValue" SG_ 662 OBC_MaxOutputPwr 127;
BA_ "GenSigSendType" SG_ 662 OBC_MaxOutputPwr 0;
BA_ "GenSigSendType" SG_ 1142 OBC_FailGrade_ERR 0;
BA_ "GenSigSendType" SG_ 1142 OBC_ErrorFlag 0;
BA_ "GenSigSendType" SG_ 1142 OBC_Hardware_ERR 0;
BA_ "GenSigSendType" SG_ 1142 OBC_OTemp_ERR 0;
BA_ "GenSigSendType" SG_ 1142 OBC_OCofOut_ERR 0;
BA_ "GenSigSendType" SG_ 1142 OBC_CANcomoverT_ERR 0;
BA_ "GenSigSendType" SG_ 1142 OBC_UVofIn_ERR 0;
BA_ "GenSigSendType" SG_ 1142 OBC_OVofIn_ERR 0;
BA_ "GenSigSendType" SG_ 1142 OBC_OVofPFC_ERR 0;
BA_ "GenSigSendType" SG_ 1142 OBC_UVofPFC_ERR 0;
BA_ "GenSigSendType" SG_ 1142 OBC_UVofOut_ERR 0;
BA_ "GenSigSendType" SG_ 1142 OBC_OVofOut_ERR 0;
BA_ "GenSigSendType" SG_ 1598 OBC_DiagRespData0 0;
BA_ "GenSigSendType" SG_ 1598 OBC_DiagRespData1 0;
BA_ "GenSigSendType" SG_ 1598 OBC_DiagRespData2 0;
BA_ "GenSigSendType" SG_ 1598 OBC_DiagRespData3 0;
BA_ "GenSigSendType" SG_ 1598 OBC_DiagRespData4 0;
BA_ "GenSigSendType" SG_ 1598 OBC_DiagRespData5 0;
BA_ "GenSigSendType" SG_ 1598 OBC_DiagRespData6 0;
BA_ "GenSigSendType" SG_ 1598 OBC_DiagRespData7 0;
BA_ "GenSigSendType" SG_ 1726 OBC_DiagReqData0 0;
BA_ "GenSigSendType" SG_ 1726 OBC_DiagReqData1 0;
BA_ "GenSigSendType" SG_ 1726 OBC_DiagReqData2 0;
BA_ "GenSigSendType" SG_ 1726 OBC_DiagReqData3 0;
BA_ "GenSigSendType" SG_ 1726 OBC_DiagReqData4 0;
BA_ "GenSigSendType" SG_ 1726 OBC_DiagReqData5 0;
BA_ "GenSigSendType" SG_ 1726 OBC_DiagReqData6 0;
BA_ "GenSigSendType" SG_ 1726 OBC_DiagReqData7 0;
BA_ "GenSigSendType" SG_ 1683 BMS_DiagReqData0 0;
BA_ "GenSigSendType" SG_ 1683 BMS_DiagReqData1 0;
BA_ "GenSigSendType" SG_ 1683 BMS_DiagReqData2 0;
BA_ "GenSigSendType" SG_ 1683 BMS_DiagReqData3 0;
BA_ "GenSigSendType" SG_ 1683 BMS_DiagReqData4 0;
BA_ "GenSigSendType" SG_ 1683 BMS_DiagReqData5 0;
BA_ "GenSigSendType" SG_ 1683 BMS_DiagReqData6 0;
BA_ "GenSigSendType" SG_ 1683 BMS_DiagReqData7 0;
BA_ "GenSigSendType" SG_ 1555 BMS_DiagRespData0 0;
BA_ "GenSigSendType" SG_ 1555 BMS_DiagRespData1 0;
BA_ "GenSigSendType" SG_ 1555 BMS_DiagRespData2 0;
BA_ "GenSigSendType" SG_ 1555 BMS_DiagRespData3 0;
BA_ "GenSigSendType" SG_ 1555 BMS_DiagRespData4 0;
BA_ "GenSigSendType" SG_ 1555 BMS_DiagRespData5 0;
BA_ "GenSigSendType" SG_ 1555 BMS_DiagRespData6 0;
BA_ "GenSigSendType" SG_ 1555 BMS_DiagRespData7 0;
BA_ "GenSigSendType" SG_ 1704 EPS_DiagReqData0 0;
BA_ "GenSigSendType" SG_ 1704 EPS_DiagReqData1 0;
BA_ "GenSigSendType" SG_ 1704 EPS_DiagReqData2 0;
BA_ "GenSigSendType" SG_ 1704 EPS_DiagReqData3 0;
BA_ "GenSigSendType" SG_ 1704 EPS_DiagReqData4 0;
BA_ "GenSigSendType" SG_ 1704 EPS_DiagReqData5 0;
BA_ "GenSigSendType" SG_ 1704 EPS_DiagReqData6 0;
BA_ "GenSigSendType" SG_ 1704 EPS_DiagReqData7 0;
BA_ "GenSigSendType" SG_ 1576 EPS_DiagRespData0 0;
BA_ "GenSigSendType" SG_ 1576 EPS_DiagRespData1 0;
BA_ "GenSigSendType" SG_ 1576 EPS_DiagRespData2 0;
BA_ "GenSigSendType" SG_ 1576 EPS_DiagRespData3 0;
BA_ "GenSigSendType" SG_ 1576 EPS_DiagRespData4 0;
BA_ "GenSigSendType" SG_ 1576 EPS_DiagRespData5 0;
BA_ "GenSigSendType" SG_ 1576 EPS_DiagRespData6 0;
BA_ "GenSigSendType" SG_ 1576 EPS_DiagRespData7 0;
BA_ "GenSigSendType" SG_ 1691 EDS_DiagReqData0 0;
BA_ "GenSigSendType" SG_ 1691 EDS_DiagReqData1 0;
BA_ "GenSigSendType" SG_ 1691 EDS_DiagReqData2 0;
BA_ "GenSigSendType" SG_ 1691 EDS_DiagReqData3 0;
BA_ "GenSigSendType" SG_ 1691 EDS_DiagReqData4 0;
BA_ "GenSigSendType" SG_ 1691 EDS_DiagReqData5 0;
BA_ "GenSigSendType" SG_ 1691 EDS_DiagReqData6 0;
BA_ "GenSigSendType" SG_ 1691 EDS_DiagReqData7 0;
BA_ "GenSigSendType" SG_ 1563 EDS_DiagRespData0 0;
BA_ "GenSigSendType" SG_ 1563 EDS_DiagRespData1 0;
BA_ "GenSigSendType" SG_ 1563 EDS_DiagRespData2 0;
BA_ "GenSigSendType" SG_ 1563 EDS_DiagRespData3 0;
BA_ "GenSigSendType" SG_ 1563 EDS_DiagRespData4 0;
BA_ "GenSigSendType" SG_ 1563 EDS_DiagRespData5 0;
BA_ "GenSigSendType" SG_ 1563 EDS_DiagRespData6 0;
BA_ "GenSigSendType" SG_ 1563 EDS_DiagRespData7 0;
BA_ "GenSigSendType" SG_ 1725 DCDC_DiagReqData0 0;
BA_ "GenSigSendType" SG_ 1725 DCDC_DiagReqData1 0;
BA_ "GenSigSendType" SG_ 1725 DCDC_DiagReqData2 0;
BA_ "GenSigSendType" SG_ 1725 DCDC_DiagReqData3 0;
BA_ "GenSigSendType" SG_ 1725 DCDC_DiagReqData4 0;
BA_ "GenSigSendType" SG_ 1725 DCDC_DiagReqData5 0;
BA_ "GenSigSendType" SG_ 1725 DCDC_DiagReqData6 0;
BA_ "GenSigSendType" SG_ 1725 DCDC_DiagReqData7 0;
BA_ "GenSigSendType" SG_ 1597 DCDC_DiagRespData0 0;
BA_ "GenSigSendType" SG_ 1597 DCDC_DiagRespData1 0;
BA_ "GenSigSendType" SG_ 1597 DCDC_DiagRespData2 0;
BA_ "GenSigSendType" SG_ 1597 DCDC_DiagRespData3 0;
BA_ "GenSigSendType" SG_ 1597 DCDC_DiagRespData4 0;
BA_ "GenSigSendType" SG_ 1597 DCDC_DiagRespData5 0;
BA_ "GenSigSendType" SG_ 1597 DCDC_DiagRespData6 0;
BA_ "GenSigSendType" SG_ 1597 DCDC_DiagRespData7 0;
BA_ "GenSigSendType" SG_ 1695 EVCC_DiagReqData0 0;
BA_ "GenSigSendType" SG_ 1695 EVCC_DiagReqData1 0;
BA_ "GenSigSendType" SG_ 1695 EVCC_DiagReqData2 0;
BA_ "GenSigSendType" SG_ 1695 EVCC_DiagReqData3 0;
BA_ "GenSigSendType" SG_ 1695 EVCC_DiagReqData4 0;
BA_ "GenSigSendType" SG_ 1695 EVCC_DiagReqData5 0;
BA_ "GenSigSendType" SG_ 1695 EVCC_DiagReqData6 0;
BA_ "GenSigSendType" SG_ 1695 EVCC_DiagReqData7 0;
BA_ "GenSigSendType" SG_ 1567 EVCC_DiagRespData0 0;
BA_ "GenSigSendType" SG_ 1567 EVCC_DiagRespData1 0;
BA_ "GenSigSendType" SG_ 1567 EVCC_DiagRespData2 0;
BA_ "GenSigSendType" SG_ 1567 EVCC_DiagRespData3 0;
BA_ "GenSigSendType" SG_ 1567 EVCC_DiagRespData4 0;
BA_ "GenSigSendType" SG_ 1567 EVCC_DiagRespData5 0;
BA_ "GenSigSendType" SG_ 1567 EVCC_DiagRespData6 0;
BA_ "GenSigSendType" SG_ 1567 EVCC_DiagRespData7 0;
BA_ "GenSigSendType" SG_ 1791 DiagFunctionalAddressingData0 0;
BA_ "GenSigSendType" SG_ 1791 DiagFunctionalAddressingData1 0;
BA_ "GenSigSendType" SG_ 1791 DiagFunctionalAddressingData2 0;
BA_ "GenSigSendType" SG_ 1791 DiagFunctionalAddressingData3 0;
BA_ "GenSigSendType" SG_ 1791 DiagFunctionalAddressingData4 0;
BA_ "GenSigSendType" SG_ 1791 DiagFunctionalAddressingData5 0;
BA_ "GenSigSendType" SG_ 1791 DiagFunctionalAddressingData6 0;
BA_ "GenSigSendType" SG_ 1791 DiagFunctionalAddressingData7 0;
BA_ "GenSigSendType" SG_ 1324 VCU_sourceID 0;
BA_ "GenSigSendType" SG_ 1324 VCU_CBV 0;
BA_ "GenSigSendType" SG_ 1324 VCU_Data0 0;
BA_ "GenSigSendType" SG_ 1324 VCU_Data1 0;
BA_ "GenSigSendType" SG_ 1324 VCU_Data2 0;
BA_ "GenSigSendType" SG_ 1324 VCU_Data3 0;
BA_ "GenSigSendType" SG_ 1324 VCU_Data4 0;
BA_ "GenSigSendType" SG_ 1324 VCU_Data5 0;
BA_ "GenSigSendType" SG_ 1299 BMS_sourceID 0;
BA_ "GenSigSendType" SG_ 1299 BMS_CBV 0;
BA_ "GenSigSendType" SG_ 1299 BMS_Data0 0;
BA_ "GenSigSendType" SG_ 1299 BMS_Data1 0;
BA_ "GenSigSendType" SG_ 1299 BMS_Data2 0;
BA_ "GenSigSendType" SG_ 1299 BMS_Data3 0;
BA_ "GenSigSendType" SG_ 1299 BMS_Data4 0;
BA_ "GenSigSendType" SG_ 1299 BMS_Data5 0;
BA_ "GenSigSendType" SG_ 1341 PDU_DCDC_sourceID 0;
BA_ "GenSigSendType" SG_ 1341 PDU_DCDC_CBV 0;
BA_ "GenSigSendType" SG_ 1341 PDU_DCDC_Data0 0;
BA_ "GenSigSendType" SG_ 1341 PDU_DCDC_Data1 0;
BA_ "GenSigSendType" SG_ 1341 PDU_DCDC_Data2 0;
BA_ "GenSigSendType" SG_ 1341 PDU_DCDC_Data3 0;
BA_ "GenSigSendType" SG_ 1341 PDU_DCDC_Data4 0;
BA_ "GenSigSendType" SG_ 1341 PDU_DCDC_Data5 0;
BA_ "GenSigSendType" SG_ 1311 EVCC_sourceID 0;
BA_ "GenSigSendType" SG_ 1311 EVCC_CBV 0;
BA_ "GenSigSendType" SG_ 1311 EVCC_Data0 0;
BA_ "GenSigSendType" SG_ 1311 EVCC_Data1 0;
BA_ "GenSigSendType" SG_ 1311 EVCC_Data2 0;
BA_ "GenSigSendType" SG_ 1311 EVCC_Data3 0;
BA_ "GenSigSendType" SG_ 1311 EVCC_Data4 0;
BA_ "GenSigSendType" SG_ 1311 EVCC_Data5 0;
BA_ "GenSigSendType" SG_ 1342 OBC_sourceID 0;
BA_ "GenSigSendType" SG_ 1342 OBC_CBV 0;
BA_ "GenSigSendType" SG_ 1342 OBC_Data0 0;
BA_ "GenSigSendType" SG_ 1342 OBC_Data1 0;
BA_ "GenSigSendType" SG_ 1342 OBC_Data2 0;
BA_ "GenSigSendType" SG_ 1342 OBC_Data3 0;
BA_ "GenSigSendType" SG_ 1342 OBC_Data4 0;
BA_ "GenSigSendType" SG_ 1342 OBC_Data5 0;
VAL_ 374 Rolling_Counter_0x176 15 "Invalid" ;
VAL_ 374 BMS_HVLinkVol_MEAS 65535 "Invalid" ;
VAL_ 374 BMS_HVPackVol_MEAS 65535 "Invalid" ;
VAL_ 375 Rolling_Counter_0x177 15 "Invalid" ;
VAL_ 375 BMS_HVBusVol_MEAS 65535 "Invalid" ;
VAL_ 375 BMS_HVFuseVol_MEAS 65535 "Invalid" ;
VAL_ 372 Rolling_Counter_0x174 15 "Invalid" ;
VAL_ 372 BMS_PackCur_MEAS 65535 "Invalid" ;
VAL_ 372 BMS_AllowDischgCurr 65535 "Invalid" ;
VAL_ 372 BMS_AllowDischgCurrPeak 65535 "Invalid" ;
VAL_ 532 Rolling_Counter_0x214 15 "Invalid" ;
VAL_ 532 BMS_Display_SOC 1023 "Invalid" ;
VAL_ 533 Rolling_Counter_0x215 15 "Invalid" ;
VAL_ 533 BMS_SOE 255 "Invalid" ;
VAL_ 533 BMS_HWCrash_Sts 1 "Crash " 0 "No Crash" ;
VAL_ 533 BMS_HVIL_STS 2 "out of range" 1 "Open" 0 "Closed" ;
VAL_ 533 BMS_IGN_Sts 1 "ON " 0 "OFF" ;
VAL_ 533 BMS_Sys_STS 8 "Invalid" 7 "Failure, unable to operate" 6 "BCU Sleep mode" 5 "Successful Power Down" 4 "Power Down process" 3 "Successful Power Down of HV" 2 "Successful High Voltage Power Up" 1 "Self-check passes, can be high-voltage" 0 "Initialization of power on, self-checking" ;
VAL_ 533 BMS_HVOnOff_STS 3 "Fail to HV on " 2 "HV On " 1 "Precharge " 0 "HV Off" ;
VAL_ 533 BMS_Balance_STS 1 "active " 0 "Inactive" ;
VAL_ 533 BMS_BatBalance_ERR 1 "normal " 0 "Error" ;
VAL_ 533 BMS_ISU_Status 3 "Level3(<100 Ohms/V)" 2 "Level2(<200 Ohms/V)" 1 "Level1 <500 Ohms/V ~ >200 Ohms/V" 0 "Normal (> 500 Ohms/V)" ;
VAL_ 533 BMS_ERR_LEV 7 "Battery locked -Reserved" 6 "Fault, needs Shutdown and Wakeup" 5 "Emergency off condition" 4 "Delayed power down with FTTI" 3 "Power down without FTTI" 2 "Limp Home" 1 " Warning (any warning in system)" 0 "No error" ;
VAL_ 533 BMS_Vehicle_ERR_LEV 0 "Normal" 1 "Slight Fault" 2 "Minor fault" 3 "General fault" 4 "Serious Fault" 5 "Fatal fault" ;
VAL_ 533 BMS_HV_Sts 4 "AC Charging" 3 "DC Charging" 2 "HV ON" 1 "Precharge" 0 "HV Off" ;
VAL_ 549 Rolling_Counter_0x225 15 "Invalid" ;
VAL_ 549 CDM_bAcvCanComStblMon 1 "Error" 0 "No error" ;
VAL_ 549 FRMo_bErrHvbatStReqExtMon 1 "Error" 0 "No error" ;
VAL_ 549 FRMo_bErrChrgnAllwdExtMon 1 "Error" 0 "No error" ;
VAL_ 549 FRMo_bErrVehCrashStExtMon 1 "Error" 0 "No error" ;
VAL_ 549 CDM_bErrComctnLossCanMon 1 "Error" 0 "No error" ;
VAL_ 549 CTCMon_bErrCtctrSopcMon 1 "Error" 0 "No error" ;
VAL_ 549 CTCMon_bInvldCtctrHisdIFbMon 1 "Error" 0 "No error" ;
VAL_ 549 CTCMon_bInvldCtctrLosdUFbMon 1 "Error" 0 "No error" ;
VAL_ 549 CTM_bErrCellTDifMaxMon 1 "Error" 0 "No error" ;
VAL_ 549 CTM_bErrCellTMaxMon 1 "Error" 0 "No error" ;
VAL_ 549 CTM_bErrCellTMinMon 1 "Error" 0 "No error" ;
VAL_ 549 CTM_bErrThrwyPredMon 1 "Error" 0 "No error" ;
VAL_ 549 CUM_bErrCellUDifMaxMon 1 "Error" 0 "No error" ;
VAL_ 549 CUM_bErrCellUMaxMon 1 "Error" 0 "No error" ;
VAL_ 549 CUM_bErrCellUMinMon 1 "Error" 0 "No error" ;
VAL_ 549 CUM_bErrCellUProtnMaxNvMon 1 "Error" 0 "No error" ;
VAL_ 549 CUM_bErrCellUProtnMinNvMon 1 "Error" 0 "No error" ;
VAL_ 549 CUM_bErrPackUImplyMon 1 "Error" 0 "No error" ;
VAL_ 549 EHPMon_bRdyHvilMon 1 "Error" 0 "No error" ;
VAL_ 549 EHPMon_bErrWlddNegNvMon 1 "Error" 0 "No error" ;
VAL_ 549 EHPMon_bErrWlddPosNvMon 1 "Error" 0 "No error" ;
VAL_ 549 EHPMon_bErrWlddPrechNvMon 1 "Error" 0 "No error" ;
VAL_ 549 EHPMon_bErrHvilMon 1 "Error" 0 "No error" ;
VAL_ 549 EHPMon_bErrHvilShoMon 1 "Error" 0 "No error" ;
VAL_ 549 EHPMon_bErrPackIslnRNvMon 1 "Error" 0 "No error" ;
VAL_ 549 EHPMon_bErrVehCrashNvMon 1 "Error" 0 "No error" ;
VAL_ 549 EHPMon_bErrVehIslnRNvMon 1 "Error" 0 "No error" ;
VAL_ 549 FRMo_bErrMemStorgNvMon 1 "Error" 0 "No error" ;
VAL_ 549 L1IM_bErrClmp30MaxMonInp 1 "Error" 0 "No error" ;
VAL_ 549 L1IM_bErrClmp30MinMonInp 1 "Error" 0 "No error" ;
VAL_ 549 L1IM_bErrCtctrDtrtMonInp 1 "Error" 0 "No error" ;
VAL_ 549 L1IM_bErrUActImplyMonInp 1 "Error" 0 "No error" ;
VAL_ 549 MCCM_bAcvMdulCtlrStsMon 1 "Error" 0 "No error" ;
VAL_ 549 MCCM_bErrLntecSngFltMon 1 "Error" 0 "No error" ;
VAL_ 549 MCCM_bErrLntecLtntFltMon 1 "Error" 0 "No error" ;
VAL_ 549 MCCM_bErrMdulCellSnsrCfgMon 1 "Error" 0 "No error" ;
VAL_ 549 MCCM_bErrMdulCtlrComMon 1 "Error" 0 "No error" ;
VAL_ 549 MCCM_bErrSnsrTEltlMon 1 "Error" 0 "No error" ;
VAL_ 549 MCCM_bWarnSnsrTEltlMon 1 "Error" 0 "No error" ;
VAL_ 549 PCM_bRdySnsrIMon 1 "Error" 0 "No error" ;
VAL_ 549 PCM_bErrPackEFlowMaxLimMon 1 "Error" 0 "No error" ;
VAL_ 549 PCM_bErrPackIChDchaMaxLimMon 1 "Error" 0 "No error" ;
VAL_ 549 PCM_bErrSnsrIImplyMon 1 "Error" 0 "No error" ;
VAL_ 549 FRMo_bErrSnsrI1ExtMon 1 "Error" 0 "No error" ;
VAL_ 549 PCM_bInvldSnsrI1Mon 1 "Error" 0 "No error" ;
VAL_ 549 PCM_bInvldSnsrI2Mon 1 "Error" 0 "No error" ;
VAL_ 549 FRMo_bErrSopcLvl3Mon 1 "Error" 0 "No error" ;
VAL_ 549 BMS_FRMo_Reserved_1 1 "Error" 0 "No error" ;
VAL_ 549 BMS_FRMo_Reserved_2 1 "Error" 0 "No error" ;
VAL_ 549 BMS_FRMo_Reserved_3 1 "Error" 0 "No error" ;
VAL_ 549 BMS_FRMo_Reserved_4 1 "Error" 0 "No error" ;
VAL_ 549 BMS_FRMo_Reserved_5 1 "Error" 0 "No error" ;
VAL_ 293 Rolling_Counter_0x125 15 "Invalid" ;
VAL_ 885 Rolling_Counter_0x375 15 "Invalid" ;
VAL_ 885 BMS_MainPosRelay_ERR 1 "normal " 0 "Error" ;
VAL_ 885 BMS_MainPosRelay_STS 4 "stuck open" 3 "stuck closed" 2 "closed" 1 "open" 0 "reserved" ;
VAL_ 885 BMS_PreChgRelay_ERR 1 "normal " 0 "error" ;
VAL_ 885 BMS_PreChgRelay_STS 4 "stuck open" 3 "stuck closed" 2 "closed" 1 "open" 0 "reserved" ;
VAL_ 885 BMS_TotalNegRelay_STS 4 "stuck open" 3 "stuck closed" 2 "closed" 1 "open" 0 "reserved" ;
VAL_ 885 BMS_TotalNegRelay_ERR 1 "normal " 0 "Error" ;
VAL_ 517 Rolling_Counter_0x205 15 "Invalid" ;
VAL_ 517 BMS_MaxCellVol 8191 "Invalid" ;
VAL_ 517 BMS_CellNumMaxCellVol 0 "Invalid" ;
VAL_ 517 BMS_MinCellVol 8191 "Invalid" ;
VAL_ 517 BMS_CellNumMinCellVol 0 "Invalid" ;
VAL_ 581 Rolling_Counter_0x245 15 "Invalid" ;
VAL_ 581 BMS_PackTemp 255 "Invalid" ;
VAL_ 581 BMS_MaxMinDiffCellTemp 255 "Diff Temp" ;
VAL_ 581 BMS_MaxCellTemp 255 "Invalid" ;
VAL_ 581 BMS_MinCellTemp 255 "Invalid" ;
VAL_ 581 BMS_ProbeNumMaxCellTemp 63 "Invalid" 62 "Error" 0 "Invalid" ;
VAL_ 581 BMS_ProbeNumMinCellTemp 63 "Invalid" 62 "Error" 0 "Invalid" ;
VAL_ 773 Rolling_Counter_0x305 15 "Invalid" ;
VAL_ 773 BMS_VCU_Insulation_Mon_Sts 1 "OFF" 0 "ON" ;
VAL_ 1171 BMS_Warning_Flag_Reserved_08 1 "Warning" 0 "No warning" ;
VAL_ 1171 BMS_Warning_Flag_Reserved_07 1 "Warning" 0 "No warning" ;
VAL_ 1171 BMS_Warning_Flag_Reserved_11 1 "Warning" 0 "No warning" ;
VAL_ 1171 BMS_Warning_Flag_Reserved_10 1 "Warning" 0 "No warning" ;
VAL_ 1171 BMS_Warning_Flag_Reserved_09 1 "Warning" 0 "No warning" ;
VAL_ 1171 BMS_Warning_Flag_Reserved_13 1 "Warning" 0 "No warning" ;
VAL_ 1171 BMS_Warning_Flag_Reserved_12 1 "Warning" 0 "No warning" ;
VAL_ 1171 BMS_Warning_Flag_Reserved_06 1 "Warning" 0 "No warning" ;
VAL_ 1171 BMS_Warning_Flag_Reserved_05 1 "Warning" 0 "No warning" ;
VAL_ 1171 BMS_Warning_Flag_Reserved_04 1 "Warning" 0 "No warning" ;
VAL_ 1171 BMS_MalfunctionSts 1 "Malfunction indicator lamp ON" 0 "Malfunction indicator lamp OFF" ;
VAL_ 1171 BMS_LowBattery 2 "Extremely low level" 1 "Low level" 0 "No warning" ;
VAL_ 1171 BMS_BatteryReplacement 1 "Warning" 0 "No warning" ;
VAL_ 1171 BMS_PackTempSts 2 "Under Temperature Warning" 1 "Over Temperature Warning" 0 "No warning" ;
VAL_ 1171 BMS_ThermalRunaway 1 "Warning" 0 "No warning" ;
VAL_ 1171 Rolling_Counter_0x493 15 "Invalid" ;
VAL_ 1109 Rolling_Counter_0x455 15 "Invalid" ;
VAL_ 1109 BMS_PackInsu_ERR 2 "Lv2-Short to vbat and open line" 1 "Lv1 - Short to ground" 0 "Lv0-No Err" ;
VAL_ 1109 BMS_CellVoltDiff_ERR 3 "Level3 Reserve" 2 "Level2 Serious alarm value" 1 "Level1 General alarm value" 0 "Level0 Normal" ;
VAL_ 1109 BMS_PackOverCurr_ERR 2 "Serious Alarm value" 1 "General Alarm Value" 0 "Normal" ;
VAL_ 1109 BMS_HVIL_Err 3 "Level3" 2 "Level2" 1 "Level1" 0 "Normal" ;
VAL_ 1109 BMS_CellHighVol_ERR 3 "Level3 Reserve" 2 "Level2 Serious alarm value" 1 "Level1 General alarm value" 0 "Level0 Normal" ;
VAL_ 1109 BMS_CellLowVol_ERR 3 "Level3 Reserve" 2 "Level2 Serious alarm value" 1 "Level1 General alarm value" 0 "Level0 Normal" ;
VAL_ 1109 BMS_PackLowVol_ERR 3 "Level3 Reserve" 2 "Level2 Serious alarm value" 1 "Level1 General alarm value" 0 "Level0 Normal" ;
VAL_ 1109 BMS_PackHighVol_ERR 3 "Level3 Reserve" 2 "Level2 Serious alarm value" 1 "Level1 General alarm value" 0 "Level0 Normal" ;
VAL_ 1109 BMS_ProbeHighTemp_ERR 3 "Level3 Reserve" 2 "Level2 Serious alarm value" 1 "Level1 General alarm value" 0 "Level0 Normal" ;
VAL_ 1109 BMS_ProbeTempDiff_ERR 3 "Level3 Reserve" 2 "Level2 Serious alarm value" 1 "Level1 General alarm value" 0 "Level0 Normal" ;
VAL_ 1109 BMS_FuseStatus_ERR 1 "Fuse blow" 0 "Normal" ;
VAL_ 1109 BMS_ProbeLowTemp_ERR 3 "Level3 Reserve" 2 "Level2 Serious alarm value" 1 "Level1 General alarm value" 0 "Level0 Normal" ;
VAL_ 1504 softwore_version 1 "valid" 0 "Invalid" ;
VAL_ 1508 BMS_QMMo_Reserved_9 1 "Error" 0 "No Error" ;
VAL_ 1508 BMS_QMMo_Reserved_8 1 "Error" 0 "No Error" ;
VAL_ 1508 BMS_QMMo_Reserved_7 1 "Error" 0 "No Error" ;
VAL_ 1508 BMS_QMMo_Reserved_6 1 "Error" 0 "No Error" ;
VAL_ 1508 BMS_QMMo_Reserved_5 1 "Error" 0 "No Error" ;
VAL_ 1508 BMS_QMMo_Reserved_4 1 "Error" 0 "No Error" ;
VAL_ 1508 BMS_QMMo_Reserved_3 1 "Error" 0 "No Error" ;
VAL_ 1508 BMS_QMMo_Reserved_2 1 "Error" 0 "No Error" ;
VAL_ 1508 BMS_QMMo_Reserved_11 1 "Error" 0 "No Error" ;
VAL_ 1508 BMS_QMMo_Reserved_10 1 "Error" 0 "No Error" ;
VAL_ 1508 BMS_QMMo_Reserved_1 1 "Error" 0 "No Error" ;
VAL_ 1508 BMS_QMMo_Reserved_0 1 "Error" 0 "No Error" ;
VAL_ 1508 Rolling_Counter_0x5E4 15 "Invalid" ;
VAL_ 523 Rolling_Counter_0x20B 15 "Invalid" ;
VAL_ 523 POD_DCDC_Max_Current_Out 1023 "Invalid" ;
VAL_ 523 DCDC_Temp_mosfet 255 "Invalid" ;
VAL_ 523 DCDC_Voltage_Output 1023 "Invalid" ;
VAL_ 523 DCDC_Current_Output 255 "Invalid" ;
VAL_ 523 DCDC_Output_STS 0 "DCDC_OFF" 1 "DCDC_STANDBY" 2 "DCDC_ON" 3 "DCDC_RESERVED" 4 "DCDC_DEGRAEDED" 5 "DCDC_FAULT_SHUTDOWN" 6 "DCDC_EMEGENCY_SHUTDOWN" 7 "DCDC_SNA" ;
VAL_ 523 DCDC_Temp_heatsink 255 "Invalid" ;
VAL_ 646 Rolling_Counter_0x286 15 "Invalid" ;
VAL_ 646 DCFC_OUT_DC_V 65535 "Invalid" ;
VAL_ 646 DCFC_OUT_DC_I_Reserved 16383 "Invalid" ;
VAL_ 646 DCFC_DCCharge_line_V 65535 "Invalid" ;
VAL_ 647 DCDC_evt_BUS_OFF 1 "Error" 0 "Normal" ;
VAL_ 647 DCDC_evt_MIA 1 "Error" 0 "Normal" ;
VAL_ 647 DCDC_evt_E2E 1 "Error" 0 "Normal" ;
VAL_ 647 DCDC_evt_Calibration_Flt 1 "Error" 0 "Normal" ;
VAL_ 647 DCDC_evt_flash_Failure 1 "Error" 0 "Normal" ;
VAL_ 647 DCDC_evt_FaultLatchCircuit 1 "Error" 0 "Normal" ;
VAL_ 647 DCDC_evt_HV_VoltSensFlt 1 "Error" 0 "Normal" ;
VAL_ 647 DCDC_evt_HV_OverVoltFlt 1 "Error" 0 "Normal" ;
VAL_ 647 DCDC_evt_HV_UnderVoltFlt 1 "Error" 0 "Normal" ;
VAL_ 647 DCDC_evt_LV_VoltSensFlt 1 "Error" 0 "Normal" ;
VAL_ 647 DCDC_evt_LVBatt_OverVoltFlt 1 "Error" 0 "Normal" ;
VAL_ 647 DCDC_evt_LVBatt_UnderVoltFlt 1 "Error" 0 "Normal" ;
VAL_ 647 DCDC_evt_LVBatt_SensorFlt 1 "Error" 0 "Normal" ;
VAL_ 647 DCDC_evt_LV_RedundancyFlt 1 "Error" 0 "Normal" ;
VAL_ 647 DCDC_evt_LV_CurrSensFlt 1 "Error" 0 "Normal" ;
VAL_ 647 DCDC_evt_LV_OverCurr 1 "Error" 0 "Normal" ;
VAL_ 647 DCDC_evt_ReverseCurrFlt 1 "Error" 0 "Normal" ;
VAL_ 647 DCDC_evt_Heater_TempSensorFlt 1 "Error" 0 "Normal" ;
VAL_ 647 DCDC_evt_Mosfet_TempSensorFlt 1 "Error" 0 "Normal" ;
VAL_ 647 DCDC_evt_Mosfet_OverTemp 1 "Error" 0 "Normal" ;
VAL_ 647 DCDC_evt_HeatSink_TempSensorFlt 1 "Error" 0 "Normal" ;
VAL_ 647 DCDC_evt_HeatSink_OverTemp 1 "Error" 0 "Normal" ;
VAL_ 647 DCDC_evt_Heater_OverTempFlt 1 "Error" 0 "Normal" ;
VAL_ 647 DCDC_evt_Heater_ShortIGBTFlt 1 "Error" 0 "Normal" ;
VAL_ 647 DCDC_evt_LV_ShortOutputFlt 1 "Error" 0 "Normal" ;
VAL_ 647 DCDC_evt_sw_BMS_CrashFlt 1 "Error" 0 "Normal" ;
VAL_ 647 DCDC_evt_BMS_HVILFlt 1 "Error" 0 "Normal" ;
VAL_ 648 DCFC_evt_BusbarSensFlt 1 "Error" 0 "Normal" ;
VAL_ 648 DCFC_evt_Contactor_Welded 1 "Error" 0 "Normal" ;
VAL_ 648 DCFC_evt_ContactorStuckOpen 1 "Error" 0 "Normal" ;
VAL_ 648 DCFC_evt_CP_UnderVoltFlt 1 "Error" 0 "Normal" ;
VAL_ 648 DCFC_evt_DataInvalidVCUFlt 1 "Error" 0 "Normal" ;
VAL_ 648 DCFC_evt_ChargePortSensFlt 1 "Error" 0 "Normal" ;
VAL_ 648 DCFC_evt_OverChargePortFlt 1 "Error" 0 "Normal" ;
VAL_ 648 DCFC_evt_OverBusbarTemp 1 "Error" 0 "Normal" ;
VAL_ 648 DCFC_evt_E2E_Flt 1 "Error" 0 "Normal" ;
VAL_ 648 DCFC_evt_MIA_Flt 1 "Error" 0 "Normal" ;
VAL_ 1030 Rolling_Counter_0x406 15 "Invalid" ;
VAL_ 1030 DCDC_FaultLevel 5 "Level5,Fatal fault" 4 "Level4,Serious fault" 3 "Level3,General fault" 2 "Level2,Minor fault" 1 "Level1,slight fault" 0 "No Fault" ;
VAL_ 1030 DCFC_FaultLevel 0 "No Fault" 2 "Level2: Serous Fault " 3 "Level3: Fatal Fault" ;
VAL_ 522 Rolling_Counter_0x20A 15 "Invalid" ;
VAL_ 522 DCFC_Voltage_Input 1023 "Invalid" ;
VAL_ 522 DCDC_PTC_Temp_Reserved 255 "Invalid" ;
VAL_ 522 DCFC_Neg_Temp_BusBar 255 "Invalid" ;
VAL_ 522 DCFC_STATE 0 "DCFC_Contactors_Open_e" 1 "DCFC_Contactors_Closing" 2 "DCFC_Contactors_Close" 3 "DCFC_Contactors_Opening" 4 "DCFC_Contactors_Weld" 7 "DCFC_SNA" ;
VAL_ 522 DCFC_PTC_Status_Reserved 3 "invalid" 2 "reserved" 1 "ON" 0 "OFF" ;
VAL_ 992 Rolling_Counter_0x3E0 15 "Invalid" ;
VAL_ 992 EVCC_IPC_Ack_ChgSche_stt 0 "Disabled" 1 "Enabled" 2 "Reserved" 3 "Invalid" ;
VAL_ 725 Rolling_Counter_0x2D5 15 "Invalid" ;
VAL_ 725 VCU_DCDC_Output_REQ 0 "Disable" 1 "Enable" ;
VAL_ 725 VCU_DCDC_OutVoltage_REQ 65535 "Invalid" ;
VAL_ 725 VCU_DCDCAllowedPower 65535 "Invalid" ;
VAL_ 673 Rolling_Counter_0x2A1 15 "Invalid" ;
VAL_ 673 EVCC_ChargeGunSts 1 "Plug In" 0 "no Plug in" ;
VAL_ 673 EVCC_VehicleFailureLevel 0 "Normal" 1 "Slight Fault" 2 "Minor fault" 3 "General fault" 4 "Serious Fault" 5 "Fatal fault" ;
VAL_ 673 EVCC_ChargeMode 2 "DC Mode " 1 "AC Mode " 0 "Default" ;
VAL_ 673 EVCC_CP_Sts 12 "F~" 11 "E~" 10 "D~" 9 "C~" 8 "B~" 7 "A~" 6 "F" 5 "E" 4 "D" 3 "C" 2 "B" 1 "A" 0 "No CP" ;
VAL_ 673 EVCC_PP_Value 7 "CC GND" 6 "1500" 5 "680" 4 "220" 3 "100" 2 "Connection" 1 "Half Connection " 0 "No Connection" ;
VAL_ 673 EVCC_Lock_Sts 4 "Error" 3 "Unlocking" 2 "Locked" 1 "Locking " 0 "Unlock" ;
VAL_ 673 EVCC_DCFCPortsTempErr 1 "Error" 0 "Normal" ;
VAL_ 682 Rolling_Counter_0x2AA 15 "Invalid" ;
VAL_ 682 EVCC_PLC_CommSts 2 "PLC communication Fail" 1 "PLC communication Success" 0 "No PLC communication" ;
VAL_ 682 EVCC_DC_ChargeProcess 10 "Charge Error" 9 "After Charge" 8 "Charge Stoping" 7 "Charging" 6 "Precharge waiting" 5 "Insulation Monitor From Charge Station" 4 "Information exchange" 3 "Charging authentication" 2 "TCP Connecting" 1 "PLC Linking" 0 "No Charge" ;
VAL_ 682 EVCC_BMS_InsulationMonReq 1 "off" 0 "on" ;
VAL_ 683 Rolling_Counter_0x2AB 15 "Invalid" ;
VAL_ 683 EVCC_OBC_PowerReq 127 "Invalid" ;
VAL_ 683 EVCC_OBC_VoltageReq 8191 "Invalid" ;
VAL_ 683 EVCC_OBC_CurrentReq 1023 "Invalid" ;
VAL_ 683 EVCC_OBC_Control 1 "enable" 0 "disable" ;
VAL_ 683 EVCC_AC_ChargeSts 4 "Charge Err" 3 "Afer Charge" 2 "Charge Stoping" 1 "Charging " 0 "No charge" ;
VAL_ 537 Rolling_Counter_0x219 15 "Invalid" ;
VAL_ 537 EVCC_ChargeAllow 1 "Allow " 0 "Not allow" ;
VAL_ 757 Rolling_Counter_0x2F5 15 "Invalid" ;
VAL_ 757 EVCC_Charge_Control 0 "Request Open" 1 "Request Close" ;
VAL_ 757 EVCC_DC_chargeSock_temp1 2047 "Invaild" ;
VAL_ 757 EVCC_DC_chargeSock_temp2 2047 "Invaild" ;
VAL_ 757 EVCC_ChargeIndicatorCtrlSts_Red 3 "Red light always on" 2 "Green light always on" 1 "green light flashing" 0 "closed" ;
VAL_ 757 EVCC_ChargeIndicatorSts_Red 1 "Error" 0 "NO Error" ;
VAL_ 854 Rolling_Counter_0x356 15 "Invalid" ;
VAL_ 854 OBC_WorkStatus 7 "CHG_LOCK_FAULT_STATE " 6 "CHG_RECV_FAULT_STATE " 5 " CHG_SLEEP_STATE" 4 "CHG_CHARG_OVER_STATE" 3 "CHG_CHARG_CV_STATE" 2 "CHG_CHARG_CC_STATE" 1 "CHG_STANDBY_STATE" 0 "Initial" ;
VAL_ 854 OBC_Sys_STS 3 "fault" 2 "warning" 1 "ok" 0 "init" ;
VAL_ 854 OBC_StartStatus 1 "Close Output" 0 "Start Output" ;
VAL_ 870 Rolling_Counter_0x366 15 "Invalid" ;
VAL_ 870 OBC_Charge_air_temp 255 "Invalid" ;
VAL_ 870 OBC_Temp 255 "Invalid" ;
VAL_ 629 Rolling_Counter_0x275 15 "Invalid" ;
VAL_ 629 OBC_OUT_DC_V 65535 "Invalid" ;
VAL_ 629 OBC_OUT_DC_I 16383 "Invalid" ;
VAL_ 629 OBC_DCCharge_line_V 65535 "Invalid" ;
VAL_ 630 Rolling_Counter_0x276 15 "Invalid" ;
VAL_ 630 OBC_Input_U 65535 "Invalid" ;
VAL_ 630 OBC_IN_Main_V 65535 "Invalid" ;
VAL_ 630 OBC_IN_Main_I 1023 "Invalid" ;
VAL_ 662 Rolling_Counter_0x296 15 "Invalid" ;
VAL_ 662 OBC_MaxOutputChgU 8191 "Invalid" ;
VAL_ 662 OBC_MaxOutputChgI 511 "Invalid" ;
VAL_ 662 OBC_MaxOutputPwr 127 "Invalid" ;
VAL_ 1142 OBC_FailGrade_ERR 5 "Level5,Fatal fault" 4 "Level4,Serious fault" 3 "Level3,General fault" 2 "Level2,Minor fault" 1 "Level1,slight fault" 0 "No Fault" ;
VAL_ 1142 OBC_ErrorFlag 11 "FAULT_MUTEX " 10 "FAULT_OUT_OV " 9 "FAULT_OUT_UV" 8 "FAULT_PFC_UVPFC" 7 "FAULT_PFC_OVPFC" 6 "FAULT_IN_OV" 5 "FAULT_IN_UV" 4 "FAULT_COMM_OUT" 3 "FAULT_OUT_OC " 2 " FAULT_OTP_ALL " 1 "FAULT_OTP_RT " 0 "Initial" ;
VAL_ 1142 OBC_Hardware_ERR 1 "Error" 0 "Normal" ;
VAL_ 1142 OBC_OTemp_ERR 2 "Level2 - stop" 1 "Level1 - limit" 0 "Normal" ;
VAL_ 1142 OBC_OCofOut_ERR 1 "Error" 0 "Normal" ;
VAL_ 1142 OBC_CANcomoverT_ERR 1 "Error" 0 "Normal" ;
VAL_ 1142 OBC_UVofIn_ERR 1 "Error" 0 "Normal" ;
VAL_ 1142 OBC_OVofIn_ERR 1 "Error" 0 "Normal" ;
VAL_ 1142 OBC_OVofPFC_ERR 1 "Error" 0 "Normal" ;
VAL_ 1142 OBC_UVofPFC_ERR 1 "Error" 0 "Normal" ;
VAL_ 1142 OBC_UVofOut_ERR 1 "Error" 0 "Normal" ;
VAL_ 1142 OBC_OVofOut_ERR 1 "Error" 0 "Normal" ;
